VERSION "created by canmatrix"

NS_ :

BS_:

BU_: HUT T_BOX GW XBOX_D CEM Tester

BO_ 653 BCM7: 8 CEM
 SG_ SecRowLeSeatVentSts : 15|2@0+ (1,0) [0|3] "" HUT
 SG_ SecRowRiSeatVentSts : 13|2@0+ (1,0) [0|3] "" HUT

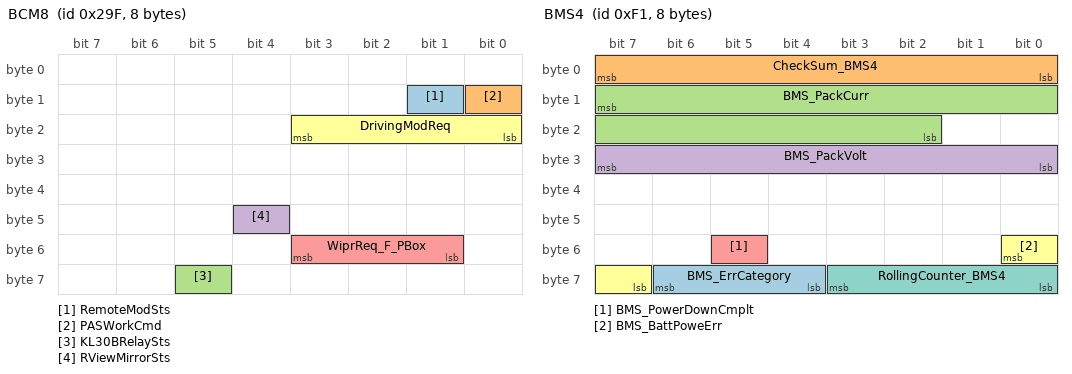
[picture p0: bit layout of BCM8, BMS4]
BO_ 671 BCM8: 8 CEM
 SG_ RemoteModSts : 9|1@0+ (1,0) [0|1] "1.0" HUT,T_BOX
 SG_ PASWorkCmd : 8|1@0+ (1,0) [0|1] "" HUT
 SG_ KL30BRelaySts : 61|1@0+ (1,0) [0|1] "" HUT
 SG_ RViewMirrorSts : 44|1@0+ (1,0) [0|1] "" HUT
 SG_ WiprReq_F_PBox : 51|3@0+ (1,0) [0|7] "" HUT
 SG_ DrivingModReq : 19|4@0+ (1,0) [0|15] "" HUT

BO_ 845 BCM18: 8 CEM
 SG_ ColMemPosnSetSwtFB : 15|3@0+ (1,0) [0|7] "" HUT

BO_ 241 BMS4: 8 GW
 SG_ BMS_ErrCategory : 62|3@0+ (1,0) [0|7] "" HUT
 SG_ CheckSum_BMS4 : 7|8@0+ (1,0) [0|255] "" HUT
 SG_ BMS_PackCurr : 15|14@0+ (0.2,-1000) [-1000|1000] "A" HUT
 SG_ BMS_PackVolt : 31|8@0+ (2,0) [0|490] "V" HUT
 SG_ BMS_PowerDownCmplt : 53|1@0+ (1,0) [0|1] "" HUT
 SG_ BMS_BattPoweErr : 48|2@0+ (1,0) [0|3] "" HUT
 SG_ RollingCounter_BMS4 : 59|4@0+ (1,0) [0|15] "" HUT

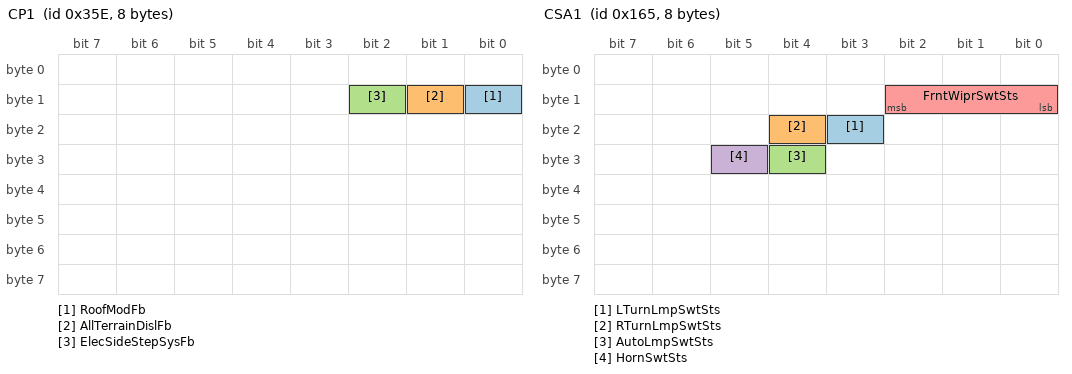
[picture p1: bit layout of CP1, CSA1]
BO_ 862 CP1: 8 CEM
 SG_ RoofModFb : 8|1@0+ (1,0) [0|1] "" HUT
 SG_ AllTerrainDislFb : 9|1@0+ (1,0) [0|1] "" HUT
 SG_ ElecSideStepSysFb : 10|1@0+ (1,0) [0|1] "" HUT

BO_ 350 CR_FD1: 64 GW
 SG_ CR_FCTA_Resp : 79|1@0+ (1,0) [0|1] "" HUT
 SG_ CR_FCTB_Resp : 78|1@0+ (1,0) [0|1] "" HUT
 SG_ CR_BliSts : 86|1@0+ (1,0) [0|1] "" HUT
 SG_ FCTA_Warn : 75|1@0+ (1,0) [0|1] "" HUT
 SG_ FCTBTrig : 83|1@0+ (1,0) [0|1] "" HUT
 SG_ FCTA_B_FuncSts : 77|2@0+ (1,0) [0|3] "" HUT
 SG_ FCTA_B_TTC : 110|6@0+ (0.1,0) [0|6.3] "s" HUT

BO_ 357 CSA1: 8 GW
 SG_ LTurnLmpSwtSts : 19|1@0+ (1,0) [0|1] "" HUT
 SG_ RTurnLmpSwtSts : 20|1@0+ (1,0) [0|1] "" HUT
 SG_ AutoLmpSwtSts : 28|1@0+ (1,0) [0|1] "" HUT,T_BOX
 SG_ HornSwtSts : 29|1@0+ (1,0) [0|1] "" HUT
 SG_ FrntWiprSwtSts : 10|3@0+ (1,0) [0|7] "" HUT

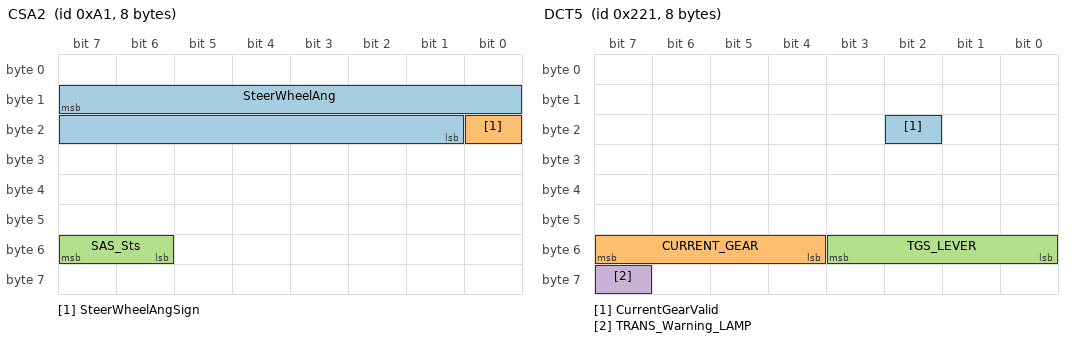
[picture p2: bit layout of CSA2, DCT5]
BO_ 161 CSA2: 8 GW
 SG_ SteerWheelAng : 15|15@0+ (0.1,0) [0|780] "deg" HUT,T_BOX
 SG_ SteerWheelAngSign : 16|1@0+ (1,0) [0|1] "" HUT,T_BOX
 SG_ SAS_Sts : 55|2@0+ (1,0) [0|3] "" HUT,T_BOX

BO_ 580 CSA3: 8 GW
 SG_ MenuReturnSwtSts : 49|2@0+ (1,0) [0|3] "" HUT
 SG_ SteerWheelHeatdSts : 40|1@0+ (1,0) [0|1] "" HUT
 SG_ HomeSwtSts : 51|2@0+ (1,0) [0|3] "" HUT
 SG_ MuteSwtSts : 53|2@0+ (1,0) [0|3] "" HUT
 SG_ CustomSwtSts : 55|2@0+ (1,0) [0|3] "" HUT
 SG_ PageUpSwtSts : 15|2@0+ (1,0) [0|3] "" HUT
 SG_ PageDwnSwtSts : 13|2@0+ (1,0) [0|3] "" HUT
 SG_ PageLSwtSts : 11|2@0+ (1,0) [0|3] "" HUT
 SG_ PageRSwtSts : 9|2@0+ (1,0) [0|3] "" HUT
 SG_ SeekUpSwtSts : 63|2@0+ (1,0) [0|3] "" HUT
 SG_ SeekDwnSwtSts : 61|2@0+ (1,0) [0|3] "" HUT
 SG_ AdjVolUpSwtSts : 23|2@0+ (1,0) [0|3] "" HUT
 SG_ AdjVolDwnSwtSts : 21|2@0+ (1,0) [0|3] "" HUT
 SG_ VRSwtSts : 19|2@0+ (1,0) [0|3] "" HUT
 SG_ EnterSwtSts : 31|2@0+ (1,0) [0|3] "" HUT
 SG_ EnterSwtSts_Mmed : 27|2@0+ (1,0) [0|3] "" HUT
 SG_ CustomSwtSts_Mmed : 39|2@0+ (1,0) [0|3] "" HUT
 SG_ IpMenuSwtSts : 42|2@0+ (1,0) [0|3] "" HUT

BO_ 566 DCT_FD4: 64 TCU
 SG_ CheckSum_DCT7 : 71|8@0+ (1,0) [0|255] "" HUT
 SG_ TrsmStNID : 106|3@0+ (1,0) [0|7] "" HUT
 SG_ DCT_RaceModeSts : 74|3@0+ (1,0) [0|7] "" HUT
 SG_ TRANS_OIL_TEMP : 87|8@0+ (1,-40) [-40|214] "Ã¢Â„Âƒ" HUT
 SG_ DCT_PrsBrk_Warn : 95|2@0+ (1,0) [0|3] "" HUT
 SG_ DCT_ShftNotAlwd_Warn : 93|2@0+ (1,0) [0|3] "" HUT
 SG_ DCT_ShftRecom_M : 91|2@0+ (1,0) [0|3] "" HUT
 SG_ DrvWarnMsg : 103|3@0+ (1,0) [0|7] "" HUT
 SG_ DrvFaiMsg : 100|4@0+ (1,0) [0|15] "" HUT
 SG_ DrvModDisp : 111|3@0+ (1,0) [0|7] "" HUT
 SG_ DrvModDispSts : 108|2@0+ (1,0) [0|3] "" HUT
 SG_ DrvAutoGearDisp : 127|4@0+ (1,0) [0|15] "" HUT,T_BOX
 SG_ DrvGearDispSts : 119|2@0+ (1,0) [0|3] "" HUT
 SG_ RollingCounter_DCT7 : 123|4@0+ (1,0) [0|15] "" HUT

BO_ 166 DCT3: 8 GW
 SG_ TgtEngSpdIP : 47|12@0+ (2,0) [0|8190] "RPM" HUT
 SG_ TgtEngSpdIPValid : 50|1@0+ (1,0) [0|1] "" HUT

BO_ 545 DCT5: 8 GW
 SG_ CurrentGearValid : 18|1@0+ (1,0) [0|1] "" HUT
 SG_ CURRENT_GEAR : 55|4@0+ (1,0) [0|15] "" HUT,T_BOX
 SG_ TGS_LEVER : 51|4@0+ (1,0) [0|15] "" HUT,T_BOX
 SG_ TRANS_Warning_LAMP : 63|1@0+ (1,0) [0|1] "" HUT

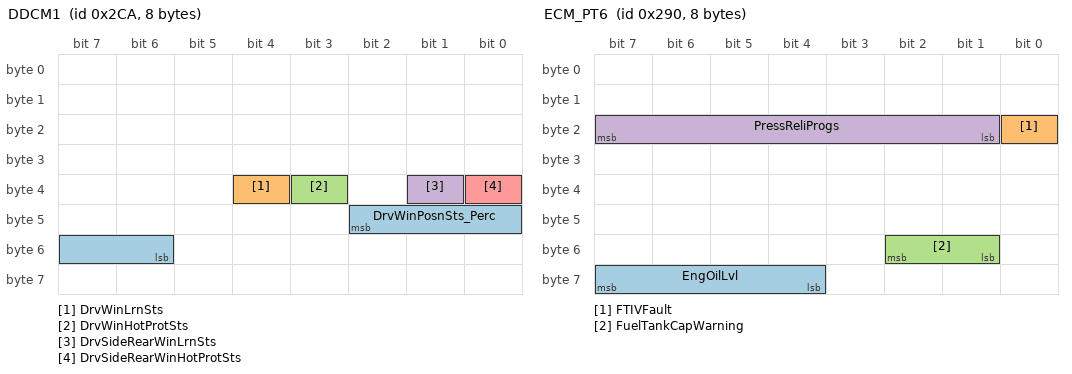
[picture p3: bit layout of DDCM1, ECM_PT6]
BO_ 714 DDCM1: 8 GW
 SG_ DrvWinPosnSts_Perc : 42|5@0+ (1,0) [0|31] "" HUT,T_BOX
 SG_ DrvWinLrnSts : 36|1@0+ (1,0) [0|1] "" HUT,T_BOX
 SG_ DrvWinHotProtSts : 35|1@0+ (1,0) [0|1] "" HUT,T_BOX
 SG_ DrvSideRearWinLrnSts : 33|1@0+ (1,0) [0|1] "" HUT,T_BOX
 SG_ DrvSideRearWinHotProtSts : 32|1@0+ (1,0) [0|1] "" HUT,T_BOX

BO_ 759 DDCM3: 8 GW
 SG_ DrvSideRearWinPosnSts_Perc : 15|5@0+ (1,0) [0|31] "" HUT,T_BOX

BO_ 589 DMS_FD1: 64 HUT
 SG_ DrowsnsLvl : 13|3@0+ (1,0) [0|7] "" CEM
 SG_ DrowsnsLvlQlty : 10|7@0+ (1,0) [0|100] "%" CEM
 SG_ GenderSts : 36|2@0+ (1,0) [0|3] "" CEM
 SG_ GenderStsQlty : 47|7@0+ (1,0) [0|100] "%" CEM
 SG_ ExprsnSts : 34|3@0+ (1,0) [0|7] "" GW
 SG_ Checksum_DMS2 : 71|8@0+ (1,0) [0|255] "" GW
 SG_ DistrctnLvl_ACC : 95|3@0+ (1,0) [0|7] "" GW
 SG_ DistrctnLvlQlty_ACC : 79|7@0+ (1,0) [0|100] "%" GW
 SG_ DrowsnsLvl_ACC : 92|3@0+ (1,0) [0|7] "" GW
 SG_ DrowsnsLvlQlty_ACC : 87|7@0+ (1,0) [0|100] "%" GW
 SG_ RollingCounter_DMS2 : 123|4@0+ (1,0) [0|15] "" GW
 SG_ Checksum_DMS3 : 135|8@0+ (1,0) [0|255] "" GW
 SG_ HeadPosnX : 143|11@0+ (1,-500) [-500|1000] "mm" GW
 SG_ HeadPosnY : 148|11@0+ (1,-500) [-500|500] "mm" GW
 SG_ HeadPosnZ : 153|11@0+ (1,-500) [-500|500] "mm" GW
 SG_ HeadPosQlty : 174|7@0+ (1,0) [0|100] "%" GW
 SG_ RollingCounter_DMS3 : 187|4@0+ (1,0) [0|15] "" GW
 SG_ GazePosnX : 207|11@0+ (1,-500) [-500|1000] "mm" GW
 SG_ GazePosnY : 212|11@0+ (1,-500) [-500|500] "mm" GW
 SG_ GazePosnZ : 217|11@0+ (1,-500) [-500|500] "mm" GW
 SG_ Checksum_DMS5 : 263|8@0+ (1,0) [0|255] "" GW
 SG_ DMSSts : 303|3@0+ (1,0) [0|7] "" GW
 SG_ HeadDetn : 288|1@0+ (1,0) [0|1] "" GW
 SG_ HeadYawAng : 271|8@0+ (1,-75) [-75|75] "degree" GW
 SG_ HeadPitchAng : 279|8@0+ (1,-25) [-25|45] "degree" GW
 SG_ HeadRollAng : 287|8@0+ (1,-45) [-45|45] "degree" GW
 SG_ HeadRotAngQlty : 295|7@0+ (1,0) [0|100] "%" GW
 SG_ RollingCounter_DMS5 : 315|4@0+ (1,0) [0|15] "" GW
 SG_ Checksum_DMS6 : 327|8@0+ (1,0) [0|255] "" GW
 SG_ LEyeOpenSts : 375|2@0+ (1,0) [0|3] "" GW
 SG_ LEyeOpenStsQlty : 351|7@0+ (1,0) [0|100] "%" GW
 SG_ REyeOpenSts : 373|2@0+ (1,0) [0|3] "" GW
 SG_ REyeOpenStsQlty : 359|7@0+ (1,0) [0|100] "%" GW
 SG_ RobustGazeYawAng : 335|8@0+ (1,-90) [-90|90] "degree" GW
 SG_ RobustGazePitchAng : 343|8@0+ (1,-90) [-90|90] "degree" GW
 SG_ RobustGazeAngQlty : 367|7@0+ (1,0) [0|100] "%" GW
 SG_ DrvBehvSts : 370|3@0+ (1,0) [0|7] "" GW
 SG_ RollingCounter_DMS6 : 379|4@0+ (1,0) [0|15] "" GW

BO_ 705 DSM1: 8 CEM
 SG_ ChairMemPosnSetSwtFB : 11|3@0+ (1,0) [0|7] "" HUT

BO_ 748 DVR_FD1: 64 HUT
 SG_ DVR_360VideoCaptureReq : 9|1@0+ (1,0) [0|1] "" GW
 SG_ DVRRemtCnSts : 28|3@0+ (1,0) [0|7] "" T_BOX
 SG_ DVRSN : 71|48@0+ (1,0) [0|1] "" T_BOX
 SG_ DVRSts : 15|4@0+ (1,0) [0|15] "" GW

BO_ 656 ECM_PT6: 8 GW
 SG_ EngOilLvl : 63|4@0+ (1,0) [0|15] "" HUT
 SG_ FTIVFault : 16|1@0+ (1,0) [0|1] "" HUT
 SG_ FuelTankCapWarning : 50|2@0+ (1,0) [0|3] "" HUT
 SG_ PressReliProgs : 23|7@0+ (1,0) [0|100] "%" HUT

BO_ 273 ECM1: 8 GW
 SG_ EMS_AuthenResult : 25|2@0+ (1,0) [0|3] "" HUT
 SG_ EngSpd : 47|16@0+ (0.125,0) [0|8191.875] "rpm" HUT,T_BOX
 SG_ EngSpdVldty : 63|2@0+ (1,0) [0|2] "" HUT,T_BOX
 SG_ EngSpd_PHEV : 47|16@0+ (0.125,0) [0|8191.875] "rpm" HUT,T_BOX
 SG_ EngSpdVldty_PHEV : 63|2@0+ (1,0) [0|2] "" HUT,T_BOX

BO_ 723 ECM11: 8 GW
 SG_ EngSpd_ForIP : 47|16@0+ (0.125,0) [0|8191.875] "rpm" HUT
 SG_ EWP_Err : 32|1@0+ (1,0) [0|1] "" HUT

BO_ 949 ECM19: 8 GW
 SG_ ECM_VIN : 7|64@0+ (1,0) [0|1.84467440737096E+019] "" HUT

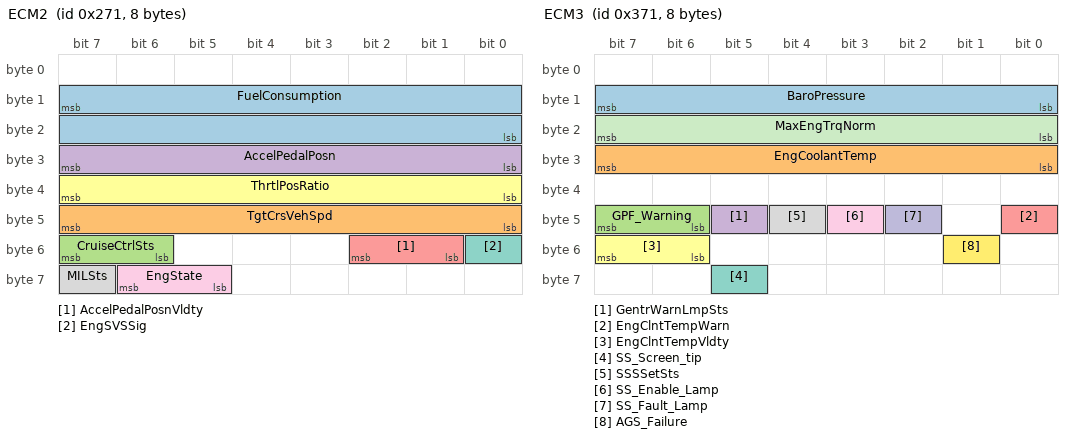
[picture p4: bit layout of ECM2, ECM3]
BO_ 625 ECM2: 8 GW
 SG_ FuelConsumption : 15|16@0+ (2,0) [0|131070] "ÃŽÂ¼l" HUT
 SG_ TgtCrsVehSpd : 47|8@0+ (1,0) [0|255] "kphmph" HUT
 SG_ CruiseCtrlSts : 55|2@0+ (1,0) [0|2] "" HUT
 SG_ AccelPedalPosn : 31|8@0+ (0.3937,0) [0|100.3935] "%" HUT
 SG_ AccelPedalPosnVldty : 50|2@0+ (1,0) [0|2] "" HUT
 SG_ ThrtlPosRatio : 39|8@0+ (0.3937,0) [0|99.9998] "%" HUT
 SG_ EngSVSSig : 48|1@0+ (1,0) [0|1] "" HUT
 SG_ MILSts : 63|1@0+ (1,0) [0|1] "" HUT
 SG_ EngState : 62|2@0+ (1,0) [0|3] "" HUT,XBOX_D,T_BOX

BO_ 951 ECM20: 8 GW
 SG_ ECM_VehDstBackup : 7|24@0+ (0.1,0) [0|999999.9] "Km" HUT

BO_ 881 ECM3: 8 GW
 SG_ BaroPressure : 15|8@0+ (0.59,0) [0|149.86] "kPa" HUT
 SG_ EngCoolantTemp : 31|8@0+ (0.75,-48) [-48|143.25] "Deg C" HUT,T_BOX
 SG_ GPF_Warning : 47|2@0+ (1,0) [0|3] "" HUT
 SG_ GentrWarnLmpSts : 45|1@0+ (1,0) [0|1] "" HUT
 SG_ EngClntTempWarn : 40|1@0+ (1,0) [0|1] "" HUT,T_BOX
 SG_ EngClntTempVldty : 55|2@0+ (1,0) [0|2] "" HUT,T_BOX
 SG_ SS_Screen_tip : 61|1@0+ (1,0) [0|1] "" HUT
 SG_ SSSSetSts : 44|1@0+ (1,0) [0|1] "" HUT
 SG_ SS_Enable_Lamp : 43|1@0+ (1,0) [0|1] "" HUT
 SG_ SS_Fault_Lamp : 42|1@0+ (1,0) [0|1] "" HUT
 SG_ MaxEngTrqNorm : 23|8@0+ (5,0) [0|650] "Nm" HUT
 SG_ AGS_Failure : 49|1@0+ (1,0) [0|1] "" HUT

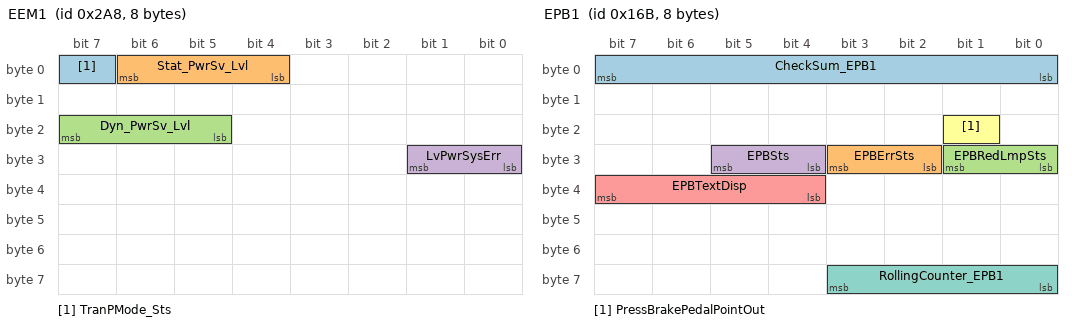
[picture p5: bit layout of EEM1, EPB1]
BO_ 680 EEM1: 8 CEM
 SG_ TranPMode_Sts : 7|1@0+ (1,0) [0|1] "" HUT,T_BOX
 SG_ Stat_PwrSv_Lvl : 6|3@0+ (1,0) [0|7] "" HUT
 SG_ Dyn_PwrSv_Lvl : 23|3@0+ (1,0) [0|7] "" HUT
 SG_ LvPwrSysErr : 25|2@0+ (1,0) [0|3] "" HUT

BO_ 338 ELD1: 8 GW
 SG_ FrntELDLckSts : 35|4@0+ (1,0) [0|15] "" HUT
 SG_ RearELDLckSts : 39|4@0+ (1,0) [0|15] "" HUT

BO_ 363 EPB1: 8 GW
 SG_ CheckSum_EPB1 : 7|8@0+ (1,0) [0|255] "" HUT
 SG_ EPBErrSts : 27|2@0+ (1,0) [0|3] "" HUT
 SG_ EPBRedLmpSts : 25|2@0+ (1,0) [0|3] "" HUT
 SG_ EPBSts : 29|2@0+ (1,0) [0|3] "" HUT
 SG_ EPBTextDisp : 39|4@0+ (1,0) [0|15] "" HUT
 SG_ PressBrakePedalPointOut : 17|1@0+ (1,0) [0|1] "" HUT
 SG_ RollingCounter_EPB1 : 59|4@0+ (1,0) [0|15] "" HUT

BO_ 327 EPS_FD1: 64 GW
 SG_ CheckSum_EPS1 : 7|8@0+ (1,0) [0|255] "" HUT
 SG_ EPS_FailSts : 13|2@0+ (1,0) [0|3] "" HUT
 SG_ EPS_SteerMod : 55|3@0+ (1,0) [0|7] "" HUT
 SG_ SteerCorrnRmn : 63|2@0+ (1,0) [0|3] "" HUT
 SG_ SteerCorrnResp : 61|1@0+ (1,0) [0|1] "" HUT
 SG_ RollingCounter_EPS1 : 59|4@0+ (1,0) [0|15] "" HUT

BO_ 771 ESCL2: 8 GW
 SG_ RotSteerWheel : 21|1@0+ (1,0) [0|1] "" HUT

BO_ 311 ESP_FD2: 64 ESP
 SG_ CheckSum_ESP2 : 71|8@0+ (1,0) [0|255] "" HUT
 SG_ HDCFault : 89|2@0+ (1,0) [0|3] "" HUT
 SG_ HDCCtrl : 91|2@0+ (1,0) [0|3] "" HUT
 SG_ AVHErrSts : 99|2@0+ (1,0) [0|3] "" HUT
 SG_ AVHSts : 101|2@0+ (1,0) [0|3] "" HUT
 SG_ CDPActv : 103|1@0+ (1,0) [0|1] "" HUT
 SG_ DrivingModDis : 119|5@0+ (1,0) [0|31] "" HUT
 SG_ DrivingModReq_ESP : 96|5@0+ (1,0) [0|31] "" HUT
 SG_ Shift_N_Warn : 114|1@0+ (1,0) [0|1] "" HUT
 SG_ Over_Spd_Warn : 107|1@0+ (1,0) [0|1] "" HUT
 SG_ FourL_Warn : 106|1@0+ (1,0) [0|1] "" HUT
 SG_ TAB_Sts : 113|2@0+ (1,0) [0|3] "" HUT
 SG_ RollingCounter_ESP2 : 123|4@0+ (1,0) [0|15] "" HUT
 SG_ CheckSum_ESP1 : 135|8@0+ (1,0) [0|255] "" HUT
 SG_ ESPFuncOffSts : 140|1@0+ (1,0) [0|1] "" HUT
 SG_ ESPActvInfoLmp : 141|1@0+ (1,0) [0|1] "" HUT
 SG_ ESPFailSts : 143|1@0+ (1,0) [0|1] "" HUT
 SG_ IMC_Actv : 175|1@0+ (1,0) [0|1] "" HUT
 SG_ RollingCounter_ESP1 : 187|4@0+ (1,0) [0|15] "" HUT
 SG_ CheckSum_ABS3 : 327|8@0+ (1,0) [0|255] "" HUT
 SG_ ABSActv : 347|1@0+ (1,0) [0|1] "" HUT,T_BOX
 SG_ ABSFailSts : 335|1@0+ (1,0) [0|1] "" HUT,T_BOX
 SG_ EBDFailSts : 334|1@0+ (1,0) [0|1] "" HUT
 SG_ VehSpdVld : 333|1@0+ (1,0) [0|1] "" HUT,T_BOX
 SG_ VehSpd : 332|13@0+ (0.05625,0) [0|299.98125] "kph" HUT,T_BOX
 SG_ VehOdoInfoSts : 346|1@0+ (1,0) [0|1] "" HUT
 SG_ VehOdoInfo : 345|10@0+ (1,0) [0|999] "m" HUT
 SG_ RollingCounter_ABS3 : 379|4@0+ (1,0) [0|15] "" HUT
 SG_ FreshnessValue_ESP_FD2 : 455|16@0+ (1,0) [0|65535] "" HUT
 SG_ MAC_Check_ESP_FD2 : 471|48@0+ (1,0) [0|281474976710655] "" HUT

BO_ 200 ESP11: 8 GW
 SG_ ESP_HMI_WarningOn : 41|2@0+ (1,0) [0|3] "" HUT
 SG_ WadeModeWarn : 45|2@0+ (1,0) [0|3] "" HUT

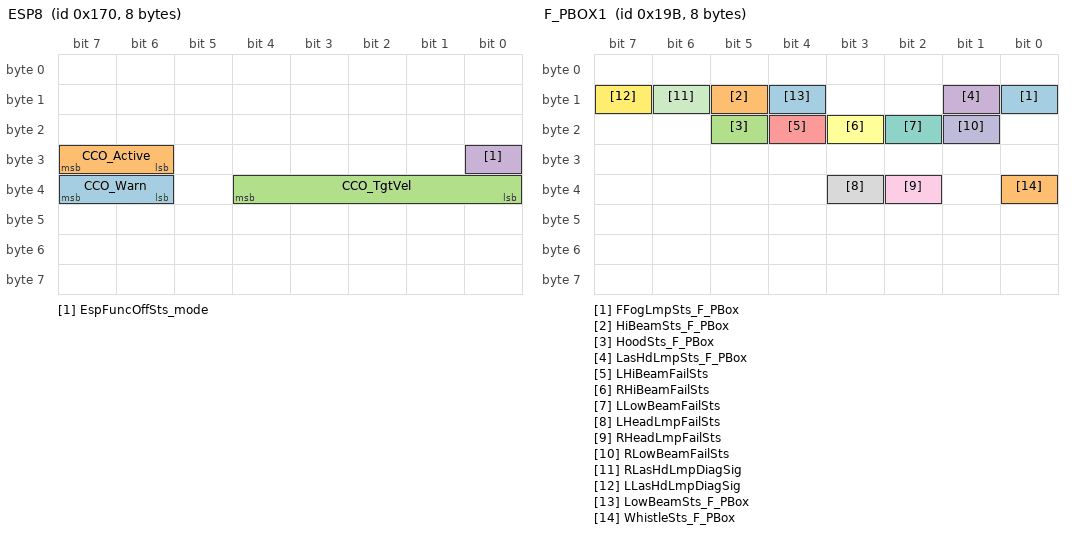
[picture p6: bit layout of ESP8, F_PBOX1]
BO_ 368 ESP8: 8 GW
 SG_ CCO_Warn : 39|2@0+ (1,0) [0|3] "" HUT
 SG_ CCO_Active : 31|2@0+ (1,0) [0|3] "" HUT
 SG_ CCO_TgtVel : 36|5@0+ (1,2.6) [2.6|33.6] "kph" HUT
 SG_ EspFuncOffSts_mode : 24|1@0+ (1,0) [0|1] "" HUT

BO_ 411 F_PBOX1: 8 CEM
 SG_ FFogLmpSts_F_PBox : 8|1@0+ (1,0) [0|1] "" HUT,T_BOX
 SG_ HiBeamSts_F_PBox : 13|1@0+ (1,0) [0|1] "" HUT,T_BOX
 SG_ HoodSts_F_PBox : 21|1@0+ (1,0) [0|1] "" HUT,T_BOX
 SG_ LasHdLmpSts_F_PBox : 9|1@0+ (1,0) [0|1] "" HUT
 SG_ LHiBeamFailSts : 20|1@0+ (1,0) [0|1] "" HUT,T_BOX
 SG_ RHiBeamFailSts : 19|1@0+ (1,0) [0|1] "" HUT,T_BOX
 SG_ LLowBeamFailSts : 18|1@0+ (1,0) [0|1] "" HUT,T_BOX
 SG_ LHeadLmpFailSts : 35|1@0+ (1,0) [0|1] "" HUT
 SG_ RHeadLmpFailSts : 34|1@0+ (1,0) [0|1] "" HUT
 SG_ RLowBeamFailSts : 17|1@0+ (1,0) [0|1] "" HUT,T_BOX
 SG_ RLasHdLmpDiagSig : 14|1@0+ (1,0) [0|1] "" HUT
 SG_ LLasHdLmpDiagSig : 15|1@0+ (1,0) [0|1] "" HUT
 SG_ LowBeamSts_F_PBox : 12|1@0+ (1,0) [0|1] "" HUT,T_BOX
 SG_ WhistleSts_F_PBox : 32|1@0+ (1,0) [0|1] "" HUT

BO_ 699 GW_FD1: 64 CEM
 SG_ U_BATT : 71|14@0+ (0.0009765625,3) [3|18] "V" HUT,T_BOX
 SG_ I_RANGE : 73|2@0+ (1,0) [0|3] "" HUT
 SG_ I_BATT : 87|16@0+ (1,-32768) [-32768|32767] "A" HUT
 SG_ SOC : 135|8@0+ (1,0) [0|100] "%" HUT,T_BOX
 SG_ SOH_SUL : 143|8@0+ (1,0) [0|100] "%" HUT
 SG_ SOC_STATE : 183|2@0+ (1,0) [0|3] "" HUT
 SG_ SOH_SUL_STATE : 181|2@0+ (1,0) [0|3] "" HUT
 SG_ OTA_UpgrdModSts : 343|2@0+ (1,0) [0|3] "" HUT,T_BOX
 SG_ CheckSum_GWM1 : 327|8@0+ (1,0) [0|255] "" HUT,T_BOX
 SG_ RollingCounter_GWM1 : 379|4@0+ (1,0) [0|15] "" HUT,T_BOX

BO_ 347 HAP_FD1: 64 GW
 SG_ APS_PrkgMod : 117|2@0+ (1,0) [0|3] "" HUT
 SG_ APS_ProcBar : 111|7@0+ (1,0) [0|127] "%" HUT
 SG_ APS_SwtSts : 104|1@0+ (1,0) [0|1] "" HUT
 SG_ APS_SlotDisp : 76|3@0+ (1,0) [0|7] "" HUT
 SG_ APS_SysSoundIndcn : 79|3@0+ (1,0) [0|7] "" HUT
 SG_ APS_PrkgTyp : 119|2@0+ (1,0) [0|3] "" HUT
 SG_ APS_TextDisp : 103|8@0+ (1,0) [0|255] "" HUT
 SG_ APS_WorkSts : 146|3@0+ (1,0) [0|7] "" HUT
 SG_ MEB_AVHReq : 168|1@0+ (1,0) [0|1] "" HUT
 SG_ APS_ESP_BrkDistance : 167|12@0+ (1,0) [0|4095] "cm" HUT
 SG_ LParaPrkgOutVald : 283|1@0+ (1,0) [0|1] "" HUT
 SG_ RParaPrkgOutVald : 282|1@0+ (1,0) [0|1] "" HUT
 SG_ HeadVertPrkgOutVald : 281|1@0+ (1,0) [0|1] "" HUT
 SG_ TailVertPrkgOutVald : 280|1@0+ (1,0) [0|1] "" HUT
 SG_ HAP_SwtDispCtrlCmd : 279|3@0+ (1,0) [0|7] "" HUT
 SG_ HAP_PrkgModCurrSts : 269|4@0+ (1,0) [0|15] "" HUT
 SG_ APS_MovgDirc : 295|2@0+ (1,0) [0|3] "" HUT
 SG_ ParallelSlotBtn_Ena : 367|2@0+ (1,0) [0|3] "" HUT
 SG_ VerticalSlotBtn_Ena : 365|2@0+ (1,0) [0|3] "" HUT
 SG_ ClockwiseBtn_Ena : 363|2@0+ (1,0) [0|3] "" HUT
 SG_ AnticlockwiseBtn_Ena : 361|2@0+ (1,0) [0|3] "" HUT
 SG_ SlotConfirmBtn_Ena : 375|2@0+ (1,0) [0|3] "" HUT
 SG_ HAVP_StopBtn_Ena : 329|2@0+ (1,0) [0|3] "" HUT
 SG_ HAVP_StartBtn_Ena : 331|2@0+ (1,0) [0|3] "" HUT
 SG_ HAVP_SelfParLotEnding_Ena : 339|2@0+ (1,0) [0|3] "" HUT
 SG_ PAVP_TextDis : 351|6@0+ (1,0) [0|63] "" HUT

BO_ 628 HAP_FD2: 64 GW
 SG_ AutoAVMSwtSet_Sts : 83|1@0+ (1,0) [0|1] "" HUT
 SG_ AVM_CurrSts : 79|2@0+ (1,0) [0|3] "" HUT
 SG_ GuidOvlSts : 95|2@0+ (1,0) [0|3] "" HUT
 SG_ FrntCamInpFailSts : 108|1@0+ (1,0) [0|1] "" HUT
 SG_ RearCamInpFailSts : 109|1@0+ (1,0) [0|1] "" HUT
 SG_ LeCamInpFailSts : 110|1@0+ (1,0) [0|1] "" HUT
 SG_ RiCamInpFailSts : 111|1@0+ (1,0) [0|1] "" HUT
 SG_ EolNotCmpltd : 107|1@0+ (1,0) [0|1] "" HUT
 SG_ OvlOpFailSts : 105|1@0+ (1,0) [0|1] "" HUT
 SG_ LaneCalSts : 101|2@0+ (1,0) [0|3] "" HUT
 SG_ RadarDispSts : 93|2@0+ (1,0) [0|3] "" HUT
 SG_ LaneCalFltSts : 99|3@0+ (1,0) [0|7] "" HUT
 SG_ AutoViewChgFuncSts : 84|1@0+ (1,0) [0|1] "" HUT
 SG_ CarMdlTrsprcySts : 103|2@0+ (1,0) [0|3] "" HUT
 SG_ CarMdlDispSts : 85|1@0+ (1,0) [0|1] "" HUT
 SG_ CurrCalResultSts : 96|1@0+ (1,0) [0|1] "" HUT
 SG_ MdlColrSts : 91|4@0+ (1,0) [0|15] "" HUT
 SG_ SigViewIndcn : 77|6@0+ (1,0) [0|63] "" HUT
 SG_ HAP_DispCmd : 127|1@0+ (1,0) [0|1] "" HUT
 SG_ AVM_3DAngSts : 104|9@0+ (1,0) [0|360] "deg" HUT
 SG_ MOD_WorkSts : 87|1@0+ (1,0) [0|1] "" HUT
 SG_ MOD_AlarmSts : 86|1@0+ (1,0) [0|1] "" HUT
 SG_ DVRWorkSts : 126|2@0+ (1,0) [0|3] "" HUT
 SG_ HAP_Hmi_Index : 143|4@0+ (1,0) [0|15] "" HUT

BO_ 664 HAP_FD3: 64 GW
 SG_ RPAS_NearBrrdstn : 15|8@0+ (1,0) [0|150] "" HUT
 SG_ HAVP_ProcRa : 23|7@0+ (1,0) [0|127] "" HUT
 SG_ APS_ObjRiSideAr1 : 79|4@0+ (1,0) [0|15] "" HUT
 SG_ APS_ObjRiSideAr2 : 75|4@0+ (1,0) [0|15] "" HUT
 SG_ APS_ObjRiSideAr3 : 87|4@0+ (1,0) [0|15] "" HUT
 SG_ APS_ObjRiSideAr4 : 83|4@0+ (1,0) [0|15] "" HUT
 SG_ APS_ObjRiSideAr5 : 95|4@0+ (1,0) [0|15] "" HUT
 SG_ APS_ObjLeSideAr1 : 91|4@0+ (1,0) [0|15] "" HUT
 SG_ APS_ObjLeSideAr2 : 103|4@0+ (1,0) [0|15] "" HUT
 SG_ APS_ObjLeSideAr3 : 99|4@0+ (1,0) [0|15] "" HUT
 SG_ APS_ObjLeSideAr4 : 111|4@0+ (1,0) [0|15] "" HUT
 SG_ APS_ObjLeSideAr5 : 107|4@0+ (1,0) [0|15] "" HUT
 SG_ APS_FRSideSnsrFailSts : 119|1@0+ (1,0) [0|1] "" HUT
 SG_ APS_FLSideSnsrFailSts : 118|1@0+ (1,0) [0|1] "" HUT
 SG_ APS_RRSideSnsrFailSts : 117|1@0+ (1,0) [0|1] "" HUT
 SG_ APS_RLSideSnsrFailSts : 116|1@0+ (1,0) [0|1] "" HUT
 SG_ SDW_SoundIndcn : 115|2@0+ (1,0) [0|3] "" HUT
 SG_ SDWActiveSts : 112|1@0+ (1,0) [0|1] "" HUT
 SG_ RPAS_ObjRRCornrAr1 : 143|4@0+ (1,0) [0|15] "" HUT
 SG_ RPAS_ObjRRCornrAr2 : 139|4@0+ (1,0) [0|15] "" HUT
 SG_ RPAS_ObjRRMidlAr1 : 151|4@0+ (1,0) [0|15] "" HUT
 SG_ RPAS_ObjRRMidlAr2 : 147|4@0+ (1,0) [0|15] "" HUT
 SG_ RPAS_ObjRLMidlAr1 : 159|4@0+ (1,0) [0|15] "" HUT
 SG_ RPAS_ObjRLMidlAr2 : 155|4@0+ (1,0) [0|15] "" HUT
 SG_ RPAS_ObjRLCornrAr1 : 167|4@0+ (1,0) [0|15] "" HUT
 SG_ RPAS_ObjRLCornrAr2 : 163|4@0+ (1,0) [0|15] "" HUT
 SG_ RPAS_RLCornrSnsrFailSts : 175|1@0+ (1,0) [0|1] "" HUT
 SG_ RPAS_RLMiddlSnsrFailSts : 174|1@0+ (1,0) [0|1] "" HUT
 SG_ RPAS_RRMiddlSnsrFailSts : 173|1@0+ (1,0) [0|1] "" HUT
 SG_ RPAS_RRCornrSnsrFailSts : 172|1@0+ (1,0) [0|1] "" HUT
 SG_ RPAS_WorkSts : 171|2@0+ (1,0) [0|3] "" HUT
 SG_ RPAS_SoundIndcn : 183|2@0+ (1,0) [0|3] "" HUT
 SG_ MEBWorkSts : 180|2@0+ (1,0) [0|3] "" HUT
 SG_ MEB_EnableSts : 178|1@0+ (1,0) [0|1] "" HUT
 SG_ FPAS_ObjFLCornrAr1 : 207|4@0+ (1,0) [0|15] "" HUT
 SG_ FPAS_ObjFLCornrAr2 : 203|4@0+ (1,0) [0|15] "" HUT
 SG_ FPAS_ObjFLMidlAr1 : 215|4@0+ (1,0) [0|15] "" HUT
 SG_ FPAS_ObjFLMidlAr2 : 211|4@0+ (1,0) [0|15] "" HUT
 SG_ FPAS_ObjFRMidlAr1 : 223|4@0+ (1,0) [0|15] "" HUT
 SG_ FPAS_ObjFRMidlAr2 : 219|4@0+ (1,0) [0|15] "" HUT
 SG_ FPAS_ObjFRCornrAr1 : 231|4@0+ (1,0) [0|15] "" HUT
 SG_ FPAS_ObjFRCornrAr2 : 227|4@0+ (1,0) [0|15] "" HUT
 SG_ FPAS_FLCornrSnsrFailSts : 239|1@0+ (1,0) [0|1] "" HUT
 SG_ FPAS_FLMiddlSnsrFailSts : 238|1@0+ (1,0) [0|1] "" HUT
 SG_ FPAS_FRMiddlSnsrFailSts : 237|1@0+ (1,0) [0|1] "" HUT
 SG_ FPAS_FRCornrSnsrFailSts : 236|1@0+ (1,0) [0|1] "" HUT
 SG_ FPAS_WorkSts : 235|2@0+ (1,0) [0|3] "" HUT
 SG_ FPAS_AutoModSts : 232|1@0+ (1,0) [0|1] "" HUT
 SG_ FPAS_SoundIndcn : 247|2@0+ (1,0) [0|3] "" HUT
 SG_ FPAS_NearBrrdstn : 242|7@0+ (1,0) [0|100] "" HUT
 SG_ APA_MenuDispCtrlCmd : 279|4@0+ (1,0) [0|15] "" HUT
 SG_ APA_FuncSts : 271|2@0+ (1,0) [0|3] "" HUT
 SG_ RADS_FuncSts : 267|2@0+ (1,0) [0|3] "" HUT
 SG_ FADS_FuncSts : 265|2@0+ (1,0) [0|3] "" HUT
 SG_ HAP_TextIconDispCtrl : 275|2@0+ (1,0) [0|3] "" HUT

BO_ 649 HAP_FD6: 64 GW
 SG_ HAP_RtCam_WorkSts : 61|2@0+ (1,0) [0|3] "" HUT
 SG_ HAP_RtSide_Obj1_ID : 15|4@0+ (1,0) [0|3] "" HUT
 SG_ HAP_RtSide_Obj1_type : 11|3@0+ (1,0) [0|7] "" HUT
 SG_ HAP_RtSide_Obj1_Confidence : 27|4@0+ (0.1,0) [0|1] "" HUT
 SG_ HAP_RtSide_Obj1_Ground_Pos_X : 23|12@0+ (0.01,0) [0|40] "m" HUT
 SG_ HAP_RtSide_Obj1_Ground_Pos_Y : 39|12@0+ (0.01,-20) [-20|20] "m" HUT
 SG_ HAP_RtSide_Obj2_ID : 79|4@0+ (1,0) [0|3] "" HUT
 SG_ HAP_RtSide_Obj2_type : 75|3@0+ (1,0) [0|7] "" HUT
 SG_ HAP_RtSide_Obj2_Confidence : 91|4@0+ (0.1,0) [0|1] "" HUT
 SG_ HAP_RtSide_Obj2_Ground_Pos_X : 87|12@0+ (0.01,0) [0|40] "m" HUT
 SG_ HAP_RtSide_Obj2_Ground_Pos_Y : 103|12@0+ (0.01,-20) [-20|20] "m" HUT
 SG_ HAP_RtSide_Obj3_ID : 143|4@0+ (1,0) [0|3] "" HUT
 SG_ HAP_RtSide_Obj3_type : 139|3@0+ (1,0) [0|7] "" HUT
 SG_ HAP_RtSide_Obj3_Confidence : 155|4@0+ (0.1,0) [0|1] "" HUT
 SG_ HAP_RtSide_Obj3_Ground_Pos_X : 151|12@0+ (0.01,0) [0|40] "m" HUT
 SG_ HAP_RtSide_Obj3_Ground_Pos_Y : 167|12@0+ (0.01,-20) [-20|20] "m" HUT
 SG_ HAP_RtSide_Obj4_ID : 207|4@0+ (1,0) [0|3] "" HUT
 SG_ HAP_RtSide_Obj4_type : 203|3@0+ (1,0) [0|7] "" HUT
 SG_ HAP_RtSide_Obj4_Confidence : 219|4@0+ (0.1,0) [0|1] "" HUT
 SG_ HAP_RtSide_Obj4_Ground_Pos_X : 215|12@0+ (0.01,0) [0|40] "m" HUT
 SG_ HAP_RtSide_Obj4_Ground_Pos_Y : 231|12@0+ (0.01,-20) [-20|20] "m" HUT
 SG_ USS_FLSide1_Status : 271|2@0+ (1,0) [0|3] "" HUT
 SG_ USS_FLSide1_Dist : 279|7@0+ (0.1,0) [0|12.6] "m" HUT
 SG_ USS_RLSide2_Status : 269|2@0+ (1,0) [0|3] "" HUT
 SG_ USS_RLSide2_Dist : 287|7@0+ (0.1,0) [0|12.6] "m" HUT
 SG_ USS_FRSide1_Status : 267|2@0+ (1,0) [0|3] "" HUT
 SG_ USS_FRSide1_Dist : 295|7@0+ (0.1,0) [0|12.6] "m" HUT
 SG_ USS_RRSide2_Status : 265|2@0+ (1,0) [0|3] "" HUT
 SG_ USS_RRSide2_Dist : 303|7@0+ (0.1,0) [0|12.6] "m" HUT

BO_ 667 HAP_FD7: 64 GW
 SG_ HAVP_LrngDst : 335|8@0+ (1,0) [0|200] "m" HUT
 SG_ HAVP_HUT_TextDisp : 343|6@0+ (1,0) [0|63] "" HUT

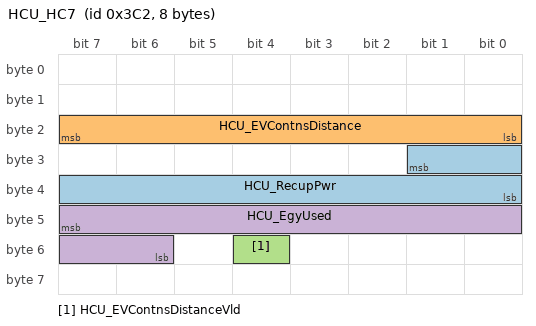
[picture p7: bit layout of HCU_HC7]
BO_ 962 HCU_HC7: 8 GW
 SG_ HCU_RecupPwr : 25|10@0+ (10,0) [0|10230] "Wh" HUT
 SG_ HCU_EVContnsDistance : 23|8@0+ (1,0) [0|254] "Km" HUT,T_BOX
 SG_ HCU_EVContnsDistanceVld : 52|1@0+ (1,0) [0|1] "" HUT
 SG_ HCU_EgyUsed : 47|10@0+ (0.01,0) [0|10.23] "KWh" HUT

CM_ SG_ 653 SecRowLeSeatVentSts "Left ventilation status of the second row";
CM_ SG_ 653 SecRowRiSeatVentSts "Right ventilation status of the second row";
CM_ SG_ 671 RemoteModSts "Remote mode status.IP Received";
CM_ SG_ 671 PASWorkCmd "PAS Work commandIP Received";
CM_ SG_ 671 KL30BRelaySts "KL30B Relay status.IP Received";
CM_ SG_ 671 RViewMirrorSts "Rear View Mirror FoldUnfold Status";
CM_ SG_ 671 WiprReq_F_PBox "Front windshield wiper operation request.";
CM_ SG_ 671 DrivingModReq "Driving mode request";
CM_ SG_ 845 ColMemPosnSetSwtFB "Column Memory Position Set Switch FeedBack";
CM_ SG_ 241 BMS_ErrCategory "BMS error Category";
CM_ SG_ 241 CheckSum_BMS4 "Use the checksum strategy from document Ã¢Â€ÂœEnd-to-End Communication Protection SpecificationÃ¢Â€ÂSC_CANFD:To HUT";
CM_ SG_ 241 BMS_PackCurr "Pack CurrentIP Received
positive value :discharging
negative value : charging";
CM_ SG_ 241 BMS_PackVolt "Pack VoltageIP Received";
CM_ SG_ 241 BMS_PowerDownCmplt "BMS power down complete .
BMS Inform HCU All Main relay have been open";
CM_ SG_ 241 BMS_BattPoweErr "Battray  Power Error";
CM_ SG_ 241 RollingCounter_BMS4 "Rolling counter BMS4SC_CANFD:To HUT";
CM_ SG_ 862 RoofModFb "Feedback of RoofMod";
CM_ SG_ 862 AllTerrainDislFb "Feedback of AllTerrainDisl";
CM_ SG_ 862 ElecSideStepSysFb "Feedback of ElecSideStepSys";
CM_ SG_ 350 CR_FCTA_Resp "Indicate FCTAÃ¯Â¼ÂˆFront Cross Traffic AlertÃ‚Â Ã¯Â¼Â‰ Switch statusL3Ã©ÂœÂ€Ã¨Â¦ÂÃ¥Â¢ÂžÃ¥ÂŠÂ ";
CM_ SG_ 350 CR_FCTB_Resp "Indicate FCTBÃ¯Â¼ÂˆFront Cross Traffic BrakeÃ‚Â Ã¯Â¼Â‰ Switch statusL3Ã©ÂœÂ€Ã¨Â¦ÂÃ¥Â¢ÂžÃ¥ÂŠÂ ";
CM_ SG_ 350 CR_BliSts "indicate Corner Radar blindness StatusL3Ã©ÂœÂ€Ã¨Â¦ÂÃ¥Â¢ÂžÃ¥ÂŠÂ ";
CM_ SG_ 350 FCTA_Warn "indicate FCTA Warning LevelL3Ã©ÂœÂ€Ã¨Â¦ÂÃ¥Â¢ÂžÃ¥ÂŠÂ ";
CM_ SG_ 350 FCTBTrig "indicate Corner Radar brake Status for ESPL3Ã©ÂœÂ€Ã¨Â¦ÂÃ¥Â¢ÂžÃ¥ÂŠÂ ";
CM_ SG_ 350 FCTA_B_FuncSts "Indicate FCTA_B fuction system working statusL3Ã©ÂœÂ€Ã¨Â¦ÂÃ¥Â¢ÂžÃ¥ÂŠÂ ";
CM_ SG_ 350 FCTA_B_TTC "FCTAFCTB TTC";
CM_ SG_ 357 LTurnLmpSwtSts "Left Turn Lamp Switch Status";
CM_ SG_ 357 RTurnLmpSwtSts "Right Turn Lamp Switch Status";
CM_ SG_ 357 AutoLmpSwtSts "Auto lamp switch status
When CSA detected auto light switch logical is ON, then signal is Auto,
When CSA detected light switch is different from auto lamp, then this signal is Non-Auto.Ã§ÂÂ¯Ã¥Â…Â‰Ã¥Â¼Â€Ã¥Â…Â³Ã¦Â˜Â¯Ã¥ÂÂ¦Ã¥Â¤Â„Ã¤ÂºÂŽautoÃ¦Â¡Â£Ã¥Â¼Â€Ã¥Â…Â³Ã¤Â¿Â¡Ã¥ÂÂ·IP Received";
CM_ SG_ 357 HornSwtSts "Horn switch States";
CM_ SG_ 357 FrntWiprSwtSts "Front Wiper Switch Status";
CM_ SG_ 161 SteerWheelAng "angle of steering wheel (raw data)";
CM_ SG_ 161 SteerWheelAngSign "sign of steering wheel angle (+-)
definition according to DIN 70000  ISO 8855
wheel position to left = positive
wheel position to right = negative
wheel position straightforward = 0 (positive)";
CM_ SG_ 161 SAS_Sts "Status of steering angle sensor";
CM_ SG_ 580 MenuReturnSwtSts "Menu Return Switch StatusIP Received";
CM_ SG_ 580 SteerWheelHeatdSts "Steer wheel heated statusCSA-LIN IFCom SWHM";
CM_ SG_ 580 HomeSwtSts "Home Switch StatusIP Received";
CM_ SG_ 580 MuteSwtSts "Mute Switch Status";
CM_ SG_ 580 CustomSwtSts "Custom Switch StatusIP Received";
CM_ SG_ 580 PageUpSwtSts "Page Up Switch StatusIP Received";
CM_ SG_ 580 PageDwnSwtSts "Page Down Switch StatusIP Received";
CM_ SG_ 580 PageLSwtSts "Page Left Switch StatusIP Received";
CM_ SG_ 580 PageRSwtSts "Page Right Switch StatusIP Received";
CM_ SG_ 580 SeekUpSwtSts "Seek Up Switch Status";
CM_ SG_ 580 SeekDwnSwtSts "Seek Down Switch Status";
CM_ SG_ 580 AdjVolUpSwtSts "Adjust Volume Up Switch  Status";
CM_ SG_ 580 AdjVolDwnSwtSts "Adjust Volume Down Switch Status";
CM_ SG_ 580 VRSwtSts "Voice Recognition Switch Status";
CM_ SG_ 580 EnterSwtSts "Enter Switch StatusIP Received";
CM_ SG_ 580 EnterSwtSts_Mmed "Enter Switch Status For Multimedia";
CM_ SG_ 580 CustomSwtSts_Mmed "Custom Switch Status For Multimedia";
CM_ SG_ 580 IpMenuSwtSts "Ip menu switch status";
CM_ SG_ 566 CheckSum_DCT7 "Use the checksum strategy from document Ã¢Â€ÂœEnd-to-End Communication Protection SpecificationÃ¢Â€ÂIP Received";
CM_ SG_ 566 TrsmStNID "The status of the Neutral in D control functionIP Received";
CM_ SG_ 566 DCT_RaceModeSts "Vehicle RaceMode stauteIP Received";
CM_ SG_ 566 TRANS_OIL_TEMP "Transmission oil temperatureIP Received";
CM_ SG_ 566 DCT_PrsBrk_Warn "Press brake to engage gearIP Received";
CM_ SG_ 566 DCT_ShftNotAlwd_Warn "Transmission shifting not allowedIP Received";
CM_ SG_ 566 DCT_ShftRecom_M "Transmission  shift recommendation in M modeIP Received";
CM_ SG_ 566 DrvWarnMsg "Driver display warning messagesIP Received";
CM_ SG_ 566 DrvFaiMsg "Driver display failure messagesIP Received";
CM_ SG_ 566 DrvModDisp "Driver display drive mode valueIP Received";
CM_ SG_ 566 DrvModDispSts "Driver display drive mode statusIP Received";
CM_ SG_ 566 DrvAutoGearDisp "Driver display gear valueIP Received";
CM_ SG_ 566 DrvGearDispSts "Driver display gear statusIP Received";
CM_ SG_ 566 RollingCounter_DCT7 "Rolling Counter_DCT7IP Received";
CM_ SG_ 166 TgtEngSpdIP "target engine speed for IPIP Received
Chuan Dong needs this signal for improving sensitivity of IP .";
CM_ SG_ 166 TgtEngSpdIPValid "Valid Flag for target engine speed for IPIP Received
Chuan Dong needs this signal for improving sensitivity of IP .";
CM_ SG_ 545 CurrentGearValid "Current gear valid";
CM_ SG_ 545 CURRENT_GEAR "To indicate which gear the DCT is in now";
CM_ SG_ 545 TGS_LEVER "Transmission gear selector lever position";
CM_ SG_ 545 TRANS_Warning_LAMP "Indication of MIL relevant failure on transmission side.";
CM_ SG_ 714 DrvWinPosnSts_Perc "driver window position status";
CM_ SG_ 714 DrvWinLrnSts "driver window learning status";
CM_ SG_ 714 DrvWinHotProtSts "driver window hot protection status";
CM_ SG_ 714 DrvSideRearWinLrnSts "driver side rear window learning status";
CM_ SG_ 714 DrvSideRearWinHotProtSts "driver side rear window hot protection status";
CM_ SG_ 759 DrvSideRearWinPosnSts_Perc "driver side rear window position status";
CM_ SG_ 589 DrowsnsLvl "Drowsiness level";
CM_ SG_ 589 DrowsnsLvlQlty "Drowsiness level Quality";
CM_ SG_ 589 GenderSts "Gender Status";
CM_ SG_ 589 GenderStsQlty "Gender Status Quality";
CM_ SG_ 589 ExprsnSts "Expression StatusADAS1_CAN:To ICU1.5";
CM_ SG_ 589 Checksum_DMS2 "Use the checksum strategy from document Ã¢Â€ÂœEnd-to-End Communication Protection SpecificationÃ¢Â€ÂADAS-CANFD To:IFC,IDC_L2,";
CM_ SG_ 589 DistrctnLvl_ACC "Distraction level to ACCADAS-CANFD To:IFC,IDC_L2,";
CM_ SG_ 589 DistrctnLvlQlty_ACC "Distraction level Quality to ACCADAS-CANFD To:IFC,IDC_L2,";
CM_ SG_ 589 DrowsnsLvl_ACC "Drowsiness level to ACCADAS-CANFD To:IFC,IDC_L2";
CM_ SG_ 589 DrowsnsLvlQlty_ACC "Drowsiness level Quality to ACCADAS-CANFD To:IFC,IDC_L2";
CM_ SG_ 589 RollingCounter_DMS2 "RollingCounter_DMS2ADAS-CANFD To:IFC,IDC_L2,";
CM_ SG_ 589 Checksum_DMS3 "Use the checksum strategy from document Ã¢Â€ÂœEnd-to-End Communication Protection SpecificationÃ¢Â€ÂADAS-CANFD To:IFC,IDC_L2,";
CM_ SG_ 589 HeadPosnX "Head position at X-axisADAS-CANFD To:IFC,IDC_L2";
CM_ SG_ 589 HeadPosnY "Head position at Y-axisADAS-CANFD To:IFC,IDC_L2";
CM_ SG_ 589 HeadPosnZ "Head position at Z-axisADAS-CANFD To:IFC,IDC_L2";
CM_ SG_ 589 HeadPosQlty "Head position qualityADAS-CANFD To:IFC,IDC_L2";
CM_ SG_ 589 RollingCounter_DMS3 "RollingCounter_DMS3ADAS-CANFD To:IFC,IDC_L2,";
CM_ SG_ 589 GazePosnX "Gaze position at X-axisADAS-CANFD To:IFC,IDC_L2";
CM_ SG_ 589 GazePosnY "Gaze position at Y-axisADAS-CANFD To:IFC,IDC_L2";
CM_ SG_ 589 GazePosnZ "Gaze position at Z-axisADAS-CANFD To:IFC,IDC_L2";
CM_ SG_ 589 Checksum_DMS5 "Use the checksum strategy from document Ã¢Â€ÂœEnd-to-End Communication Protection SpecificationÃ¢Â€ÂADAS-CANFD To:IFC,IDC_L2,";
CM_ SG_ 589 DMSSts "DMS StatusADAS-CANFD To:IFC,IDC_L2";
CM_ SG_ 589 HeadDetn "Head DetectionADAS-CANFD To:IFC,IDC_L2,";
CM_ SG_ 589 HeadYawAng "Head Yaw AngleADAS-CANFD To:IFC,IDC_L2,";
CM_ SG_ 589 HeadPitchAng "Head Pitch AngleADAS-CANFD To:IFC,IDC_L2,";
CM_ SG_ 589 HeadRollAng "Head Roll AngleADAS-CANFD To:IFC,IDC_L2,";
CM_ SG_ 589 HeadRotAngQlty "Head Rotation angle QualityADAS-CANFD To:IFC,IDC_L2";
CM_ SG_ 589 RollingCounter_DMS5 "RollingCounter_DMS5ADAS-CANFD To:IFC,IDC_L2,";
CM_ SG_ 589 Checksum_DMS6 "Use the checksum strategy from document Ã¢Â€ÂœEnd-to-End Communication Protection SpecificationÃ¢Â€ÂADAS-CANFD To:IFC,IDC_L2,";
CM_ SG_ 589 LEyeOpenSts "Left eye open statusADAS-CANFD To:IFC,IDC_L2,";
CM_ SG_ 589 LEyeOpenStsQlty "Left eye open status qualityADAS-CANFD To:IFC,IDC_L2,";
CM_ SG_ 589 REyeOpenSts "Right eye open statusADAS-CANFD To:IFC,IDC_L2,";
CM_ SG_ 589 REyeOpenStsQlty "Right eye open status qualityADAS-CANFD To:IFC,IDC_L2,";
CM_ SG_ 589 RobustGazeYawAng "Robust gaze yaw angleADAS-CANFD To:IFC,IDC_L2";
CM_ SG_ 589 RobustGazePitchAng "Robust gaze Pitch angleADAS-CANFD To:IFC,IDC_L2";
CM_ SG_ 589 RobustGazeAngQlty "Robust gaze angle qualityADAS-CANFD To:IFC,IDC_L2";
CM_ SG_ 589 DrvBehvSts "Driver Behavioral Area StatusADAS1_CAN:To ICU1.5";
CM_ SG_ 589 RollingCounter_DMS6 "RollingCounter_DMS6ADAS-CANFD To:IFC,IDC_L2,";
CM_ SG_ 705 ChairMemPosnSetSwtFB "FeedbackÃ‚Â ofÃ‚Â Ã‚Â ChairÃ‚Â MemoryÃ‚Â PositionÃ‚Â SetÃ‚Â switch";
CM_ SG_ 748 DVR_360VideoCaptureReq "360 video capture requestADAS-CANFD To:HAP";
CM_ SG_ 748 DVRRemtCnSts "DVR and TBOX remote connect status";
CM_ SG_ 748 DVRSN "DVR serial number";
CM_ SG_ 748 DVRSts "DVR status feedbackADAS_CAMFD:To IDC_L2";
CM_ SG_ 656 EngOilLvl "Engine oil level";
CM_ SG_ 656 FTIVFault "Fuel Tank Isolation Valve Fault.IP";
CM_ SG_ 656 FuelTankCapWarning "Fuel tank cap do not colse warning.IP";
CM_ SG_ 656 PressReliProgs "PressReliProgsIP";
CM_ SG_ 273 EMS_AuthenResult "This signal describes whether the authorisation result is passed or not.IP Received";
CM_ SG_ 273 EngSpd "Engine speedIP Received";
CM_ SG_ 273 EngSpdVldty "Engine speed validity";
CM_ SG_ 273 EngSpd_PHEV "Engine speedIP Received";
CM_ SG_ 273 EngSpdVldty_PHEV "Engine speed validity";
CM_ SG_ 723 EngSpd_ForIP "Engine speed for IP.IP Received";
CM_ SG_ 723 EWP_Err "Engine electronic water pump failure promptIP Received";
CM_ SG_ 949 ECM_VIN "The last 8 bytes of VIN stored in ECM.IP Received";
CM_ SG_ 625 FuelConsumption "Accumulated Fuel quantity injected since IGN ON.
Fuel quantity counter overflow is allowed.IP Received";
CM_ SG_ 625 TgtCrsVehSpd "Target cruise speedIP Received
When the signal \"SpdUnit\" sent by IP is 0x0:kph,the unit of signal \"TgtCruiseVehSpd\" is kph. When the signal \"SpdUnit\" sent by IP is 0x1:mph,the unit of signal \"TgtCruiseVehSpd\" is mph.
only for CC";
CM_ SG_ 625 CruiseCtrlSts "Cruise control statusIP Received
only for CC";
CM_ SG_ 625 AccelPedalPosn "Acceleration Pedal PositionSub_CAN:To HUD";
CM_ SG_ 625 AccelPedalPosnVldty "Acceleration pedal postion validityIP Received";
CM_ SG_ 625 ThrtlPosRatio "Throttle position ratioSub_CAN:To HUD";
CM_ SG_ 625 EngSVSSig "Engine SVSÃ¯Â¼Âˆservice vehicle soonÃ¯Â¼Â‰ SignalIP Received";
CM_ SG_ 625 MILSts "MILÃ¯Â¼Âˆmalfunction indicator lampÃ¯Â¼Â‰statusIP Received";
CM_ SG_ 625 EngState "Engine stateCoding 3 is stalling which means engine speed is not correct, therefore engine state can not be sure.";
CM_ SG_ 951 ECM_VehDstBackup "Vehicle total distance backup signal to IP.IP Received";
CM_ SG_ 881 BaroPressure "Barometer pressure";
CM_ SG_ 881 EngCoolantTemp "Engine coolant temperatureIP Received";
CM_ SG_ 881 GPF_Warning "This signal is used to display the warning information of GPF on IP.IP Received";
CM_ SG_ 881 GentrWarnLmpSts "Generator Warning Lamp StateIP Received
This signal will be used only in project  with LIN-Interface generator regulator. This signal will set 1-ON when engine not running or fault detected of generator system. This signal will set 0-OFF when generator system works normally.";
CM_ SG_ 881 EngClntTempWarn "Engine coolant temperature warning flagIP Received";
CM_ SG_ 881 EngClntTempVldty "Engine coolant temperature validityIP Received";
CM_ SG_ 881 SS_Screen_tip "Indicate the driver manual start the engine when the engine can not autostart.IP Received";
CM_ SG_ 881 SSSSetSts "Feedback Start_stop status to HUT";
CM_ SG_ 881 SS_Enable_Lamp "Enable StartStop FunctionÃ¯Â¼ÂˆGreen LampÃ¯Â¼Â‰IP Received";
CM_ SG_ 881 SS_Fault_Lamp "StartStop fault lampÃ¯Â¼ÂˆYellow LampÃ¯Â¼Â‰IP Received";
CM_ SG_ 881 MaxEngTrqNorm "Maximum Nornal
This value has to be set by Car Maker basing on Engine characteristics, Any other Torque value transmitted or received in the CAN BUS is expressed as a percentage of MaxEngTorqueNorm. It's a constant value during the communicaton life.";
CM_ SG_ 881 AGS_Failure "Used for instrument display when active intake grille failure.";
CM_ SG_ 680 TranPMode_Sts "Transport Mode statusIP Received
IFCom message EEM1";
CM_ SG_ 680 Stat_PwrSv_Lvl "Static Power save levelIP Received
IFCom message EEM1";
CM_ SG_ 680 Dyn_PwrSv_Lvl "dynamic Power save levelIP Received
IFCom message EEM1";
CM_ SG_ 680 LvPwrSysErr "LV power system errorIP Received
IFCom message EEM1";
CM_ SG_ 338 FrntELDLckSts "ELD Front ELock Status";
CM_ SG_ 338 RearELDLckSts "ELD Rear ELock Status";
CM_ SG_ 363 CheckSum_EPB1 "Use the checksum strategy from document Ã¢Â€ÂœEnd-to-End Communication Protection SpecificationÃ¢Â€Â";
CM_ SG_ 363 EPBErrSts "error indication of EPB system,and indicated yellow lamp on IP.IP Received";
CM_ SG_ 363 EPBRedLmpSts "indicate the EPB red lamp status to driver for dashboardIP Received";
CM_ SG_ 363 EPBSts "EPB status,indicate calipers status.";
CM_ SG_ 363 EPBTextDisp "EPB system status for text displayIP Received";
CM_ SG_ 363 PressBrakePedalPointOut "When driver want to release EPB with button, the system provides driver a reminder if pedal is not applied.IP Received";
CM_ SG_ 363 RollingCounter_EPB1 "Rolling Counter_EPB1";
CM_ SG_ 327 CheckSum_EPS1 "Use the checksum strategy from document Ã¢Â€ÂœEnd-to-End Communication Protection SpecificationÃ¢Â€Â";
CM_ SG_ 327 EPS_FailSts "Electrical steering fail statusIP Received";
CM_ SG_ 327 EPS_SteerMod "EPS steering mode";
CM_ SG_ 327 SteerCorrnRmn "Steering Wheel Correction Reminder";
CM_ SG_ 327 SteerCorrnResp "Steering Correction Reminder Switch Response";
CM_ SG_ 327 RollingCounter_EPS1 "Rolling counter_EPS1";
CM_ SG_ 771 RotSteerWheel "Rotate Steering WheelIP Received";
CM_ SG_ 311 CheckSum_ESP2 "Use the checksum strategy from document Ã¢Â€ÂœEnd-to-End Communication Protection SpecificationÃ¢Â€Â";
CM_ SG_ 311 HDCFault "HDC FaultIP Received
JustUAES ECM(4B134B154G15B) receive the signal for start-stop function";
CM_ SG_ 311 HDCCtrl "HDC control(OffOn, not active brakingOn, active braking)";
CM_ SG_ 311 AVHErrSts "error status of AVH(Automatic Vehicle Hold) functionIP Received
JustUAES ECM(4B134B154G15B) receive the signal for start-stop function";
CM_ SG_ 311 AVHSts "indicates the status of AVH(Automatic Vehicle Hold)IP Received";
CM_ SG_ 311 CDPActv "CDP(Controlled Deceleration for Parking Brake) is activeIP Received";
CM_ SG_ 311 DrivingModDis "ESP send the ack of the driver mode request signalIP Received
this signal is used for the function of All-Terrain Control . However this function is optional . When non-All-Terrain Control , this signal will be transmitted with the coding of \"0x0:Standard\".";
CM_ SG_ 311 DrivingModReq_ESP "ESP send the driver mode request signal2.this signal is used for the function of All-Terrain Control . However this function is optional . When non-All-Terrain Control , this signal will be transmitted with the coding of \"0x1:standard\".";
CM_ SG_ 311 Shift_N_Warn "If the Gear hasn't shifted to Neutral, when Vehicle will enter 4L mode,ESP will send the warning signalThis signal is only used for all-terrain function, If there is no all-terrain function,this signal will not be send .";
CM_ SG_ 311 Over_Spd_Warn "Over Speed Warn";
CM_ SG_ 311 FourL_Warn "4L_Warn";
CM_ SG_ 311 TAB_Sts "TAB control status";
CM_ SG_ 311 RollingCounter_ESP2 "Rolling Counter_ESP2";
CM_ SG_ 311 CheckSum_ESP1 "Use the checksum strategy from document Ã¢Â€ÂœEnd-to-End Communication Protection SpecificationÃ¢Â€Â";
CM_ SG_ 311 ESPFuncOffSts "ESP Function Off StateÃ¯Â¼ÂŒ
when it is 1, ESP off switch is pressed, and ESP function is offÃ¯Â¼ÂŒESP Off lamp on.
When it is 0,ESP off switch is released, and ESP function is ON, ESP Off lamp off.IP Received";
CM_ SG_ 311 ESPActvInfoLmp "Active information lamp - Indication that ESP system currently performs a brakeengine interventionIP Received";
CM_ SG_ 311 ESPFailSts "ESP fail statusIP Received";
CM_ SG_ 311 IMC_Actv "Intelligent Mode Control active";
CM_ SG_ 311 RollingCounter_ESP1 "Rolling Counter_ESP1";
CM_ SG_ 311 CheckSum_ABS3 "Use the checksum strategy from document Ã¢Â€ÂœEnd-to-End Communication Protection SpecificationÃ¢Â€Â";
CM_ SG_ 311 ABSActv "Indication that ESP system(especially ABS Module) currently performs a brake intervention. Set when ABS Active.";
CM_ SG_ 311 ABSFailSts "ABS system has detected a failure which does no allow a reliable ABS regulation and is therefore switched offIP Received";
CM_ SG_ 311 EBDFailSts "ESP system has detected a failure which does no allow a reliable ESP regulation and is therefore switched offIP Received
Ã¤Â»Â…DHTP2P2+P4Ã©ÂœÂ€T_BOXÃ¦ÂŽÂ¥Ã¦Â”Â¶";
CM_ SG_ 311 VehSpdVld "Qualityfault information to current Vehicle speed information.";
CM_ SG_ 311 VehSpd "Current Vehicle speed information
(when v <0.1 kph, set value to 0)";
CM_ SG_ 311 VehOdoInfoSts "Vehicle odograph information StatusIP Received";
CM_ SG_ 311 VehOdoInfo "Vehicle odograph informationIP Received";
CM_ SG_ 311 RollingCounter_ABS3 "Rolling Counter_ABS3";
CM_ SG_ 311 MAC_Check_ESP_FD2 "MAC protection mechanism should comply with the GWM MAC Specificatio";
CM_ SG_ 200 ESP_HMI_WarningOn "ESP requests the warning lamp in the dashboard";
CM_ SG_ 200 WadeModeWarn "Wade Mode Warn";
CM_ SG_ 368 CCO_Warn "Indicate that the driver should release EPB or slow down";
CM_ SG_ 368 CCO_Active "Indicates that CCO is active (CCO standby or active velocity control)";
CM_ SG_ 368 CCO_TgtVel "The target velocity of CCO function.";
CM_ SG_ 368 EspFuncOffSts_mode "When it is1 , ESP off switch is pressed, and ESP function(TCSVDCDTCRMI) is offÃ¯Â¼ÂŒESP off lamp lights onÃ¯Â¼ÂŒand display Cross-country expert mode in the IP
When it is 0,ESP off switch is released, and ESP function is ON, ESP Off lamp lights off.";
CM_ SG_ 411 FFogLmpSts_F_PBox "Front fog lamp statusIP Received";
CM_ SG_ 411 HiBeamSts_F_PBox "High beam statusIP Received
HUT_Sub:To HUD";
CM_ SG_ 411 HoodSts_F_PBox "hood statusIP Received";
CM_ SG_ 411 LasHdLmpSts_F_PBox "Laser Head Lamp StatusIP Received";
CM_ SG_ 411 LHiBeamFailSts "Left High beam failure statusIP Received";
CM_ SG_ 411 RHiBeamFailSts "Right High beam failure statusIP Received";
CM_ SG_ 411 LLowBeamFailSts "Left Low beam  failure statusIP Received";
CM_ SG_ 411 LHeadLmpFailSts "Left head lamp failure statusIP Received";
CM_ SG_ 411 RHeadLmpFailSts "Right head lamp failure statusIP Received";
CM_ SG_ 411 RLowBeamFailSts "Right Low beam  failure statusIP Received";
CM_ SG_ 411 RLasHdLmpDiagSig "Right Laser head lamp Diagnose signalIP Received";
CM_ SG_ 411 LLasHdLmpDiagSig "Left Laser head lamp Diagnose signalIP Received";
CM_ SG_ 411 LowBeamSts_F_PBox "Low beam status";
CM_ SG_ 411 WhistleSts_F_PBox "The state of the whistle signal.";
CM_ SG_ 699 U_BATT "Battery voltageÃ§Â¬Â¬Ã¤Â¸Â€Ã¦Â¬Â¡Ã¤Â¸ÂŠÃ§Â”ÂµÃ¥ÂˆÂÃ¥Â§Â‹Ã¥ÂŒÂ–Ã¦Â—Â¶Ã©Â—Â´:1.2s
Ã§ÂÂ¡Ã§ÂœÂ Ã¥Â”Â¤Ã©Â†Â’Ã¤Â¹Â‹Ã¥ÂÂŽÃ¥ÂˆÂÃ¥Â§Â‹Ã¥ÂŒÂ–Ã¦Â—Â¶Ã©Â—Â´:0.2s";
CM_ SG_ 699 I_RANGE "Battery current rangeÃ§Â¬Â¬Ã¤Â¸Â€Ã¦Â¬Â¡Ã¤Â¸ÂŠÃ§Â”ÂµÃ¥ÂˆÂÃ¥Â§Â‹Ã¥ÂŒÂ–Ã¦Â—Â¶Ã©Â—Â´:1.2s
Ã§ÂÂ¡Ã§ÂœÂ Ã¥Â”Â¤Ã©Â†Â’Ã¤Â¹Â‹Ã¥ÂÂŽÃ¥ÂˆÂÃ¥Â§Â‹Ã¥ÂŒÂ–Ã¦Â—Â¶Ã©Â—Â´:0.2s";
CM_ SG_ 699 I_BATT "Battery current,Bosch algorithm:\"E=(N*+Offset) x Factor\"Ã§Â¬Â¬Ã¤Â¸Â€Ã¦Â¬Â¡Ã¤Â¸ÂŠÃ§Â”ÂµÃ¥ÂˆÂÃ¥Â§Â‹Ã¥ÂŒÂ–Ã¦Â—Â¶Ã©Â—Â´:1.2s
Ã§ÂÂ¡Ã§ÂœÂ Ã¥Â”Â¤Ã©Â†Â’Ã¤Â¹Â‹Ã¥ÂÂŽÃ¥ÂˆÂÃ¥Â§Â‹Ã¥ÂŒÂ–Ã¦Â—Â¶Ã©Â—Â´:0.2s
**Ã¤Â¸Âº:(raw value +offset)*factor";
CM_ SG_ 699 SOC "State of ChargeÃ§Â¬Â¬Ã¤Â¸Â€Ã¦Â¬Â¡Ã¤Â¸ÂŠÃ§Â”ÂµÃ¥ÂˆÂÃ¥Â§Â‹Ã¥ÂŒÂ–Ã¦Â—Â¶Ã©Â—Â´:6s
Ã§ÂÂ¡Ã§ÂœÂ Ã¥Â”Â¤Ã©Â†Â’Ã¤Â¹Â‹Ã¥ÂÂŽÃ¥ÂˆÂÃ¥Â§Â‹Ã¥ÂŒÂ–Ã¦Â—Â¶Ã©Â—Â´:5s";
CM_ SG_ 699 SOH_SUL "max.possible SOC,reduced by sulphationÃ§Â¬Â¬Ã¤Â¸Â€Ã¦Â¬Â¡Ã¤Â¸ÂŠÃ§Â”ÂµÃ¥ÂˆÂÃ¥Â§Â‹Ã¥ÂŒÂ–Ã¦Â—Â¶Ã©Â—Â´:6s
Ã§ÂÂ¡Ã§ÂœÂ Ã¥Â”Â¤Ã©Â†Â’Ã¤Â¹Â‹Ã¥ÂÂŽÃ¥ÂˆÂÃ¥Â§Â‹Ã¥ÂŒÂ–Ã¦Â—Â¶Ã©Â—Â´:5s";
CM_ SG_ 699 SOC_STATE "SOC StatusÃ§Â¬Â¬Ã¤Â¸Â€Ã¦Â¬Â¡Ã¤Â¸ÂŠÃ§Â”ÂµÃ¥ÂˆÂÃ¥Â§Â‹Ã¥ÂŒÂ–Ã¦Â—Â¶Ã©Â—Â´:6s
Ã§ÂÂ¡Ã§ÂœÂ Ã¥Â”Â¤Ã©Â†Â’Ã¤Â¹Â‹Ã¥ÂÂŽÃ¥ÂˆÂÃ¥Â§Â‹Ã¥ÂŒÂ–Ã¦Â—Â¶Ã©Â—Â´:5s";
CM_ SG_ 699 SOH_SUL_STATE "SOH_SUL_StatusÃ§Â¬Â¬Ã¤Â¸Â€Ã¦Â¬Â¡Ã¤Â¸ÂŠÃ§Â”ÂµÃ¥ÂˆÂÃ¥Â§Â‹Ã¥ÂŒÂ–Ã¦Â—Â¶Ã©Â—Â´:6s
Ã§ÂÂ¡Ã§ÂœÂ Ã¥Â”Â¤Ã©Â†Â’Ã¤Â¹Â‹Ã¥ÂÂŽÃ¥ÂˆÂÃ¥Â§Â‹Ã¥ÂŒÂ–Ã¦Â—Â¶Ã©Â—Â´:5s";
CM_ SG_ 699 OTA_UpgrdModSts "OTA upgrade mode status";
CM_ SG_ 699 CheckSum_GWM1 "Use the checksum strategy from document Ã¢Â€ÂœEnd-to-End Communication Protection SpecificationÃ¢Â€Â";
CM_ SG_ 699 RollingCounter_GWM1 "RollingCounter";
CM_ SG_ 347 APS_PrkgMod "APS Parking Mode";
CM_ SG_ 347 APS_ProcBar "APS Process bar";
CM_ SG_ 347 APS_SwtSts "APS Switch status";
CM_ SG_ 347 APS_SlotDisp "APS Slot Display";
CM_ SG_ 347 APS_SysSoundIndcn "APS_System Sound IndicationIP Received";
CM_ SG_ 347 APS_PrkgTyp "APS Parking Type";
CM_ SG_ 347 APS_TextDisp "APS Text Display";
CM_ SG_ 347 APS_WorkSts "APS Work statusIP Received";
CM_ SG_ 347 MEB_AVHReq "inform ESP the MEB request Auto Hold";
CM_ SG_ 347 APS_ESP_BrkDistance "inform the ESP the parking target distance";
CM_ SG_ 347 LParaPrkgOutVald "Left parallel Parking Out Valid";
CM_ SG_ 347 RParaPrkgOutVald "Right parallel Parking Out Valid";
CM_ SG_ 347 HeadVertPrkgOutVald "Head Vertical Parking Out Valid";
CM_ SG_ 347 TailVertPrkgOutVald "Tail Vertical Parking Out Valid";
CM_ SG_ 347 HAP_SwtDispCtrlCmd "control switch area display mode";
CM_ SG_ 347 HAP_PrkgModCurrSts "show park mode of current parking";
CM_ SG_ 347 APS_MovgDirc "Moving direction of parking";
CM_ SG_ 347 ParallelSlotBtn_Ena "Parallel Slot button enableÃ¨Â‡ÂªÃ©Â€Â‰Ã¨Â½Â¦Ã¤Â½ÂÃ§Â•ÂŒÃ©ÂÂ¢Ã¦Â°Â´Ã¥Â¹Â³Ã¨Â½Â¦Ã¤Â½ÂÃ¦ÂŒÂ‰Ã©Â”Â®Ã§ÂŠÂ¶Ã¦Â€Â";
CM_ SG_ 347 VerticalSlotBtn_Ena "Vertical Slot button enableÃ¨Â‡ÂªÃ©Â€Â‰Ã¨Â½Â¦Ã¤Â½ÂÃ§Â•ÂŒÃ©ÂÂ¢Ã¥ÂžÂ‚Ã§Â›Â´Ã¨Â½Â¦Ã¤Â½ÂÃ¦ÂŒÂ‰Ã©Â”Â®Ã§ÂŠÂ¶Ã¦Â€Â";
CM_ SG_ 347 ClockwiseBtn_Ena "Clockwise button enableÃ¨Â‡ÂªÃ©Â€Â‰Ã¨Â½Â¦Ã¤Â½ÂÃ§Â•ÂŒÃ©ÂÂ¢Ã©Â¡ÂºÃ¦Â—Â¶Ã©Â’ÂˆÃ¦ÂŒÂ‰Ã©Â”Â®Ã§ÂŠÂ¶Ã¦Â€Â";
CM_ SG_ 347 AnticlockwiseBtn_Ena "Anticlockwise button enableÃ¨Â‡ÂªÃ©Â€Â‰Ã¨Â½Â¦Ã¤Â½ÂÃ§Â•ÂŒÃ©ÂÂ¢Ã©Â€Â†Ã¦Â—Â¶Ã©Â’ÂˆÃ¦ÂŒÂ‰Ã©Â”Â®Ã§ÂŠÂ¶Ã¦Â€Â";
CM_ SG_ 347 SlotConfirmBtn_Ena "Anticlockwise button enableÃ¨Â‡ÂªÃ©Â€Â‰Ã¨Â½Â¦Ã¤Â½ÂÃ§Â•ÂŒÃ©ÂÂ¢Ã§Â¡Â®Ã¨Â®Â¤Ã¨Â½Â¦Ã¤Â½ÂÃ¦ÂŒÂ‰Ã©Â”Â®Ã§ÂŠÂ¶Ã¦Â€Â";
CM_ SG_ 347 HAVP_StopBtn_Ena "Ending button enableÃ¨Â®Â¾Ã§Â½Â®Ã¥Â½Â“Ã¥Â‰ÂÃ¤Â½ÂÃ§Â½Â®Ã¤Â¸ÂºÃ§Â»ÂˆÃ§Â‚Â¹Ã¦ÂŒÂ‰Ã©Â”Â®Ã§ÂŠÂ¶Ã¦Â€Â";
CM_ SG_ 347 HAVP_StartBtn_Ena "Starting button enable
Ã¨Â®Â¾Ã§Â½Â®Ã¥Â½Â“Ã¥Â‰ÂÃ¤Â½ÂÃ§Â½Â®Ã¤Â¸ÂºÃ¨ÂµÂ·Ã§Â‚Â¹Ã¦ÂŒÂ‰Ã©Â”Â®Ã§ÂŠÂ¶Ã¦Â€Â";
CM_ SG_ 347 HAVP_SelfParLotEnding_Ena "Self-selection parking lot for ending poing enable status
Ã¨Â®Â¾Ã§Â½Â®Ã¨Â‡ÂªÃ©Â€Â‰Ã¨Â½Â¦Ã¤Â½ÂÃ¤Â¸ÂºÃ§Â»ÂˆÃ§Â‚Â¹Ã¦ÂŒÂ‰Ã©Â”Â®Ã§ÂŠÂ¶Ã¦Â€Â";
CM_ SG_ 347 PAVP_TextDis "PAVP text display PAVPÃ¤ÂºÂ¤Ã¤ÂºÂ’Ã¦Â˜Â¾Ã§Â¤ÂºÃ¤Â¿Â¡Ã¦ÂÂ¯Ã¦ÂÂÃ©Â†Â’";
CM_ SG_ 628 AutoAVMSwtSet_Sts "Auto Around view swtich set status,to HUT.";
CM_ SG_ 628 AVM_CurrSts "Used to indicate the current state of AVM.";
CM_ SG_ 628 GuidOvlSts "Show the current status of guidance overlay";
CM_ SG_ 628 FrntCamInpFailSts "Controller is failed to receive front camera video input.";
CM_ SG_ 628 RearCamInpFailSts "Controller is failed to receive rear camera video input.";
CM_ SG_ 628 LeCamInpFailSts "Controller is failed to receive left camera video input.";
CM_ SG_ 628 RiCamInpFailSts "Controller is failed to receive right camera video input.";
CM_ SG_ 628 EolNotCmpltd "Used to check whether EOL is completed.";
CM_ SG_ 628 OvlOpFailSts "Overlay could not operate normally. The corresponding buttons shall be shown as grey.";
CM_ SG_ 628 LaneCalSts "Used to indicate the current state of
Calibration.";
CM_ SG_ 628 RadarDispSts "Show the current Display status of Radar";
CM_ SG_ 628 LaneCalFltSts "Used to indicate the Fault-code of Lane
Calibration";
CM_ SG_ 628 AutoViewChgFuncSts "Used to indicate the function state of AutoChangeView";
CM_ SG_ 628 CarMdlTrsprcySts "Car Model Transparency Status";
CM_ SG_ 628 CarMdlDispSts "Indicate the 2D3D display mode status";
CM_ SG_ 628 CurrCalResultSts "Used to indicate  the current Calbrtion Result AVM Using";
CM_ SG_ 628 MdlColrSts "Used to indicate the model color";
CM_ SG_ 628 SigViewIndcn "Single View Indication, used to indicate the current single view.";
CM_ SG_ 628 HAP_DispCmd "HAP display command";
CM_ SG_ 628 AVM_3DAngSts "Horizontal angle state of 3D view";
CM_ SG_ 628 MOD_WorkSts "MOD function work status";
CM_ SG_ 628 MOD_AlarmSts "MOD function alarm status";
CM_ SG_ 628 DVRWorkSts "DVR work status";
CM_ SG_ 628 HAP_Hmi_Index "Indicate the current HMI index of AVM.";
CM_ SG_ 664 RPAS_NearBrrdstn "RPAS nearest barrier distance";
CM_ SG_ 664 HAVP_ProcRa "Vehicle B area display route Generation Progress Bar";
CM_ SG_ 664 APS_ObjRiSideAr1 "Right side sensor detect area1";
CM_ SG_ 664 APS_ObjRiSideAr2 "Right side sensor detect area2";
CM_ SG_ 664 APS_ObjRiSideAr3 "Right side sensor detect area3";
CM_ SG_ 664 APS_ObjRiSideAr4 "Right side sensor detect area4";
CM_ SG_ 664 APS_ObjRiSideAr5 "Right side sensor detect area5";
CM_ SG_ 664 APS_ObjLeSideAr1 "Left side sensor detect area1";
CM_ SG_ 664 APS_ObjLeSideAr2 "Left side sensor detect area2";
CM_ SG_ 664 APS_ObjLeSideAr3 "Left side sensor detect area3";
CM_ SG_ 664 APS_ObjLeSideAr4 "Left side sensor detect area4";
CM_ SG_ 664 APS_ObjLeSideAr5 "Left side sensor detect area5";
CM_ SG_ 664 APS_FRSideSnsrFailSts "Fail status of the Front Right Side sensorIP Received";
CM_ SG_ 664 APS_FLSideSnsrFailSts "Fail status of the Front Left Sid sensorIP Received";
CM_ SG_ 664 APS_RRSideSnsrFailSts "Fail status of the Rear Right Side sensorIP Received";
CM_ SG_ 664 APS_RLSideSnsrFailSts "Fault status of the Rear Left Side sensorIP Received";
CM_ SG_ 664 SDW_SoundIndcn "Side Distance Warning Sound IndicationIP Received";
CM_ SG_ 664 SDWActiveSts "Side Distance Warning Function Active StatusIP Received";
CM_ SG_ 664 RPAS_ObjRRCornrAr1 "Rear right Corner sensor detect area1";
CM_ SG_ 664 RPAS_ObjRRCornrAr2 "Rear right Corner sensor detect area2";
CM_ SG_ 664 RPAS_ObjRRMidlAr1 "Rear right middle sensor detect area1";
CM_ SG_ 664 RPAS_ObjRRMidlAr2 "Rear right middle sensor detect area2";
CM_ SG_ 664 RPAS_ObjRLMidlAr1 "Rear left middle sensor detect area1";
CM_ SG_ 664 RPAS_ObjRLMidlAr2 "Rear left middle sensor detect area2";
CM_ SG_ 664 RPAS_ObjRLCornrAr1 "Rear left Corner sensor detect area1";
CM_ SG_ 664 RPAS_ObjRLCornrAr2 "Rear left Corner sensor detect area2";
CM_ SG_ 664 RPAS_RLCornrSnsrFailSts "fail status of the Rear Left Corner sensor";
CM_ SG_ 664 RPAS_RLMiddlSnsrFailSts "fail status of the Rear Left Middle  sensor";
CM_ SG_ 664 RPAS_RRMiddlSnsrFailSts "fail status of the Rear Right Middle sensor";
CM_ SG_ 664 RPAS_RRCornrSnsrFailSts "fail status of the Rear Right Corner sensor";
CM_ SG_ 664 RPAS_WorkSts "Rear Park Assistant System work StatusIP Received";
CM_ SG_ 664 RPAS_SoundIndcn "Rear Park Assistant System Sound IndicationIP Received";
CM_ SG_ 664 MEBWorkSts "RPAS MEB Work Status";
CM_ SG_ 664 MEB_EnableSts "MEB Enable Status";
CM_ SG_ 664 FPAS_ObjFLCornrAr1 "Front left Corner sensor detect area1";
CM_ SG_ 664 FPAS_ObjFLCornrAr2 "Front left Corner sensor detect area2";
CM_ SG_ 664 FPAS_ObjFLMidlAr1 "Front left middle sensor detect area1";
CM_ SG_ 664 FPAS_ObjFLMidlAr2 "Front left middle sensor detect area2";
CM_ SG_ 664 FPAS_ObjFRMidlAr1 "Front right middle sensor detect area1";
CM_ SG_ 664 FPAS_ObjFRMidlAr2 "Front right middle area2";
CM_ SG_ 664 FPAS_ObjFRCornrAr1 "Front right Corner sensor detect area1";
CM_ SG_ 664 FPAS_ObjFRCornrAr2 "Front right Corner sensor detect area2";
CM_ SG_ 664 FPAS_FLCornrSnsrFailSts "Fail status of the Front Left Corner sensor";
CM_ SG_ 664 FPAS_FLMiddlSnsrFailSts "Fail status of the Front Left Middle  sensor";
CM_ SG_ 664 FPAS_FRMiddlSnsrFailSts "Fail status of the Front Right Middle sensor";
CM_ SG_ 664 FPAS_FRCornrSnsrFailSts "Fail status of the Front Right Corner sensor";
CM_ SG_ 664 FPAS_WorkSts "Park Assistant Front System StatusIP Received";
CM_ SG_ 664 FPAS_AutoModSts "Park Assistant Front System AutoStategy Status";
CM_ SG_ 664 FPAS_SoundIndcn "Front Park Assistant System Sound IndicationIP Received";
CM_ SG_ 664 FPAS_NearBrrdstn "FPAS nearest barrier distance";
CM_ SG_ 664 APA_MenuDispCtrlCmd "APA menu display mode control command (area A)";
CM_ SG_ 664 APA_FuncSts "APA Function status";
CM_ SG_ 664 RADS_FuncSts "Reverse Asist Function status";
CM_ SG_ 664 FADS_FuncSts "Front Asist Function status";
CM_ SG_ 664 HAP_TextIconDispCtrl "Control display method of small icon beside text box";
CM_ SG_ 649 HAP_RtCam_WorkSts "Current work status of  HAP right camera";
CM_ SG_ 649 HAP_RtSide_Obj1_ID "ID of the Target obstacle on the right side of vehicle";
CM_ SG_ 649 HAP_RtSide_Obj1_type "OD_type";
CM_ SG_ 649 HAP_RtSide_Obj1_Confidence "Confidence of the Target obstacle";
CM_ SG_ 649 HAP_RtSide_Obj1_Ground_Pos_X "X-Axis Position of the Target obstacle";
CM_ SG_ 649 HAP_RtSide_Obj1_Ground_Pos_Y "Y-Axis Position of the Target obstacle";
CM_ SG_ 649 HAP_RtSide_Obj2_ID "ID of theTarget obstacle on the right side of vehicle";
CM_ SG_ 649 HAP_RtSide_Obj2_type "OD_type";
CM_ SG_ 649 HAP_RtSide_Obj2_Confidence "Confidence of the Target obstacle";
CM_ SG_ 649 HAP_RtSide_Obj2_Ground_Pos_X "X-Axis Position of the Target obstacle";
CM_ SG_ 649 HAP_RtSide_Obj2_Ground_Pos_Y "Y-Axis Position of the Target obstacle";
CM_ SG_ 649 HAP_RtSide_Obj3_ID "ID of theTarget obstacle on the right side of vehicle";
CM_ SG_ 649 HAP_RtSide_Obj3_type "OD_type";
CM_ SG_ 649 HAP_RtSide_Obj3_Confidence "Confidence of the Target obstacle";
CM_ SG_ 649 HAP_RtSide_Obj3_Ground_Pos_X "X-Axis Position of the Target obstacle";
CM_ SG_ 649 HAP_RtSide_Obj3_Ground_Pos_Y "Y-Axis Position of the Target obstacle";
CM_ SG_ 649 HAP_RtSide_Obj4_ID "ID of theTarget obstacle on the right side of vehicle";
CM_ SG_ 649 HAP_RtSide_Obj4_type "OD_type";
CM_ SG_ 649 HAP_RtSide_Obj4_Confidence "Confidence of the Target obstacle";
CM_ SG_ 649 HAP_RtSide_Obj4_Ground_Pos_X "X-Axis Position of the Target obstacle";
CM_ SG_ 649 HAP_RtSide_Obj4_Ground_Pos_Y "Y-Axis Position of the Target obstacle";
CM_ SG_ 649 USS_FLSide1_Status "USS(on the front left side) Working Status";
CM_ SG_ 649 USS_FLSide1_Dist "Distance of detecting the target on the front left side";
CM_ SG_ 649 USS_RLSide2_Status "USS(on the rear left side) Working Status";
CM_ SG_ 649 USS_RLSide2_Dist "Distance of detecting the target on the rear left side";
CM_ SG_ 649 USS_FRSide1_Status "USS(on the front right side) Working Status";
CM_ SG_ 649 USS_FRSide1_Dist "Distance of detecting the target on the front right side";
CM_ SG_ 649 USS_RRSide2_Status "USS(on the rear right side) Working Status";
CM_ SG_ 649 USS_RRSide2_Dist "Distance of detecting the target on the rear right side";
CM_ SG_ 667 HAVP_LrngDst "Learning distance calculated by HAVP controllerÃ¦Â­Â£Ã¥ÂœÂ¨Ã¥Â­Â¦Ã¤Â¹Â Ã§ÂšÂ„Ã¨Â·Â¯Ã§ÂºÂ¿Ã¨Â·ÂÃ§Â¦Â»";
CM_ SG_ 667 HAVP_HUT_TextDisp "HAVP text display on HUTÃ¨Â®Â°Ã¥Â¿Â†Ã¦Â³ÂŠÃ¨Â½Â¦Ã¨Â½Â¦Ã¦ÂœÂºÃ§Â«Â¯Ã¦Â–Â‡Ã¥Â­Â—Ã¦ÂÂÃ§Â¤Âº";
CM_ SG_ 962 HCU_RecupPwr "Accumulated electric energy the vehicle recuperated since ig on,
Energy quantity counter overflow is allowed.";
CM_ SG_ 962 HCU_EVContnsDistance "Electric continuous distance.IP Received";
CM_ SG_ 962 HCU_EVContnsDistanceVld "Electric continuous distance valid.IP Received";
CM_ SG_ 962 HCU_EgyUsed "Accumulated electric energy the vehicle usd since ig on,Energyquantity counter overflow is allowed.";

BA_DEF_ BO_ "DiagRequest" ENUM  "No","Yes";
BA_DEF_ BO_ "DiagResponse" ENUM  "No","Yes";
BA_DEF_ BO_ "DiagState" ENUM  "No","Yes";
BA_DEF_ BO_ "GenMsgCycleTime" INT 0 65535;
BA_DEF_ BO_ "GenMsgCycleTimeFast" INT 0 65535;
BA_DEF_ BO_ "GenMsgILSupport" ENUM  "No","Yes";
BA_DEF_ BO_ "GenMsgNrOfRepetition" INT 0 65535;
BA_DEF_ BO_ "GenMsgSendType" ENUM  "Cyclic","CyclicAndSpontanX","Event";
BA_DEF_ BO_ "NmAsrMessage" ENUM  "No","Yes";
BA_DEF_ BO_ "OriginFrame" STRING;
BA_DEF_ BO_ "SCP_AuthInfoTxLength" INT 0 512;
BA_DEF_ BO_ "SCP_DataId" INT 0 65535;
BA_DEF_ BO_ "SCP_FreshnessValueLength" INT 0 512;
BA_DEF_ BO_ "SCP_FreshnessValueTxLength" INT 0 512;
BA_DEF_ BO_ "SC_Message" ENUM  "NO","YES";
BA_DEF_ BO_ "VFrameFormat" ENUM  "StandardCAN","ExtendedCAN","reserved","reserved","reserved","reserved","reserved","reserved","reserved","reserved","reserved","reserved","reserved","reserved","StandardCAN_FD","ExtendedCAN_FD";
BA_DEF_ SG_ "GenSigCycleTime" INT 0 65535;
BA_DEF_ SG_ "GenSigSendType" ENUM  "Cyclic","OnWrite","OnWriteWithRepetition","OnChange","OnChangeWithRepetition","NotUsed","NotUsed","NoSigSendType";
BA_DEF_ SG_ "GenSigStartValue" FLOAT 0 100000000000;
BA_DEF_ SG_ "Match" STRING;
BA_DEF_ SG_ "Origin" STRING;
BA_DEF_ SG_ "SystemSignalLongSymbol" STRING;
BA_DEF_DEF_ "DiagRequest" "No";
BA_DEF_DEF_ "DiagResponse" "No";
BA_DEF_DEF_ "DiagState" "No";
BA_DEF_DEF_ "GenMsgCycleTime" 0;
BA_DEF_DEF_ "GenMsgCycleTimeFast" 0;
BA_DEF_DEF_ "GenMsgILSupport" "No";
BA_DEF_DEF_ "GenMsgNrOfRepetition" 0;
BA_DEF_DEF_ "GenMsgSendType" "Cyclic";
BA_DEF_DEF_ "GenSigCycleTime" 0;
BA_DEF_DEF_ "GenSigSendType" "Cyclic";
BA_DEF_DEF_ "GenSigStartValue" 0;
BA_DEF_DEF_ "Match" "";
BA_DEF_DEF_ "NmAsrMessage" "No";
BA_DEF_DEF_ "Origin" "";
BA_DEF_DEF_ "OriginFrame" "";
BA_DEF_DEF_ "SCP_AuthInfoTxLength" 0;
BA_DEF_DEF_ "SCP_DataId" 0;
BA_DEF_DEF_ "SCP_FreshnessValueLength" 0;
BA_DEF_DEF_ "SCP_FreshnessValueTxLength" 0;
BA_DEF_DEF_ "SC_Message" "NO";
BA_DEF_DEF_ "SystemSignalLongSymbol" "";
BA_DEF_DEF_ "VFrameFormat" "";
BA_ "GenMsgCycleTime" BO_ 653 100;
BA_ "GenMsgILSupport" BO_ 653 1;
BA_ "OriginFrame" BO_ 653 "fuel,ev";
BA_ "VFrameFormat" BO_ 653 14;
BA_ "GenMsgCycleTime" BO_ 671 100;
BA_ "GenMsgILSupport" BO_ 671 1;
BA_ "OriginFrame" BO_ 671 "fuel,ev";
BA_ "VFrameFormat" BO_ 671 14;
BA_ "GenMsgCycleTime" BO_ 845 500;
BA_ "GenMsgILSupport" BO_ 845 1;
BA_ "OriginFrame" BO_ 845 "fuel,ev";
BA_ "VFrameFormat" BO_ 845 14;
BA_ "GenMsgCycleTime" BO_ 241 10;
BA_ "GenMsgILSupport" BO_ 241 1;
BA_ "OriginFrame" BO_ 241 "fuel,ev";
BA_ "VFrameFormat" BO_ 241 14;
BA_ "GenMsgCycleTime" BO_ 862 500;
BA_ "GenMsgILSupport" BO_ 862 1;
BA_ "OriginFrame" BO_ 862 "fuel,ev";
BA_ "VFrameFormat" BO_ 862 14;
BA_ "GenMsgCycleTime" BO_ 350 20;
BA_ "GenMsgILSupport" BO_ 350 1;
BA_ "OriginFrame" BO_ 350 "fuel,ev";
BA_ "VFrameFormat" BO_ 350 14;
BA_ "GenMsgCycleTime" BO_ 357 20;
BA_ "GenMsgILSupport" BO_ 357 1;
BA_ "OriginFrame" BO_ 357 "fuel,ev";
BA_ "VFrameFormat" BO_ 357 14;
BA_ "GenMsgCycleTime" BO_ 161 10;
BA_ "GenMsgILSupport" BO_ 161 1;
BA_ "OriginFrame" BO_ 161 "fuel,ev";
BA_ "VFrameFormat" BO_ 161 14;
BA_ "GenMsgCycleTime" BO_ 580 50;
BA_ "GenMsgILSupport" BO_ 580 1;
BA_ "OriginFrame" BO_ 580 "fuel,ev";
BA_ "VFrameFormat" BO_ 580 14;
BA_ "GenMsgCycleTime" BO_ 566 50;
BA_ "GenMsgILSupport" BO_ 566 1;
BA_ "OriginFrame" BO_ 566 "fuel,ev";
BA_ "VFrameFormat" BO_ 566 14;
BA_ "GenMsgCycleTime" BO_ 166 10;
BA_ "GenMsgILSupport" BO_ 166 1;
BA_ "OriginFrame" BO_ 166 "fuel,ev";
BA_ "VFrameFormat" BO_ 166 14;
BA_ "GenMsgCycleTime" BO_ 545 20;
BA_ "GenMsgILSupport" BO_ 545 1;
BA_ "OriginFrame" BO_ 545 "fuel,ev";
BA_ "VFrameFormat" BO_ 545 14;
BA_ "GenMsgCycleTime" BO_ 714 100;
BA_ "GenMsgILSupport" BO_ 714 1;
BA_ "OriginFrame" BO_ 714 "fuel,ev";
BA_ "VFrameFormat" BO_ 714 14;
BA_ "GenMsgCycleTime" BO_ 759 100;
BA_ "GenMsgILSupport" BO_ 759 1;
BA_ "OriginFrame" BO_ 759 "fuel,ev";
BA_ "VFrameFormat" BO_ 759 14;
BA_ "GenMsgCycleTime" BO_ 589 50;
BA_ "GenMsgILSupport" BO_ 589 1;
BA_ "OriginFrame" BO_ 589 "fuel,ev";
BA_ "VFrameFormat" BO_ 589 14;
BA_ "GenMsgCycleTime" BO_ 705 100;
BA_ "GenMsgILSupport" BO_ 705 1;
BA_ "OriginFrame" BO_ 705 "fuel,ev";
BA_ "VFrameFormat" BO_ 705 14;
BA_ "GenMsgCycleTime" BO_ 748 100;
BA_ "GenMsgILSupport" BO_ 748 1;
BA_ "OriginFrame" BO_ 748 "fuel,ev";
BA_ "VFrameFormat" BO_ 748 14;
BA_ "GenMsgCycleTime" BO_ 656 100;
BA_ "GenMsgILSupport" BO_ 656 1;
BA_ "OriginFrame" BO_ 656 "fuel,ev";
BA_ "VFrameFormat" BO_ 656 14;
BA_ "GenMsgCycleTime" BO_ 273 10;
BA_ "GenMsgILSupport" BO_ 273 1;
BA_ "OriginFrame" BO_ 273 "fuel,ev";
BA_ "VFrameFormat" BO_ 273 14;
BA_ "GenMsgCycleTime" BO_ 723 100;
BA_ "GenMsgILSupport" BO_ 723 1;
BA_ "OriginFrame" BO_ 723 "fuel,ev";
BA_ "VFrameFormat" BO_ 723 14;
BA_ "GenMsgCycleTime" BO_ 949 1000;
BA_ "GenMsgILSupport" BO_ 949 1;
BA_ "OriginFrame" BO_ 949 "fuel,ev";
BA_ "VFrameFormat" BO_ 949 14;
BA_ "GenMsgCycleTime" BO_ 625 20;
BA_ "GenMsgILSupport" BO_ 625 1;
BA_ "OriginFrame" BO_ 625 "fuel,ev";
BA_ "VFrameFormat" BO_ 625 14;
BA_ "GenMsgCycleTime" BO_ 951 1000;
BA_ "GenMsgILSupport" BO_ 951 1;
BA_ "OriginFrame" BO_ 951 "fuel,ev";
BA_ "VFrameFormat" BO_ 951 14;
BA_ "GenMsgCycleTime" BO_ 881 100;
BA_ "GenMsgILSupport" BO_ 881 1;
BA_ "OriginFrame" BO_ 881 "fuel,ev";
BA_ "VFrameFormat" BO_ 881 14;
BA_ "GenMsgCycleTime" BO_ 680 100;
BA_ "GenMsgILSupport" BO_ 680 1;
BA_ "OriginFrame" BO_ 680 "fuel,ev";
BA_ "VFrameFormat" BO_ 680 14;
BA_ "GenMsgCycleTime" BO_ 338 20;
BA_ "GenMsgILSupport" BO_ 338 1;
BA_ "OriginFrame" BO_ 338 "fuel,ev";
BA_ "VFrameFormat" BO_ 338 14;
BA_ "GenMsgCycleTime" BO_ 363 20;
BA_ "GenMsgILSupport" BO_ 363 1;
BA_ "OriginFrame" BO_ 363 "fuel,ev";
BA_ "VFrameFormat" BO_ 363 14;
BA_ "GenMsgCycleTime" BO_ 327 20;
BA_ "GenMsgILSupport" BO_ 327 1;
BA_ "OriginFrame" BO_ 327 "fuel,ev";
BA_ "VFrameFormat" BO_ 327 14;
BA_ "GenMsgCycleTime" BO_ 771 200;
BA_ "GenMsgCycleTimeFast" BO_ 771 20;
BA_ "GenMsgILSupport" BO_ 771 1;
BA_ "GenMsgNrOfRepetition" BO_ 771 5;
BA_ "OriginFrame" BO_ 771 "fuel,ev";
BA_ "VFrameFormat" BO_ 771 14;
BA_ "GenMsgCycleTime" BO_ 311 20;
BA_ "GenMsgILSupport" BO_ 311 1;
BA_ "OriginFrame" BO_ 311 "fuel,ev";
BA_ "SCP_AuthInfoTxLength" BO_ 311 48;
BA_ "SCP_DataId" BO_ 311 311;
BA_ "SCP_FreshnessValueLength" BO_ 311 64;
BA_ "SCP_FreshnessValueTxLength" BO_ 311 16;
BA_ "SC_Message" BO_ 311 1;
BA_ "VFrameFormat" BO_ 311 14;
BA_ "GenMsgCycleTime" BO_ 200 10;
BA_ "GenMsgILSupport" BO_ 200 1;
BA_ "OriginFrame" BO_ 200 "fuel,ev";
BA_ "VFrameFormat" BO_ 200 14;
BA_ "GenMsgCycleTime" BO_ 368 20;
BA_ "GenMsgILSupport" BO_ 368 1;
BA_ "OriginFrame" BO_ 368 "fuel,ev";
BA_ "VFrameFormat" BO_ 368 14;
BA_ "GenMsgCycleTime" BO_ 411 50;
BA_ "GenMsgILSupport" BO_ 411 1;
BA_ "OriginFrame" BO_ 411 "fuel,ev";
BA_ "VFrameFormat" BO_ 411 14;
BA_ "GenMsgCycleTime" BO_ 699 100;
BA_ "GenMsgILSupport" BO_ 699 1;
BA_ "OriginFrame" BO_ 699 "fuel,ev";
BA_ "VFrameFormat" BO_ 699 14;
BA_ "GenMsgCycleTime" BO_ 347 20;
BA_ "GenMsgILSupport" BO_ 347 1;
BA_ "OriginFrame" BO_ 347 "fuel,ev";
BA_ "VFrameFormat" BO_ 347 14;
BA_ "GenMsgCycleTime" BO_ 628 50;
BA_ "GenMsgILSupport" BO_ 628 1;
BA_ "OriginFrame" BO_ 628 "fuel,ev";
BA_ "VFrameFormat" BO_ 628 14;
BA_ "GenMsgCycleTime" BO_ 664 100;
BA_ "GenMsgILSupport" BO_ 664 1;
BA_ "OriginFrame" BO_ 664 "fuel,ev";
BA_ "VFrameFormat" BO_ 664 14;
BA_ "GenMsgCycleTime" BO_ 649 100;
BA_ "GenMsgILSupport" BO_ 649 1;
BA_ "OriginFrame" BO_ 649 "fuel,ev";
BA_ "VFrameFormat" BO_ 649 14;
BA_ "GenMsgCycleTime" BO_ 667 100;
BA_ "GenMsgILSupport" BO_ 667 1;
BA_ "OriginFrame" BO_ 667 "fuel,ev";
BA_ "VFrameFormat" BO_ 667 14;
BA_ "GenMsgCycleTime" BO_ 962 1000;
BA_ "GenMsgILSupport" BO_ 962 1;
BA_ "OriginFrame" BO_ 962 "fuel,ev";
BA_ "VFrameFormat" BO_ 962 14;
BA_ "GenSigCycleTime" SG_ 653 SecRowLeSeatVentSts 100;
BA_ "Match" SG_ 653 SecRowLeSeatVentSts "SecRowLeSeatVentSts";
BA_ "Origin" SG_ 653 SecRowLeSeatVentSts "fuel,ev";
BA_ "GenSigCycleTime" SG_ 653 SecRowRiSeatVentSts 100;
BA_ "Match" SG_ 653 SecRowRiSeatVentSts "SecRowRiSeatVentSts";
BA_ "Origin" SG_ 653 SecRowRiSeatVentSts "fuel,ev";
BA_ "GenSigCycleTime" SG_ 671 RemoteModSts 100;
BA_ "Match" SG_ 671 RemoteModSts "RemoteModSts";
BA_ "Origin" SG_ 671 RemoteModSts "fuel,ev";
BA_ "GenSigCycleTime" SG_ 671 PASWorkCmd 100;
BA_ "Match" SG_ 671 PASWorkCmd "PASWorkCmd";
BA_ "Origin" SG_ 671 PASWorkCmd "fuel,ev";
BA_ "GenSigCycleTime" SG_ 671 KL30BRelaySts 100;
BA_ "Match" SG_ 671 KL30BRelaySts "KL30BRelaySts";
BA_ "Origin" SG_ 671 KL30BRelaySts "fuel,ev";
BA_ "GenSigCycleTime" SG_ 671 RViewMirrorSts 100;
BA_ "Match" SG_ 671 RViewMirrorSts "RViewMirrorSts";
BA_ "Origin" SG_ 671 RViewMirrorSts "fuel,ev";
BA_ "GenSigCycleTime" SG_ 671 WiprReq_F_PBox 100;
BA_ "Match" SG_ 671 WiprReq_F_PBox "WiprReq_F_PBox";
BA_ "Origin" SG_ 671 WiprReq_F_PBox "fuel,ev";
BA_ "GenSigCycleTime" SG_ 671 DrivingModReq 100;
BA_ "Match" SG_ 671 DrivingModReq "DrivingModReq";
BA_ "Origin" SG_ 671 DrivingModReq "fuel,ev";
BA_ "GenSigCycleTime" SG_ 845 ColMemPosnSetSwtFB 500;
BA_ "Match" SG_ 845 ColMemPosnSetSwtFB "ColMemPosnSetSwtFB";
BA_ "Origin" SG_ 845 ColMemPosnSetSwtFB "fuel,ev";
BA_ "GenSigCycleTime" SG_ 241 BMS_ErrCategory 10;
BA_ "Match" SG_ 241 BMS_ErrCategory "BMS_ErrCategory";
BA_ "Origin" SG_ 241 BMS_ErrCategory "fuel,ev";
BA_ "GenSigCycleTime" SG_ 241 CheckSum_BMS4 10;
BA_ "Match" SG_ 241 CheckSum_BMS4 "CheckSum_BMS4";
BA_ "Origin" SG_ 241 CheckSum_BMS4 "ev,ev";
BA_ "GenSigCycleTime" SG_ 241 BMS_PackCurr 10;
BA_ "Match" SG_ 241 BMS_PackCurr "BMS_PackCurr";
BA_ "Origin" SG_ 241 BMS_PackCurr "ev,ev";
BA_ "GenSigCycleTime" SG_ 241 BMS_PackVolt 10;
BA_ "GenSigStartValue" SG_ 241 BMS_PackVolt 178;
BA_ "Match" SG_ 241 BMS_PackVolt "BMS_PackVolt";
BA_ "Origin" SG_ 241 BMS_PackVolt "ev,ev";
BA_ "GenSigCycleTime" SG_ 241 BMS_PowerDownCmplt 10;
BA_ "Match" SG_ 241 BMS_PowerDownCmplt "BMS_PowerDownCmplt";
BA_ "Origin" SG_ 241 BMS_PowerDownCmplt "ev,ev";
BA_ "GenSigCycleTime" SG_ 241 BMS_BattPoweErr 10;
BA_ "Match" SG_ 241 BMS_BattPoweErr "BMS_BattPoweErr";
BA_ "Origin" SG_ 241 BMS_BattPoweErr "ev,ev";
BA_ "GenSigCycleTime" SG_ 241 RollingCounter_BMS4 10;
BA_ "Match" SG_ 241 RollingCounter_BMS4 "RollingCounter_BMS4";
BA_ "Origin" SG_ 241 RollingCounter_BMS4 "ev,ev";
BA_ "GenSigCycleTime" SG_ 862 RoofModFb 500;
BA_ "Match" SG_ 862 RoofModFb "RoofModFb";
BA_ "Origin" SG_ 862 RoofModFb "fuel,ev";
BA_ "GenSigCycleTime" SG_ 862 AllTerrainDislFb 500;
BA_ "Match" SG_ 862 AllTerrainDislFb "AllTerrainDislFb";
BA_ "Origin" SG_ 862 AllTerrainDislFb "fuel,ev";
BA_ "GenSigCycleTime" SG_ 862 ElecSideStepSysFb 500;
BA_ "Match" SG_ 862 ElecSideStepSysFb "ElecSideStepSysFb";
BA_ "Origin" SG_ 862 ElecSideStepSysFb "fuel,ev";
BA_ "GenSigCycleTime" SG_ 350 CR_FCTA_Resp 20;
BA_ "Match" SG_ 350 CR_FCTA_Resp "CR_FCTA_Resp";
BA_ "Origin" SG_ 350 CR_FCTA_Resp "fuel,ev";
BA_ "GenSigCycleTime" SG_ 350 CR_FCTB_Resp 20;
BA_ "Match" SG_ 350 CR_FCTB_Resp "CR_FCTB_Resp";
BA_ "Origin" SG_ 350 CR_FCTB_Resp "fuel,ev";
BA_ "GenSigCycleTime" SG_ 350 CR_BliSts 20;
BA_ "Match" SG_ 350 CR_BliSts "CR_BliSts";
BA_ "Origin" SG_ 350 CR_BliSts "fuel,ev";
BA_ "GenSigCycleTime" SG_ 350 FCTA_Warn 20;
BA_ "Match" SG_ 350 FCTA_Warn "FCTA_Warn";
BA_ "Origin" SG_ 350 FCTA_Warn "fuel,ev";
BA_ "GenSigCycleTime" SG_ 350 FCTBTrig 20;
BA_ "Match" SG_ 350 FCTBTrig "FCTBTrig";
BA_ "Origin" SG_ 350 FCTBTrig "fuel,ev";
BA_ "GenSigCycleTime" SG_ 350 FCTA_B_FuncSts 20;
BA_ "Match" SG_ 350 FCTA_B_FuncSts "FCTA_B_FuncSts";
BA_ "Origin" SG_ 350 FCTA_B_FuncSts "fuel,ev";
BA_ "GenSigCycleTime" SG_ 350 FCTA_B_TTC 20;
BA_ "Match" SG_ 350 FCTA_B_TTC "FCTA_B_TTC";
BA_ "Origin" SG_ 350 FCTA_B_TTC "fuel,ev";
BA_ "GenSigCycleTime" SG_ 357 LTurnLmpSwtSts 20;
BA_ "Match" SG_ 357 LTurnLmpSwtSts "LTurnLmpSwtSts";
BA_ "Origin" SG_ 357 LTurnLmpSwtSts "fuel,ev";
BA_ "GenSigCycleTime" SG_ 357 RTurnLmpSwtSts 20;
BA_ "Match" SG_ 357 RTurnLmpSwtSts "RTurnLmpSwtSts";
BA_ "Origin" SG_ 357 RTurnLmpSwtSts "fuel,ev";
BA_ "GenSigCycleTime" SG_ 357 AutoLmpSwtSts 20;
BA_ "Match" SG_ 357 AutoLmpSwtSts "AutoLmpSwtSts";
BA_ "Origin" SG_ 357 AutoLmpSwtSts "fuel,ev";
BA_ "GenSigCycleTime" SG_ 357 HornSwtSts 20;
BA_ "Match" SG_ 357 HornSwtSts "HornSwtSts";
BA_ "Origin" SG_ 357 HornSwtSts "fuel,ev";
BA_ "GenSigCycleTime" SG_ 357 FrntWiprSwtSts 20;
BA_ "Match" SG_ 357 FrntWiprSwtSts "FrntWiprSwtSts";
BA_ "Origin" SG_ 357 FrntWiprSwtSts "fuel,ev";
BA_ "GenSigCycleTime" SG_ 161 SteerWheelAng 10;
BA_ "Match" SG_ 161 SteerWheelAng "SteerWheelAng";
BA_ "Origin" SG_ 161 SteerWheelAng "fuel,ev";
BA_ "GenSigCycleTime" SG_ 161 SteerWheelAngSign 10;
BA_ "Match" SG_ 161 SteerWheelAngSign "SteerWheelAngSign";
BA_ "Origin" SG_ 161 SteerWheelAngSign "fuel,ev";
BA_ "GenSigCycleTime" SG_ 161 SAS_Sts 10;
BA_ "Match" SG_ 161 SAS_Sts "SAS_Sts";
BA_ "Origin" SG_ 161 SAS_Sts "fuel,ev";
BA_ "GenSigCycleTime" SG_ 580 MenuReturnSwtSts 50;
BA_ "Match" SG_ 580 MenuReturnSwtSts "MenuReturnSwtSts";
BA_ "Origin" SG_ 580 MenuReturnSwtSts "fuel,ev";
BA_ "GenSigCycleTime" SG_ 580 SteerWheelHeatdSts 50;
BA_ "Match" SG_ 580 SteerWheelHeatdSts "SteerWheelHeatdSts";
BA_ "Origin" SG_ 580 SteerWheelHeatdSts "fuel,ev";
BA_ "GenSigCycleTime" SG_ 580 HomeSwtSts 50;
BA_ "Match" SG_ 580 HomeSwtSts "HomeSwtSts";
BA_ "Origin" SG_ 580 HomeSwtSts "fuel,ev";
BA_ "GenSigCycleTime" SG_ 580 MuteSwtSts 50;
BA_ "Match" SG_ 580 MuteSwtSts "MuteSwtSts";
BA_ "Origin" SG_ 580 MuteSwtSts "fuel,ev";
BA_ "GenSigCycleTime" SG_ 580 CustomSwtSts 50;
BA_ "Match" SG_ 580 CustomSwtSts "CustomSwtSts";
BA_ "Origin" SG_ 580 CustomSwtSts "fuel,ev";
BA_ "GenSigCycleTime" SG_ 580 PageUpSwtSts 50;
BA_ "Match" SG_ 580 PageUpSwtSts "PageUpSwtSts";
BA_ "Origin" SG_ 580 PageUpSwtSts "fuel,ev";
BA_ "GenSigCycleTime" SG_ 580 PageDwnSwtSts 50;
BA_ "Match" SG_ 580 PageDwnSwtSts "PageDwnSwtSts";
BA_ "Origin" SG_ 580 PageDwnSwtSts "fuel,ev";
BA_ "GenSigCycleTime" SG_ 580 PageLSwtSts 50;
BA_ "Match" SG_ 580 PageLSwtSts "PageLSwtSts";
BA_ "Origin" SG_ 580 PageLSwtSts "fuel,ev";
BA_ "GenSigCycleTime" SG_ 580 PageRSwtSts 50;
BA_ "Match" SG_ 580 PageRSwtSts "PageRSwtSts";
BA_ "Origin" SG_ 580 PageRSwtSts "fuel,ev";
BA_ "GenSigCycleTime" SG_ 580 SeekUpSwtSts 50;
BA_ "Match" SG_ 580 SeekUpSwtSts "SeekUpSwtSts";
BA_ "Origin" SG_ 580 SeekUpSwtSts "fuel,ev";
BA_ "GenSigCycleTime" SG_ 580 SeekDwnSwtSts 50;
BA_ "Match" SG_ 580 SeekDwnSwtSts "SeekDwnSwtSts";
BA_ "Origin" SG_ 580 SeekDwnSwtSts "fuel,ev";
BA_ "GenSigCycleTime" SG_ 580 AdjVolUpSwtSts 50;
BA_ "Match" SG_ 580 AdjVolUpSwtSts "AdjVolUpSwtSts";
BA_ "Origin" SG_ 580 AdjVolUpSwtSts "fuel,ev";
BA_ "GenSigCycleTime" SG_ 580 AdjVolDwnSwtSts 50;
BA_ "Match" SG_ 580 AdjVolDwnSwtSts "AdjVolDwnSwtSts";
BA_ "Origin" SG_ 580 AdjVolDwnSwtSts "fuel,ev";
BA_ "GenSigCycleTime" SG_ 580 VRSwtSts 50;
BA_ "Match" SG_ 580 VRSwtSts "VRSwtSts";
BA_ "Origin" SG_ 580 VRSwtSts "fuel,ev";
BA_ "GenSigCycleTime" SG_ 580 EnterSwtSts 50;
BA_ "Match" SG_ 580 EnterSwtSts "EnterSwtSts";
BA_ "Origin" SG_ 580 EnterSwtSts "fuel,ev";
BA_ "GenSigCycleTime" SG_ 580 EnterSwtSts_Mmed 50;
BA_ "Match" SG_ 580 EnterSwtSts_Mmed "EnterSwtSts_Mmed";
BA_ "Origin" SG_ 580 EnterSwtSts_Mmed "fuel,ev";
BA_ "GenSigCycleTime" SG_ 580 CustomSwtSts_Mmed 50;
BA_ "Match" SG_ 580 CustomSwtSts_Mmed "CustomSwtSts_Mmed";
BA_ "Origin" SG_ 580 CustomSwtSts_Mmed "fuel,ev";
BA_ "GenSigCycleTime" SG_ 580 IpMenuSwtSts 50;
BA_ "Match" SG_ 580 IpMenuSwtSts "IpMenuSwtSts";
BA_ "Origin" SG_ 580 IpMenuSwtSts "fuel,ev";
BA_ "GenSigCycleTime" SG_ 566 CheckSum_DCT7 50;
BA_ "Match" SG_ 566 CheckSum_DCT7 "CheckSum_DCT7";
BA_ "Origin" SG_ 566 CheckSum_DCT7 "fuel,ev";
BA_ "GenSigCycleTime" SG_ 566 TrsmStNID 50;
BA_ "Match" SG_ 566 TrsmStNID "TrsmStNID";
BA_ "Origin" SG_ 566 TrsmStNID "fuel,ev";
BA_ "GenSigCycleTime" SG_ 566 DCT_RaceModeSts 50;
BA_ "Match" SG_ 566 DCT_RaceModeSts "DCT_RaceModeSts";
BA_ "Origin" SG_ 566 DCT_RaceModeSts "fuel";
BA_ "GenSigCycleTime" SG_ 566 TRANS_OIL_TEMP 50;
BA_ "Match" SG_ 566 TRANS_OIL_TEMP "TRANS_OIL_TEMP";
BA_ "Origin" SG_ 566 TRANS_OIL_TEMP "fuel,ev";
BA_ "GenSigCycleTime" SG_ 566 DCT_PrsBrk_Warn 50;
BA_ "Match" SG_ 566 DCT_PrsBrk_Warn "DCT_PrsBrk_Warn";
BA_ "Origin" SG_ 566 DCT_PrsBrk_Warn "fuel,ev";
BA_ "GenSigCycleTime" SG_ 566 DCT_ShftNotAlwd_Warn 50;
BA_ "Match" SG_ 566 DCT_ShftNotAlwd_Warn "DCT_ShftNotAlwd_Warn";
BA_ "Origin" SG_ 566 DCT_ShftNotAlwd_Warn "fuel,ev";
BA_ "GenSigCycleTime" SG_ 566 DCT_ShftRecom_M 50;
BA_ "Match" SG_ 566 DCT_ShftRecom_M "DCT_ShftRecom_M";
BA_ "Origin" SG_ 566 DCT_ShftRecom_M "fuel,ev";
BA_ "GenSigCycleTime" SG_ 566 DrvWarnMsg 50;
BA_ "Match" SG_ 566 DrvWarnMsg "DrvWarnMsg";
BA_ "Origin" SG_ 566 DrvWarnMsg "fuel,ev";
BA_ "GenSigCycleTime" SG_ 566 DrvFaiMsg 50;
BA_ "Match" SG_ 566 DrvFaiMsg "DrvFaiMsg";
BA_ "Origin" SG_ 566 DrvFaiMsg "fuel,ev";
BA_ "GenSigCycleTime" SG_ 566 DrvModDisp 50;
BA_ "Match" SG_ 566 DrvModDisp "DrvModDisp";
BA_ "Origin" SG_ 566 DrvModDisp "fuel,ev";
BA_ "GenSigCycleTime" SG_ 566 DrvModDispSts 50;
BA_ "Match" SG_ 566 DrvModDispSts "DrvModDispSts";
BA_ "Origin" SG_ 566 DrvModDispSts "fuel,ev";
BA_ "GenSigCycleTime" SG_ 566 DrvAutoGearDisp 50;
BA_ "Match" SG_ 566 DrvAutoGearDisp "DrvAutoGearDisp";
BA_ "Origin" SG_ 566 DrvAutoGearDisp "fuel,ev";
BA_ "GenSigCycleTime" SG_ 566 DrvGearDispSts 50;
BA_ "Match" SG_ 566 DrvGearDispSts "DrvGearDispSts";
BA_ "Origin" SG_ 566 DrvGearDispSts "fuel,ev";
BA_ "GenSigCycleTime" SG_ 566 RollingCounter_DCT7 50;
BA_ "Match" SG_ 566 RollingCounter_DCT7 "RollingCounter_DCT7";
BA_ "Origin" SG_ 566 RollingCounter_DCT7 "fuel,ev";
BA_ "GenSigCycleTime" SG_ 166 TgtEngSpdIP 10;
BA_ "Match" SG_ 166 TgtEngSpdIP "TgtEngSpdIP";
BA_ "Origin" SG_ 166 TgtEngSpdIP "fuel,ev";
BA_ "GenSigCycleTime" SG_ 166 TgtEngSpdIPValid 10;
BA_ "Match" SG_ 166 TgtEngSpdIPValid "TgtEngSpdIPValid";
BA_ "Origin" SG_ 166 TgtEngSpdIPValid "fuel,ev";
BA_ "GenSigCycleTime" SG_ 545 CurrentGearValid 20;
BA_ "Match" SG_ 545 CurrentGearValid "CurrentGearValid";
BA_ "Origin" SG_ 545 CurrentGearValid "fuel,ev";
BA_ "GenSigCycleTime" SG_ 545 CURRENT_GEAR 20;
BA_ "Match" SG_ 545 CURRENT_GEAR "CURRENT_GEAR";
BA_ "Origin" SG_ 545 CURRENT_GEAR "fuel,ev";
BA_ "GenSigCycleTime" SG_ 545 TGS_LEVER 20;
BA_ "GenSigStartValue" SG_ 545 TGS_LEVER 14;
BA_ "Match" SG_ 545 TGS_LEVER "TGS_LEVER";
BA_ "Origin" SG_ 545 TGS_LEVER "fuel,ev";
BA_ "GenSigCycleTime" SG_ 545 TRANS_Warning_LAMP 20;
BA_ "Match" SG_ 545 TRANS_Warning_LAMP "TRANS_Warning_LAMP";
BA_ "Origin" SG_ 545 TRANS_Warning_LAMP "fuel,ev";
BA_ "GenSigCycleTime" SG_ 714 DrvWinPosnSts_Perc 100;
BA_ "Match" SG_ 714 DrvWinPosnSts_Perc "DrvWinPosnSts_Perc";
BA_ "Origin" SG_ 714 DrvWinPosnSts_Perc "fuel,ev";
BA_ "GenSigCycleTime" SG_ 714 DrvWinLrnSts 100;
BA_ "Match" SG_ 714 DrvWinLrnSts "DrvWinLrnSts";
BA_ "Origin" SG_ 714 DrvWinLrnSts "fuel,ev";
BA_ "GenSigCycleTime" SG_ 714 DrvWinHotProtSts 100;
BA_ "Match" SG_ 714 DrvWinHotProtSts "DrvWinHotProtSts";
BA_ "Origin" SG_ 714 DrvWinHotProtSts "fuel,ev";
BA_ "GenSigCycleTime" SG_ 714 DrvSideRearWinLrnSts 100;
BA_ "Match" SG_ 714 DrvSideRearWinLrnSts "DrvSideRearWinLrnSts";
BA_ "Origin" SG_ 714 DrvSideRearWinLrnSts "fuel,ev";
BA_ "GenSigCycleTime" SG_ 714 DrvSideRearWinHotProtSts 100;
BA_ "Match" SG_ 714 DrvSideRearWinHotProtSts "DrvSideRearWinHotProtSts";
BA_ "Origin" SG_ 714 DrvSideRearWinHotProtSts "fuel,ev";
BA_ "GenSigCycleTime" SG_ 759 DrvSideRearWinPosnSts_Perc 100;
BA_ "Match" SG_ 759 DrvSideRearWinPosnSts_Perc "DrvSideRearWinPosnSts_Perc";
BA_ "Origin" SG_ 759 DrvSideRearWinPosnSts_Perc "fuel,ev";
BA_ "GenSigCycleTime" SG_ 589 DrowsnsLvl 50;
BA_ "GenSigStartValue" SG_ 589 DrowsnsLvl 7;
BA_ "Match" SG_ 589 DrowsnsLvl "DrowsnsLvl";
BA_ "Origin" SG_ 589 DrowsnsLvl "fuel,ev";
BA_ "GenSigCycleTime" SG_ 589 DrowsnsLvlQlty 50;
BA_ "GenSigStartValue" SG_ 589 DrowsnsLvlQlty 127;
BA_ "Match" SG_ 589 DrowsnsLvlQlty "DrowsnsLvlQlty";
BA_ "Origin" SG_ 589 DrowsnsLvlQlty "fuel,ev";
BA_ "GenSigCycleTime" SG_ 589 GenderSts 50;
BA_ "GenSigStartValue" SG_ 589 GenderSts 3;
BA_ "Match" SG_ 589 GenderSts "GenderSts";
BA_ "Origin" SG_ 589 GenderSts "fuel,ev";
BA_ "GenSigCycleTime" SG_ 589 GenderStsQlty 50;
BA_ "GenSigStartValue" SG_ 589 GenderStsQlty 127;
BA_ "Match" SG_ 589 GenderStsQlty "GenderStsQlty";
BA_ "Origin" SG_ 589 GenderStsQlty "fuel,ev";
BA_ "GenSigCycleTime" SG_ 589 ExprsnSts 50;
BA_ "GenSigStartValue" SG_ 589 ExprsnSts 7;
BA_ "Match" SG_ 589 ExprsnSts "ExprsnSts";
BA_ "Origin" SG_ 589 ExprsnSts "fuel,ev";
BA_ "GenSigCycleTime" SG_ 589 Checksum_DMS2 50;
BA_ "Match" SG_ 589 Checksum_DMS2 "Checksum_DMS2";
BA_ "Origin" SG_ 589 Checksum_DMS2 "fuel,ev";
BA_ "GenSigCycleTime" SG_ 589 DistrctnLvl_ACC 50;
BA_ "GenSigStartValue" SG_ 589 DistrctnLvl_ACC 7;
BA_ "Match" SG_ 589 DistrctnLvl_ACC "DistrctnLvl_ACC";
BA_ "Origin" SG_ 589 DistrctnLvl_ACC "fuel,ev";
BA_ "GenSigCycleTime" SG_ 589 DistrctnLvlQlty_ACC 50;
BA_ "GenSigStartValue" SG_ 589 DistrctnLvlQlty_ACC 127;
BA_ "Match" SG_ 589 DistrctnLvlQlty_ACC "DistrctnLvlQlty_ACC";
BA_ "Origin" SG_ 589 DistrctnLvlQlty_ACC "fuel,ev";
BA_ "GenSigCycleTime" SG_ 589 DrowsnsLvl_ACC 50;
BA_ "GenSigStartValue" SG_ 589 DrowsnsLvl_ACC 7;
BA_ "Match" SG_ 589 DrowsnsLvl_ACC "DrowsnsLvl_ACC";
BA_ "Origin" SG_ 589 DrowsnsLvl_ACC "fuel,ev";
BA_ "GenSigCycleTime" SG_ 589 DrowsnsLvlQlty_ACC 50;
BA_ "GenSigStartValue" SG_ 589 DrowsnsLvlQlty_ACC 127;
BA_ "Match" SG_ 589 DrowsnsLvlQlty_ACC "DrowsnsLvlQlty_ACC";
BA_ "Origin" SG_ 589 DrowsnsLvlQlty_ACC "fuel,ev";
BA_ "GenSigCycleTime" SG_ 589 RollingCounter_DMS2 50;
BA_ "Match" SG_ 589 RollingCounter_DMS2 "RollingCounter_DMS2";
BA_ "Origin" SG_ 589 RollingCounter_DMS2 "fuel,ev";
BA_ "GenSigCycleTime" SG_ 589 Checksum_DMS3 50;
BA_ "Match" SG_ 589 Checksum_DMS3 "Checksum_DMS3";
BA_ "Origin" SG_ 589 Checksum_DMS3 "fuel,ev";
BA_ "GenSigCycleTime" SG_ 589 HeadPosnX 50;
BA_ "GenSigStartValue" SG_ 589 HeadPosnX 2047;
BA_ "Match" SG_ 589 HeadPosnX "HeadPosnX";
BA_ "Origin" SG_ 589 HeadPosnX "fuel,ev";
BA_ "GenSigCycleTime" SG_ 589 HeadPosnY 50;
BA_ "GenSigStartValue" SG_ 589 HeadPosnY 2047;
BA_ "Match" SG_ 589 HeadPosnY "HeadPosnY";
BA_ "Origin" SG_ 589 HeadPosnY "fuel,ev";
BA_ "GenSigCycleTime" SG_ 589 HeadPosnZ 50;
BA_ "GenSigStartValue" SG_ 589 HeadPosnZ 2047;
BA_ "Match" SG_ 589 HeadPosnZ "HeadPosnZ";
BA_ "Origin" SG_ 589 HeadPosnZ "fuel,ev";
BA_ "GenSigCycleTime" SG_ 589 HeadPosQlty 50;
BA_ "GenSigStartValue" SG_ 589 HeadPosQlty 127;
BA_ "Match" SG_ 589 HeadPosQlty "HeadPosQlty";
BA_ "Origin" SG_ 589 HeadPosQlty "fuel,ev";
BA_ "GenSigCycleTime" SG_ 589 RollingCounter_DMS3 50;
BA_ "Match" SG_ 589 RollingCounter_DMS3 "RollingCounter_DMS3";
BA_ "Origin" SG_ 589 RollingCounter_DMS3 "fuel,ev";
BA_ "GenSigCycleTime" SG_ 589 GazePosnX 50;
BA_ "GenSigStartValue" SG_ 589 GazePosnX 2047;
BA_ "Match" SG_ 589 GazePosnX "GazePosnX";
BA_ "Origin" SG_ 589 GazePosnX "fuel,ev";
BA_ "GenSigCycleTime" SG_ 589 GazePosnY 50;
BA_ "GenSigStartValue" SG_ 589 GazePosnY 2047;
BA_ "Match" SG_ 589 GazePosnY "GazePosnY";
BA_ "Origin" SG_ 589 GazePosnY "fuel,ev";
BA_ "GenSigCycleTime" SG_ 589 GazePosnZ 50;
BA_ "GenSigStartValue" SG_ 589 GazePosnZ 2047;
BA_ "Match" SG_ 589 GazePosnZ "GazePosnZ";
BA_ "Origin" SG_ 589 GazePosnZ "fuel,ev";
BA_ "GenSigCycleTime" SG_ 589 Checksum_DMS5 50;
BA_ "Match" SG_ 589 Checksum_DMS5 "Checksum_DMS5";
BA_ "Origin" SG_ 589 Checksum_DMS5 "fuel,ev";
BA_ "GenSigCycleTime" SG_ 589 DMSSts 50;
BA_ "GenSigStartValue" SG_ 589 DMSSts 7;
BA_ "Match" SG_ 589 DMSSts "DMSSts";
BA_ "Origin" SG_ 589 DMSSts "fuel,ev";
BA_ "GenSigCycleTime" SG_ 589 HeadDetn 50;
BA_ "Match" SG_ 589 HeadDetn "HeadDetn";
BA_ "Origin" SG_ 589 HeadDetn "fuel,ev";
BA_ "GenSigCycleTime" SG_ 589 HeadYawAng 50;
BA_ "GenSigStartValue" SG_ 589 HeadYawAng 255;
BA_ "Match" SG_ 589 HeadYawAng "HeadYawAng";
BA_ "Origin" SG_ 589 HeadYawAng "fuel,ev";
BA_ "GenSigCycleTime" SG_ 589 HeadPitchAng 50;
BA_ "GenSigStartValue" SG_ 589 HeadPitchAng 255;
BA_ "Match" SG_ 589 HeadPitchAng "HeadPitchAng";
BA_ "Origin" SG_ 589 HeadPitchAng "fuel,ev";
BA_ "GenSigCycleTime" SG_ 589 HeadRollAng 50;
BA_ "GenSigStartValue" SG_ 589 HeadRollAng 255;
BA_ "Match" SG_ 589 HeadRollAng "HeadRollAng";
BA_ "Origin" SG_ 589 HeadRollAng "fuel,ev";
BA_ "GenSigCycleTime" SG_ 589 HeadRotAngQlty 50;
BA_ "GenSigStartValue" SG_ 589 HeadRotAngQlty 127;
BA_ "Match" SG_ 589 HeadRotAngQlty "HeadRotAngQlty";
BA_ "Origin" SG_ 589 HeadRotAngQlty "fuel,ev";
BA_ "GenSigCycleTime" SG_ 589 RollingCounter_DMS5 50;
BA_ "Match" SG_ 589 RollingCounter_DMS5 "RollingCounter_DMS5";
BA_ "Origin" SG_ 589 RollingCounter_DMS5 "fuel,ev";
BA_ "GenSigCycleTime" SG_ 589 Checksum_DMS6 50;
BA_ "Match" SG_ 589 Checksum_DMS6 "Checksum_DMS6";
BA_ "Origin" SG_ 589 Checksum_DMS6 "fuel,ev";
BA_ "GenSigCycleTime" SG_ 589 LEyeOpenSts 50;
BA_ "GenSigStartValue" SG_ 589 LEyeOpenSts 2;
BA_ "Match" SG_ 589 LEyeOpenSts "LEyeOpenSts";
BA_ "Origin" SG_ 589 LEyeOpenSts "fuel,ev";
BA_ "GenSigCycleTime" SG_ 589 LEyeOpenStsQlty 50;
BA_ "GenSigStartValue" SG_ 589 LEyeOpenStsQlty 100;
BA_ "Match" SG_ 589 LEyeOpenStsQlty "LEyeOpenStsQlty";
BA_ "Origin" SG_ 589 LEyeOpenStsQlty "fuel,ev";
BA_ "GenSigCycleTime" SG_ 589 REyeOpenSts 50;
BA_ "GenSigStartValue" SG_ 589 REyeOpenSts 2;
BA_ "Match" SG_ 589 REyeOpenSts "REyeOpenSts";
BA_ "Origin" SG_ 589 REyeOpenSts "fuel,ev";
BA_ "GenSigCycleTime" SG_ 589 REyeOpenStsQlty 50;
BA_ "GenSigStartValue" SG_ 589 REyeOpenStsQlty 100;
BA_ "Match" SG_ 589 REyeOpenStsQlty "REyeOpenStsQlty";
BA_ "Origin" SG_ 589 REyeOpenStsQlty "fuel,ev";
BA_ "GenSigCycleTime" SG_ 589 RobustGazeYawAng 50;
BA_ "GenSigStartValue" SG_ 589 RobustGazeYawAng 255;
BA_ "Match" SG_ 589 RobustGazeYawAng "RobustGazeYawAng";
BA_ "Origin" SG_ 589 RobustGazeYawAng "fuel,ev";
BA_ "GenSigCycleTime" SG_ 589 RobustGazePitchAng 50;
BA_ "GenSigStartValue" SG_ 589 RobustGazePitchAng 255;
BA_ "Match" SG_ 589 RobustGazePitchAng "RobustGazePitchAng";
BA_ "Origin" SG_ 589 RobustGazePitchAng "fuel,ev";
BA_ "GenSigCycleTime" SG_ 589 RobustGazeAngQlty 50;
BA_ "GenSigStartValue" SG_ 589 RobustGazeAngQlty 127;
BA_ "Match" SG_ 589 RobustGazeAngQlty "RobustGazeAngQlty";
BA_ "Origin" SG_ 589 RobustGazeAngQlty "fuel,ev";
BA_ "GenSigCycleTime" SG_ 589 DrvBehvSts 50;
BA_ "GenSigStartValue" SG_ 589 DrvBehvSts 7;
BA_ "Match" SG_ 589 DrvBehvSts "DrvBehvSts";
BA_ "Origin" SG_ 589 DrvBehvSts "fuel,ev";
BA_ "GenSigCycleTime" SG_ 589 RollingCounter_DMS6 50;
BA_ "Match" SG_ 589 RollingCounter_DMS6 "RollingCounter_DMS6";
BA_ "Origin" SG_ 589 RollingCounter_DMS6 "fuel,ev";
BA_ "GenSigCycleTime" SG_ 705 ChairMemPosnSetSwtFB 100;
BA_ "Match" SG_ 705 ChairMemPosnSetSwtFB "ChairMemPosnSetSwtFB";
BA_ "Origin" SG_ 705 ChairMemPosnSetSwtFB "fuel,ev";
BA_ "GenSigCycleTime" SG_ 748 DVR_360VideoCaptureReq 100;
BA_ "Match" SG_ 748 DVR_360VideoCaptureReq "DVR_360VideoCaptureReq";
BA_ "Origin" SG_ 748 DVR_360VideoCaptureReq "fuel,ev";
BA_ "GenSigCycleTime" SG_ 748 DVRRemtCnSts 100;
BA_ "Match" SG_ 748 DVRRemtCnSts "DVRRemtCnSts";
BA_ "Origin" SG_ 748 DVRRemtCnSts "fuel,ev";
BA_ "GenSigCycleTime" SG_ 748 DVRSN 100;
BA_ "Match" SG_ 748 DVRSN "DVRSN";
BA_ "Origin" SG_ 748 DVRSN "fuel,ev";
BA_ "GenSigCycleTime" SG_ 748 DVRSts 100;
BA_ "Match" SG_ 748 DVRSts "DVRSts";
BA_ "Origin" SG_ 748 DVRSts "fuel,ev";
BA_ "GenSigCycleTime" SG_ 656 EngOilLvl 100;
BA_ "Match" SG_ 656 EngOilLvl "EngOilLvl";
BA_ "Origin" SG_ 656 EngOilLvl "fuel";
BA_ "GenSigCycleTime" SG_ 656 FTIVFault 100;
BA_ "Match" SG_ 656 FTIVFault "FTIVFault";
BA_ "Origin" SG_ 656 FTIVFault "ev";
BA_ "GenSigCycleTime" SG_ 656 FuelTankCapWarning 100;
BA_ "Match" SG_ 656 FuelTankCapWarning "FuelTankCapWarning";
BA_ "Origin" SG_ 656 FuelTankCapWarning "ev";
BA_ "GenSigCycleTime" SG_ 656 PressReliProgs 100;
BA_ "Match" SG_ 656 PressReliProgs "PressReliProgs";
BA_ "Origin" SG_ 656 PressReliProgs "ev";
BA_ "GenSigCycleTime" SG_ 273 EMS_AuthenResult 10;
BA_ "Match" SG_ 273 EMS_AuthenResult "EMS_AuthenResult";
BA_ "Origin" SG_ 273 EMS_AuthenResult "fuel";
BA_ "GenSigCycleTime" SG_ 273 EngSpd 10;
BA_ "Match" SG_ 273 EngSpd "EngSpd";
BA_ "Origin" SG_ 273 EngSpd "fuel";
BA_ "GenSigCycleTime" SG_ 273 EngSpdVldty 10;
BA_ "GenSigStartValue" SG_ 273 EngSpdVldty 2;
BA_ "Match" SG_ 273 EngSpdVldty "EngSpdVldty";
BA_ "Origin" SG_ 273 EngSpdVldty "fuel";
BA_ "GenSigCycleTime" SG_ 273 EngSpd_PHEV 10;
BA_ "Match" SG_ 273 EngSpd_PHEV "EngSpd_PHEV";
BA_ "Origin" SG_ 273 EngSpd_PHEV "ev";
BA_ "GenSigCycleTime" SG_ 273 EngSpdVldty_PHEV 10;
BA_ "GenSigStartValue" SG_ 273 EngSpdVldty_PHEV 2;
BA_ "Match" SG_ 273 EngSpdVldty_PHEV "EngSpdVldty_PHEV";
BA_ "Origin" SG_ 273 EngSpdVldty_PHEV "ev";
BA_ "GenSigCycleTime" SG_ 723 EngSpd_ForIP 100;
BA_ "Match" SG_ 723 EngSpd_ForIP "EngSpd_ForIP";
BA_ "Origin" SG_ 723 EngSpd_ForIP "fuel,ev";
BA_ "GenSigCycleTime" SG_ 723 EWP_Err 100;
BA_ "Match" SG_ 723 EWP_Err "EWP_Err";
BA_ "Origin" SG_ 723 EWP_Err "fuel,ev";
BA_ "GenSigCycleTime" SG_ 949 ECM_VIN 1000;
BA_ "Match" SG_ 949 ECM_VIN "ECM_VIN";
BA_ "Origin" SG_ 949 ECM_VIN "fuel,ev";
BA_ "GenSigCycleTime" SG_ 625 FuelConsumption 20;
BA_ "Match" SG_ 625 FuelConsumption "FuelConsumption";
BA_ "Origin" SG_ 625 FuelConsumption "fuel,ev";
BA_ "GenSigCycleTime" SG_ 625 TgtCrsVehSpd 20;
BA_ "Match" SG_ 625 TgtCrsVehSpd "TgtCrsVehSpd";
BA_ "Origin" SG_ 625 TgtCrsVehSpd "fuel,ev";
BA_ "GenSigCycleTime" SG_ 625 CruiseCtrlSts 20;
BA_ "Match" SG_ 625 CruiseCtrlSts "CruiseCtrlSts";
BA_ "Origin" SG_ 625 CruiseCtrlSts "fuel";
BA_ "GenSigCycleTime" SG_ 625 AccelPedalPosn 20;
BA_ "Match" SG_ 625 AccelPedalPosn "AccelPedalPosn";
BA_ "Origin" SG_ 625 AccelPedalPosn "fuel";
BA_ "GenSigCycleTime" SG_ 625 AccelPedalPosnVldty 20;
BA_ "GenSigStartValue" SG_ 625 AccelPedalPosnVldty 2;
BA_ "Match" SG_ 625 AccelPedalPosnVldty "AccelPedalPosnVldty";
BA_ "Origin" SG_ 625 AccelPedalPosnVldty "fuel";
BA_ "GenSigCycleTime" SG_ 625 ThrtlPosRatio 20;
BA_ "Match" SG_ 625 ThrtlPosRatio "ThrtlPosRatio";
BA_ "Origin" SG_ 625 ThrtlPosRatio "fuel,ev";
BA_ "GenSigCycleTime" SG_ 625 EngSVSSig 20;
BA_ "Match" SG_ 625 EngSVSSig "EngSVSSig";
BA_ "Origin" SG_ 625 EngSVSSig "fuel,ev";
BA_ "GenSigCycleTime" SG_ 625 MILSts 20;
BA_ "Match" SG_ 625 MILSts "MILSts";
BA_ "Origin" SG_ 625 MILSts "fuel,ev";
BA_ "GenSigCycleTime" SG_ 625 EngState 20;
BA_ "Match" SG_ 625 EngState "EngState";
BA_ "Origin" SG_ 625 EngState "fuel";
BA_ "GenSigCycleTime" SG_ 951 ECM_VehDstBackup 1000;
BA_ "Match" SG_ 951 ECM_VehDstBackup "ECM_VehDstBackup";
BA_ "Origin" SG_ 951 ECM_VehDstBackup "fuel,ev";
BA_ "GenSigCycleTime" SG_ 881 BaroPressure 100;
BA_ "Match" SG_ 881 BaroPressure "BaroPressure";
BA_ "Origin" SG_ 881 BaroPressure "fuel,ev";
BA_ "GenSigCycleTime" SG_ 881 EngCoolantTemp 100;
BA_ "Match" SG_ 881 EngCoolantTemp "EngCoolantTemp";
BA_ "Origin" SG_ 881 EngCoolantTemp "fuel,ev";
BA_ "GenSigCycleTime" SG_ 881 GPF_Warning 100;
BA_ "Match" SG_ 881 GPF_Warning "GPF_Warning";
BA_ "Origin" SG_ 881 GPF_Warning "fuel,ev";
BA_ "GenSigCycleTime" SG_ 881 GentrWarnLmpSts 100;
BA_ "Match" SG_ 881 GentrWarnLmpSts "GentrWarnLmpSts";
BA_ "Origin" SG_ 881 GentrWarnLmpSts "fuel";
BA_ "GenSigCycleTime" SG_ 881 EngClntTempWarn 100;
BA_ "Match" SG_ 881 EngClntTempWarn "EngClntTempWarn";
BA_ "Origin" SG_ 881 EngClntTempWarn "fuel,ev";
BA_ "GenSigCycleTime" SG_ 881 EngClntTempVldty 100;
BA_ "GenSigStartValue" SG_ 881 EngClntTempVldty 2;
BA_ "Match" SG_ 881 EngClntTempVldty "EngClntTempVldty";
BA_ "Origin" SG_ 881 EngClntTempVldty "fuel,ev";
BA_ "GenSigCycleTime" SG_ 881 SS_Screen_tip 100;
BA_ "Match" SG_ 881 SS_Screen_tip "SS_Screen_tip";
BA_ "Origin" SG_ 881 SS_Screen_tip "fuel";
BA_ "GenSigCycleTime" SG_ 881 SSSSetSts 100;
BA_ "GenSigStartValue" SG_ 881 SSSSetSts 1;
BA_ "Match" SG_ 881 SSSSetSts "SSSSetSts";
BA_ "Origin" SG_ 881 SSSSetSts "fuel";
BA_ "GenSigCycleTime" SG_ 881 SS_Enable_Lamp 100;
BA_ "Match" SG_ 881 SS_Enable_Lamp "SS_Enable_Lamp";
BA_ "Origin" SG_ 881 SS_Enable_Lamp "fuel";
BA_ "GenSigCycleTime" SG_ 881 SS_Fault_Lamp 100;
BA_ "Match" SG_ 881 SS_Fault_Lamp "SS_Fault_Lamp";
BA_ "Origin" SG_ 881 SS_Fault_Lamp "fuel";
BA_ "GenSigCycleTime" SG_ 881 MaxEngTrqNorm 100;
BA_ "Match" SG_ 881 MaxEngTrqNorm "MaxEngTrqNorm";
BA_ "Origin" SG_ 881 MaxEngTrqNorm "fuel";
BA_ "GenSigCycleTime" SG_ 881 AGS_Failure 100;
BA_ "Match" SG_ 881 AGS_Failure "AGS_Failure";
BA_ "Origin" SG_ 881 AGS_Failure "fuel";
BA_ "GenSigCycleTime" SG_ 680 TranPMode_Sts 100;
BA_ "Match" SG_ 680 TranPMode_Sts "TranPMode_Sts";
BA_ "Origin" SG_ 680 TranPMode_Sts "fuel,ev";
BA_ "GenSigCycleTime" SG_ 680 Stat_PwrSv_Lvl 100;
BA_ "Match" SG_ 680 Stat_PwrSv_Lvl "Stat_PwrSv_Lvl";
BA_ "Origin" SG_ 680 Stat_PwrSv_Lvl "fuel,ev";
BA_ "GenSigCycleTime" SG_ 680 Dyn_PwrSv_Lvl 100;
BA_ "Match" SG_ 680 Dyn_PwrSv_Lvl "Dyn_PwrSv_Lvl";
BA_ "Origin" SG_ 680 Dyn_PwrSv_Lvl "fuel,ev";
BA_ "GenSigCycleTime" SG_ 680 LvPwrSysErr 100;
BA_ "Match" SG_ 680 LvPwrSysErr "LvPwrSysErr";
BA_ "Origin" SG_ 680 LvPwrSysErr "fuel,ev";
BA_ "GenSigCycleTime" SG_ 338 FrntELDLckSts 20;
BA_ "Match" SG_ 338 FrntELDLckSts "FrntELDLckSts";
BA_ "Origin" SG_ 338 FrntELDLckSts "fuel,ev";
BA_ "GenSigCycleTime" SG_ 338 RearELDLckSts 20;
BA_ "Match" SG_ 338 RearELDLckSts "RearELDLckSts";
BA_ "Origin" SG_ 338 RearELDLckSts "fuel,ev";
BA_ "GenSigCycleTime" SG_ 363 CheckSum_EPB1 20;
BA_ "Match" SG_ 363 CheckSum_EPB1 "CheckSum_EPB1";
BA_ "Origin" SG_ 363 CheckSum_EPB1 "fuel,ev";
BA_ "GenSigCycleTime" SG_ 363 EPBErrSts 20;
BA_ "Match" SG_ 363 EPBErrSts "EPBErrSts";
BA_ "Origin" SG_ 363 EPBErrSts "fuel,ev";
BA_ "GenSigCycleTime" SG_ 363 EPBRedLmpSts 20;
BA_ "Match" SG_ 363 EPBRedLmpSts "EPBRedLmpSts";
BA_ "Origin" SG_ 363 EPBRedLmpSts "fuel,ev";
BA_ "GenSigCycleTime" SG_ 363 EPBSts 20;
BA_ "Match" SG_ 363 EPBSts "EPBSts";
BA_ "Origin" SG_ 363 EPBSts "fuel,ev";
BA_ "GenSigCycleTime" SG_ 363 EPBTextDisp 20;
BA_ "Match" SG_ 363 EPBTextDisp "EPBTextDisp";
BA_ "Origin" SG_ 363 EPBTextDisp "fuel,ev";
BA_ "GenSigCycleTime" SG_ 363 PressBrakePedalPointOut 20;
BA_ "Match" SG_ 363 PressBrakePedalPointOut "PressBrakePedalPointOut";
BA_ "Origin" SG_ 363 PressBrakePedalPointOut "fuel,ev";
BA_ "GenSigCycleTime" SG_ 363 RollingCounter_EPB1 20;
BA_ "Match" SG_ 363 RollingCounter_EPB1 "RollingCounter_EPB1";
BA_ "Origin" SG_ 363 RollingCounter_EPB1 "fuel,ev";
BA_ "GenSigCycleTime" SG_ 327 CheckSum_EPS1 20;
BA_ "Match" SG_ 327 CheckSum_EPS1 "CheckSum_EPS1";
BA_ "Origin" SG_ 327 CheckSum_EPS1 "fuel,ev";
BA_ "GenSigCycleTime" SG_ 327 EPS_FailSts 20;
BA_ "Match" SG_ 327 EPS_FailSts "EPS_FailSts";
BA_ "Origin" SG_ 327 EPS_FailSts "fuel,ev";
BA_ "GenSigCycleTime" SG_ 327 EPS_SteerMod 20;
BA_ "Match" SG_ 327 EPS_SteerMod "EPS_SteerMod";
BA_ "Origin" SG_ 327 EPS_SteerMod "fuel,ev";
BA_ "GenSigCycleTime" SG_ 327 SteerCorrnRmn 20;
BA_ "Match" SG_ 327 SteerCorrnRmn "SteerCorrnRmn";
BA_ "Origin" SG_ 327 SteerCorrnRmn "fuel,ev";
BA_ "GenSigCycleTime" SG_ 327 SteerCorrnResp 20;
BA_ "GenSigStartValue" SG_ 327 SteerCorrnResp 1;
BA_ "Match" SG_ 327 SteerCorrnResp "SteerCorrnResp";
BA_ "Origin" SG_ 327 SteerCorrnResp "fuel,ev";
BA_ "GenSigCycleTime" SG_ 327 RollingCounter_EPS1 20;
BA_ "Match" SG_ 327 RollingCounter_EPS1 "RollingCounter_EPS1";
BA_ "Origin" SG_ 327 RollingCounter_EPS1 "fuel,ev";
BA_ "GenSigCycleTime" SG_ 771 RotSteerWheel 200;
BA_ "GenSigSendType" SG_ 771 RotSteerWheel 2;
BA_ "Match" SG_ 771 RotSteerWheel "RotSteerWheel";
BA_ "Origin" SG_ 771 RotSteerWheel "fuel,ev";
BA_ "GenSigCycleTime" SG_ 311 CheckSum_ESP2 20;
BA_ "Match" SG_ 311 CheckSum_ESP2 "CheckSum_ESP2";
BA_ "Origin" SG_ 311 CheckSum_ESP2 "fuel,ev";
BA_ "GenSigCycleTime" SG_ 311 HDCFault 20;
BA_ "Match" SG_ 311 HDCFault "HDCFault";
BA_ "Origin" SG_ 311 HDCFault "fuel,ev";
BA_ "GenSigCycleTime" SG_ 311 HDCCtrl 20;
BA_ "Match" SG_ 311 HDCCtrl "HDCCtrl";
BA_ "Origin" SG_ 311 HDCCtrl "fuel,ev";
BA_ "GenSigCycleTime" SG_ 311 AVHErrSts 20;
BA_ "Match" SG_ 311 AVHErrSts "AVHErrSts";
BA_ "Origin" SG_ 311 AVHErrSts "fuel,ev";
BA_ "GenSigCycleTime" SG_ 311 AVHSts 20;
BA_ "Match" SG_ 311 AVHSts "AVHSts";
BA_ "Origin" SG_ 311 AVHSts "fuel,ev";
BA_ "GenSigCycleTime" SG_ 311 CDPActv 20;
BA_ "Match" SG_ 311 CDPActv "CDPActv";
BA_ "Origin" SG_ 311 CDPActv "fuel,ev";
BA_ "GenSigCycleTime" SG_ 311 DrivingModDis 20;
BA_ "Match" SG_ 311 DrivingModDis "DrivingModDis";
BA_ "Origin" SG_ 311 DrivingModDis "fuel,ev";
BA_ "GenSigCycleTime" SG_ 311 DrivingModReq_ESP 20;
BA_ "GenSigStartValue" SG_ 311 DrivingModReq_ESP 1;
BA_ "Match" SG_ 311 DrivingModReq_ESP "DrivingModReq_ESP";
BA_ "Origin" SG_ 311 DrivingModReq_ESP "fuel,ev";
BA_ "GenSigCycleTime" SG_ 311 Shift_N_Warn 20;
BA_ "Match" SG_ 311 Shift_N_Warn "Shift_N_Warn";
BA_ "Origin" SG_ 311 Shift_N_Warn "fuel,ev";
BA_ "GenSigCycleTime" SG_ 311 Over_Spd_Warn 20;
BA_ "Match" SG_ 311 Over_Spd_Warn "Over_Spd_Warn";
BA_ "Origin" SG_ 311 Over_Spd_Warn "fuel,ev";
BA_ "GenSigCycleTime" SG_ 311 FourL_Warn 20;
BA_ "Match" SG_ 311 FourL_Warn "FourL_Warn";
BA_ "Origin" SG_ 311 FourL_Warn "fuel,ev";
BA_ "GenSigCycleTime" SG_ 311 TAB_Sts 20;
BA_ "Match" SG_ 311 TAB_Sts "TAB_Sts";
BA_ "Origin" SG_ 311 TAB_Sts "fuel,ev";
BA_ "GenSigCycleTime" SG_ 311 RollingCounter_ESP2 20;
BA_ "Match" SG_ 311 RollingCounter_ESP2 "RollingCounter_ESP2";
BA_ "Origin" SG_ 311 RollingCounter_ESP2 "fuel,ev";
BA_ "GenSigCycleTime" SG_ 311 CheckSum_ESP1 20;
BA_ "Match" SG_ 311 CheckSum_ESP1 "CheckSum_ESP1";
BA_ "Origin" SG_ 311 CheckSum_ESP1 "fuel,ev";
BA_ "GenSigCycleTime" SG_ 311 ESPFuncOffSts 20;
BA_ "Match" SG_ 311 ESPFuncOffSts "ESPFuncOffSts";
BA_ "Origin" SG_ 311 ESPFuncOffSts "fuel,ev";
BA_ "GenSigCycleTime" SG_ 311 ESPActvInfoLmp 20;
BA_ "Match" SG_ 311 ESPActvInfoLmp "ESPActvInfoLmp";
BA_ "Origin" SG_ 311 ESPActvInfoLmp "fuel,ev";
BA_ "GenSigCycleTime" SG_ 311 ESPFailSts 20;
BA_ "Match" SG_ 311 ESPFailSts "ESPFailSts";
BA_ "Origin" SG_ 311 ESPFailSts "fuel,ev";
BA_ "GenSigCycleTime" SG_ 311 IMC_Actv 20;
BA_ "Match" SG_ 311 IMC_Actv "IMC_Actv";
BA_ "Origin" SG_ 311 IMC_Actv "fuel,ev";
BA_ "GenSigCycleTime" SG_ 311 RollingCounter_ESP1 20;
BA_ "Match" SG_ 311 RollingCounter_ESP1 "RollingCounter_ESP1";
BA_ "Origin" SG_ 311 RollingCounter_ESP1 "fuel,ev";
BA_ "GenSigCycleTime" SG_ 311 CheckSum_ABS3 20;
BA_ "Match" SG_ 311 CheckSum_ABS3 "CheckSum_ABS3";
BA_ "Origin" SG_ 311 CheckSum_ABS3 "fuel,ev";
BA_ "GenSigCycleTime" SG_ 311 ABSActv 20;
BA_ "Match" SG_ 311 ABSActv "ABSActv";
BA_ "Origin" SG_ 311 ABSActv "fuel,ev";
BA_ "GenSigCycleTime" SG_ 311 ABSFailSts 20;
BA_ "GenSigStartValue" SG_ 311 ABSFailSts 1;
BA_ "Match" SG_ 311 ABSFailSts "ABSFailSts";
BA_ "Origin" SG_ 311 ABSFailSts "fuel,ev";
BA_ "GenSigCycleTime" SG_ 311 EBDFailSts 20;
BA_ "Match" SG_ 311 EBDFailSts "EBDFailSts";
BA_ "Origin" SG_ 311 EBDFailSts "fuel,ev";
BA_ "GenSigCycleTime" SG_ 311 VehSpdVld 20;
BA_ "Match" SG_ 311 VehSpdVld "VehSpdVld";
BA_ "Origin" SG_ 311 VehSpdVld "fuel,ev";
BA_ "GenSigCycleTime" SG_ 311 VehSpd 20;
BA_ "Match" SG_ 311 VehSpd "VehSpd";
BA_ "Origin" SG_ 311 VehSpd "fuel,ev";
BA_ "GenSigCycleTime" SG_ 311 VehOdoInfoSts 20;
BA_ "GenSigStartValue" SG_ 311 VehOdoInfoSts 1;
BA_ "Match" SG_ 311 VehOdoInfoSts "VehOdoInfoSts";
BA_ "Origin" SG_ 311 VehOdoInfoSts "fuel,ev";
BA_ "GenSigCycleTime" SG_ 311 VehOdoInfo 20;
BA_ "Match" SG_ 311 VehOdoInfo "VehOdoInfo";
BA_ "Origin" SG_ 311 VehOdoInfo "fuel,ev";
BA_ "GenSigCycleTime" SG_ 311 RollingCounter_ABS3 20;
BA_ "Match" SG_ 311 RollingCounter_ABS3 "RollingCounter_ABS3";
BA_ "Origin" SG_ 311 RollingCounter_ABS3 "fuel,ev";
BA_ "GenSigCycleTime" SG_ 311 FreshnessValue_ESP_FD2 20;
BA_ "Match" SG_ 311 FreshnessValue_ESP_FD2 "FreshnessValue_ESP_FD2";
BA_ "Origin" SG_ 311 FreshnessValue_ESP_FD2 "fuel";
BA_ "GenSigCycleTime" SG_ 311 MAC_Check_ESP_FD2 20;
BA_ "Match" SG_ 311 MAC_Check_ESP_FD2 "MAC_Check_ESP_FD2";
BA_ "Origin" SG_ 311 MAC_Check_ESP_FD2 "fuel";
BA_ "GenSigCycleTime" SG_ 200 ESP_HMI_WarningOn 10;
BA_ "Match" SG_ 200 ESP_HMI_WarningOn "ESP_HMI_WarningOn";
BA_ "Origin" SG_ 200 ESP_HMI_WarningOn "fuel,ev";
BA_ "GenSigCycleTime" SG_ 200 WadeModeWarn 10;
BA_ "Match" SG_ 200 WadeModeWarn "WadeModeWarn";
BA_ "Origin" SG_ 200 WadeModeWarn "fuel,ev";
BA_ "GenSigCycleTime" SG_ 368 CCO_Warn 20;
BA_ "Match" SG_ 368 CCO_Warn "CCO_Warn";
BA_ "Origin" SG_ 368 CCO_Warn "fuel,ev";
BA_ "GenSigCycleTime" SG_ 368 CCO_Active 20;
BA_ "Match" SG_ 368 CCO_Active "CCO_Active";
BA_ "Origin" SG_ 368 CCO_Active "fuel,ev";
BA_ "GenSigCycleTime" SG_ 368 CCO_TgtVel 20;
BA_ "Match" SG_ 368 CCO_TgtVel "CCO_TgtVel";
BA_ "Origin" SG_ 368 CCO_TgtVel "fuel,ev";
BA_ "GenSigCycleTime" SG_ 368 EspFuncOffSts_mode 20;
BA_ "Match" SG_ 368 EspFuncOffSts_mode "EspFuncOffSts_mode";
BA_ "Origin" SG_ 368 EspFuncOffSts_mode "fuel,ev";
BA_ "GenSigCycleTime" SG_ 411 FFogLmpSts_F_PBox 50;
BA_ "Match" SG_ 411 FFogLmpSts_F_PBox "FFogLmpSts_F_PBox";
BA_ "Origin" SG_ 411 FFogLmpSts_F_PBox "fuel,ev";
BA_ "GenSigCycleTime" SG_ 411 HiBeamSts_F_PBox 50;
BA_ "Match" SG_ 411 HiBeamSts_F_PBox "HiBeamSts_F_PBox";
BA_ "Origin" SG_ 411 HiBeamSts_F_PBox "fuel,ev";
BA_ "GenSigCycleTime" SG_ 411 HoodSts_F_PBox 50;
BA_ "Match" SG_ 411 HoodSts_F_PBox "HoodSts_F_PBox";
BA_ "Origin" SG_ 411 HoodSts_F_PBox "fuel,ev";
BA_ "GenSigCycleTime" SG_ 411 LasHdLmpSts_F_PBox 50;
BA_ "Match" SG_ 411 LasHdLmpSts_F_PBox "LasHdLmpSts_F_PBox";
BA_ "Origin" SG_ 411 LasHdLmpSts_F_PBox "fuel,ev";
BA_ "GenSigCycleTime" SG_ 411 LHiBeamFailSts 50;
BA_ "Match" SG_ 411 LHiBeamFailSts "LHiBeamFailSts";
BA_ "Origin" SG_ 411 LHiBeamFailSts "fuel,ev";
BA_ "GenSigCycleTime" SG_ 411 RHiBeamFailSts 50;
BA_ "Match" SG_ 411 RHiBeamFailSts "RHiBeamFailSts";
BA_ "Origin" SG_ 411 RHiBeamFailSts "fuel,ev";
BA_ "GenSigCycleTime" SG_ 411 LLowBeamFailSts 50;
BA_ "Match" SG_ 411 LLowBeamFailSts "LLowBeamFailSts";
BA_ "Origin" SG_ 411 LLowBeamFailSts "fuel,ev";
BA_ "GenSigCycleTime" SG_ 411 LHeadLmpFailSts 50;
BA_ "Match" SG_ 411 LHeadLmpFailSts "LHeadLmpFailSts";
BA_ "Origin" SG_ 411 LHeadLmpFailSts "fuel,ev";
BA_ "GenSigCycleTime" SG_ 411 RHeadLmpFailSts 50;
BA_ "Match" SG_ 411 RHeadLmpFailSts "RHeadLmpFailSts";
BA_ "Origin" SG_ 411 RHeadLmpFailSts "fuel,ev";
BA_ "GenSigCycleTime" SG_ 411 RLowBeamFailSts 50;
BA_ "Match" SG_ 411 RLowBeamFailSts "RLowBeamFailSts";
BA_ "Origin" SG_ 411 RLowBeamFailSts "fuel,ev";
BA_ "GenSigCycleTime" SG_ 411 RLasHdLmpDiagSig 50;
BA_ "Match" SG_ 411 RLasHdLmpDiagSig "RLasHdLmpDiagSig";
BA_ "Origin" SG_ 411 RLasHdLmpDiagSig "fuel,ev";
BA_ "GenSigCycleTime" SG_ 411 LLasHdLmpDiagSig 50;
BA_ "Match" SG_ 411 LLasHdLmpDiagSig "LLasHdLmpDiagSig";
BA_ "Origin" SG_ 411 LLasHdLmpDiagSig "fuel,ev";
BA_ "GenSigCycleTime" SG_ 411 LowBeamSts_F_PBox 50;
BA_ "Match" SG_ 411 LowBeamSts_F_PBox "LowBeamSts_F_PBox";
BA_ "Origin" SG_ 411 LowBeamSts_F_PBox "fuel,ev";
BA_ "GenSigCycleTime" SG_ 411 WhistleSts_F_PBox 50;
BA_ "Match" SG_ 411 WhistleSts_F_PBox "WhistleSts_F_PBox";
BA_ "Origin" SG_ 411 WhistleSts_F_PBox "fuel,ev";
BA_ "GenSigCycleTime" SG_ 699 U_BATT 100;
BA_ "GenSigStartValue" SG_ 699 U_BATT 16383;
BA_ "Match" SG_ 699 U_BATT "U_BATT";
BA_ "Origin" SG_ 699 U_BATT "fuel,ev";
BA_ "GenSigCycleTime" SG_ 699 I_RANGE 100;
BA_ "GenSigStartValue" SG_ 699 I_RANGE 3;
BA_ "Match" SG_ 699 I_RANGE "I_RANGE";
BA_ "Origin" SG_ 699 I_RANGE "fuel,ev";
BA_ "GenSigCycleTime" SG_ 699 I_BATT 100;
BA_ "GenSigStartValue" SG_ 699 I_BATT 65535;
BA_ "Match" SG_ 699 I_BATT "I_BATT";
BA_ "Origin" SG_ 699 I_BATT "fuel,ev";
BA_ "GenSigCycleTime" SG_ 699 SOC 100;
BA_ "GenSigStartValue" SG_ 699 SOC 255;
BA_ "Match" SG_ 699 SOC "SOC";
BA_ "Origin" SG_ 699 SOC "fuel,ev";
BA_ "GenSigCycleTime" SG_ 699 SOH_SUL 100;
BA_ "GenSigStartValue" SG_ 699 SOH_SUL 255;
BA_ "Match" SG_ 699 SOH_SUL "SOH_SUL";
BA_ "Origin" SG_ 699 SOH_SUL "fuel,ev";
BA_ "GenSigCycleTime" SG_ 699 SOC_STATE 100;
BA_ "GenSigStartValue" SG_ 699 SOC_STATE 3;
BA_ "Match" SG_ 699 SOC_STATE "SOC_STATE";
BA_ "Origin" SG_ 699 SOC_STATE "fuel,ev";
BA_ "GenSigCycleTime" SG_ 699 SOH_SUL_STATE 100;
BA_ "GenSigStartValue" SG_ 699 SOH_SUL_STATE 3;
BA_ "Match" SG_ 699 SOH_SUL_STATE "SOH_SUL_STATE";
BA_ "Origin" SG_ 699 SOH_SUL_STATE "fuel,ev";
BA_ "GenSigCycleTime" SG_ 699 OTA_UpgrdModSts 100;
BA_ "Match" SG_ 699 OTA_UpgrdModSts "OTA_UpgrdModSts";
BA_ "Origin" SG_ 699 OTA_UpgrdModSts "fuel,ev";
BA_ "GenSigCycleTime" SG_ 699 CheckSum_GWM1 100;
BA_ "Match" SG_ 699 CheckSum_GWM1 "CheckSum_GWM1";
BA_ "Origin" SG_ 699 CheckSum_GWM1 "fuel,ev";
BA_ "GenSigCycleTime" SG_ 699 RollingCounter_GWM1 100;
BA_ "Match" SG_ 699 RollingCounter_GWM1 "RollingCounter_GWM1";
BA_ "Origin" SG_ 699 RollingCounter_GWM1 "fuel,ev";
BA_ "GenSigCycleTime" SG_ 347 APS_PrkgMod 20;
BA_ "Match" SG_ 347 APS_PrkgMod "APS_PrkgMod";
BA_ "Origin" SG_ 347 APS_PrkgMod "fuel,ev";
BA_ "GenSigCycleTime" SG_ 347 APS_ProcBar 20;
BA_ "GenSigStartValue" SG_ 347 APS_ProcBar 127;
BA_ "Match" SG_ 347 APS_ProcBar "APS_ProcBar";
BA_ "Origin" SG_ 347 APS_ProcBar "fuel,ev";
BA_ "GenSigCycleTime" SG_ 347 APS_SwtSts 20;
BA_ "Match" SG_ 347 APS_SwtSts "APS_SwtSts";
BA_ "Origin" SG_ 347 APS_SwtSts "fuel,ev";
BA_ "GenSigCycleTime" SG_ 347 APS_SlotDisp 20;
BA_ "Match" SG_ 347 APS_SlotDisp "APS_SlotDisp";
BA_ "Origin" SG_ 347 APS_SlotDisp "fuel,ev";
BA_ "GenSigCycleTime" SG_ 347 APS_SysSoundIndcn 20;
BA_ "Match" SG_ 347 APS_SysSoundIndcn "APS_SysSoundIndcn";
BA_ "Origin" SG_ 347 APS_SysSoundIndcn "fuel,ev";
BA_ "GenSigCycleTime" SG_ 347 APS_PrkgTyp 20;
BA_ "Match" SG_ 347 APS_PrkgTyp "APS_PrkgTyp";
BA_ "Origin" SG_ 347 APS_PrkgTyp "fuel,ev";
BA_ "GenSigCycleTime" SG_ 347 APS_TextDisp 20;
BA_ "Match" SG_ 347 APS_TextDisp "APS_TextDisp";
BA_ "Origin" SG_ 347 APS_TextDisp "fuel,ev";
BA_ "GenSigCycleTime" SG_ 347 APS_WorkSts 20;
BA_ "Match" SG_ 347 APS_WorkSts "APS_WorkSts";
BA_ "Origin" SG_ 347 APS_WorkSts "fuel,ev";
BA_ "GenSigCycleTime" SG_ 347 MEB_AVHReq 20;
BA_ "Match" SG_ 347 MEB_AVHReq "MEB_AVHReq";
BA_ "Origin" SG_ 347 MEB_AVHReq "fuel,ev";
BA_ "GenSigCycleTime" SG_ 347 APS_ESP_BrkDistance 20;
BA_ "Match" SG_ 347 APS_ESP_BrkDistance "APS_ESP_BrkDistance";
BA_ "Origin" SG_ 347 APS_ESP_BrkDistance "fuel,ev";
BA_ "GenSigCycleTime" SG_ 347 LParaPrkgOutVald 20;
BA_ "Match" SG_ 347 LParaPrkgOutVald "LParaPrkgOutVald";
BA_ "Origin" SG_ 347 LParaPrkgOutVald "fuel,ev";
BA_ "GenSigCycleTime" SG_ 347 RParaPrkgOutVald 20;
BA_ "Match" SG_ 347 RParaPrkgOutVald "RParaPrkgOutVald";
BA_ "Origin" SG_ 347 RParaPrkgOutVald "fuel,ev";
BA_ "GenSigCycleTime" SG_ 347 HeadVertPrkgOutVald 20;
BA_ "Match" SG_ 347 HeadVertPrkgOutVald "HeadVertPrkgOutVald";
BA_ "Origin" SG_ 347 HeadVertPrkgOutVald "fuel,ev";
BA_ "GenSigCycleTime" SG_ 347 TailVertPrkgOutVald 20;
BA_ "Match" SG_ 347 TailVertPrkgOutVald "TailVertPrkgOutVald";
BA_ "Origin" SG_ 347 TailVertPrkgOutVald "fuel,ev";
BA_ "GenSigCycleTime" SG_ 347 HAP_SwtDispCtrlCmd 20;
BA_ "Match" SG_ 347 HAP_SwtDispCtrlCmd "HAP_SwtDispCtrlCmd";
BA_ "Origin" SG_ 347 HAP_SwtDispCtrlCmd "fuel,ev";
BA_ "GenSigCycleTime" SG_ 347 HAP_PrkgModCurrSts 20;
BA_ "Match" SG_ 347 HAP_PrkgModCurrSts "HAP_PrkgModCurrSts";
BA_ "Origin" SG_ 347 HAP_PrkgModCurrSts "fuel,ev";
BA_ "GenSigCycleTime" SG_ 347 APS_MovgDirc 20;
BA_ "Match" SG_ 347 APS_MovgDirc "APS_MovgDirc";
BA_ "Origin" SG_ 347 APS_MovgDirc "fuel,ev";
BA_ "GenSigCycleTime" SG_ 347 ParallelSlotBtn_Ena 20;
BA_ "Match" SG_ 347 ParallelSlotBtn_Ena "ParallelSlotBtn_Ena";
BA_ "Origin" SG_ 347 ParallelSlotBtn_Ena "fuel,ev";
BA_ "GenSigCycleTime" SG_ 347 VerticalSlotBtn_Ena 20;
BA_ "Match" SG_ 347 VerticalSlotBtn_Ena "VerticalSlotBtn_Ena";
BA_ "Origin" SG_ 347 VerticalSlotBtn_Ena "fuel,ev";
BA_ "GenSigCycleTime" SG_ 347 ClockwiseBtn_Ena 20;
BA_ "Match" SG_ 347 ClockwiseBtn_Ena "ClockwiseBtn_Ena";
BA_ "Origin" SG_ 347 ClockwiseBtn_Ena "fuel,ev";
BA_ "GenSigCycleTime" SG_ 347 AnticlockwiseBtn_Ena 20;
BA_ "Match" SG_ 347 AnticlockwiseBtn_Ena "AnticlockwiseBtn_Ena";
BA_ "Origin" SG_ 347 AnticlockwiseBtn_Ena "fuel,ev";
BA_ "GenSigCycleTime" SG_ 347 SlotConfirmBtn_Ena 20;
BA_ "Match" SG_ 347 SlotConfirmBtn_Ena "SlotConfirmBtn_Ena";
BA_ "Origin" SG_ 347 SlotConfirmBtn_Ena "fuel,ev";
BA_ "GenSigCycleTime" SG_ 347 HAVP_StopBtn_Ena 20;
BA_ "Match" SG_ 347 HAVP_StopBtn_Ena "HAVP_StopBtn_Ena";
BA_ "Origin" SG_ 347 HAVP_StopBtn_Ena "fuel,ev";
BA_ "GenSigCycleTime" SG_ 347 HAVP_StartBtn_Ena 20;
BA_ "Match" SG_ 347 HAVP_StartBtn_Ena "HAVP_StartBtn_Ena";
BA_ "Origin" SG_ 347 HAVP_StartBtn_Ena "fuel,ev";
BA_ "GenSigCycleTime" SG_ 347 HAVP_SelfParLotEnding_Ena 20;
BA_ "Match" SG_ 347 HAVP_SelfParLotEnding_Ena "HAVP_SelfParLotEnding_Ena";
BA_ "Origin" SG_ 347 HAVP_SelfParLotEnding_Ena "fuel,ev";
BA_ "GenSigCycleTime" SG_ 347 PAVP_TextDis 20;
BA_ "Match" SG_ 347 PAVP_TextDis "PAVP_TextDis";
BA_ "Origin" SG_ 347 PAVP_TextDis "fuel,ev";
BA_ "GenSigCycleTime" SG_ 628 AutoAVMSwtSet_Sts 50;
BA_ "Match" SG_ 628 AutoAVMSwtSet_Sts "AutoAVMSwtSet_Sts";
BA_ "Origin" SG_ 628 AutoAVMSwtSet_Sts "fuel,ev";
BA_ "GenSigCycleTime" SG_ 628 AVM_CurrSts 50;
BA_ "Match" SG_ 628 AVM_CurrSts "AVM_CurrSts";
BA_ "Origin" SG_ 628 AVM_CurrSts "fuel,ev";
BA_ "GenSigCycleTime" SG_ 628 GuidOvlSts 50;
BA_ "Match" SG_ 628 GuidOvlSts "GuidOvlSts";
BA_ "Origin" SG_ 628 GuidOvlSts "fuel,ev";
BA_ "GenSigCycleTime" SG_ 628 FrntCamInpFailSts 50;
BA_ "Match" SG_ 628 FrntCamInpFailSts "FrntCamInpFailSts";
BA_ "Origin" SG_ 628 FrntCamInpFailSts "fuel,ev";
BA_ "GenSigCycleTime" SG_ 628 RearCamInpFailSts 50;
BA_ "Match" SG_ 628 RearCamInpFailSts "RearCamInpFailSts";
BA_ "Origin" SG_ 628 RearCamInpFailSts "fuel,ev";
BA_ "GenSigCycleTime" SG_ 628 LeCamInpFailSts 50;
BA_ "Match" SG_ 628 LeCamInpFailSts "LeCamInpFailSts";
BA_ "Origin" SG_ 628 LeCamInpFailSts "fuel,ev";
BA_ "GenSigCycleTime" SG_ 628 RiCamInpFailSts 50;
BA_ "Match" SG_ 628 RiCamInpFailSts "RiCamInpFailSts";
BA_ "Origin" SG_ 628 RiCamInpFailSts "fuel,ev";
BA_ "GenSigCycleTime" SG_ 628 EolNotCmpltd 50;
BA_ "Match" SG_ 628 EolNotCmpltd "EolNotCmpltd";
BA_ "Origin" SG_ 628 EolNotCmpltd "fuel,ev";
BA_ "GenSigCycleTime" SG_ 628 OvlOpFailSts 50;
BA_ "Match" SG_ 628 OvlOpFailSts "OvlOpFailSts";
BA_ "Origin" SG_ 628 OvlOpFailSts "fuel,ev";
BA_ "GenSigCycleTime" SG_ 628 LaneCalSts 50;
BA_ "Match" SG_ 628 LaneCalSts "LaneCalSts";
BA_ "Origin" SG_ 628 LaneCalSts "fuel,ev";
BA_ "GenSigCycleTime" SG_ 628 RadarDispSts 50;
BA_ "Match" SG_ 628 RadarDispSts "RadarDispSts";
BA_ "Origin" SG_ 628 RadarDispSts "fuel,ev";
BA_ "GenSigCycleTime" SG_ 628 LaneCalFltSts 50;
BA_ "Match" SG_ 628 LaneCalFltSts "LaneCalFltSts";
BA_ "Origin" SG_ 628 LaneCalFltSts "fuel,ev";
BA_ "GenSigCycleTime" SG_ 628 AutoViewChgFuncSts 50;
BA_ "Match" SG_ 628 AutoViewChgFuncSts "AutoViewChgFuncSts";
BA_ "Origin" SG_ 628 AutoViewChgFuncSts "fuel,ev";
BA_ "GenSigCycleTime" SG_ 628 CarMdlTrsprcySts 50;
BA_ "Match" SG_ 628 CarMdlTrsprcySts "CarMdlTrsprcySts";
BA_ "Origin" SG_ 628 CarMdlTrsprcySts "fuel,ev";
BA_ "GenSigCycleTime" SG_ 628 CarMdlDispSts 50;
BA_ "Match" SG_ 628 CarMdlDispSts "CarMdlDispSts";
BA_ "Origin" SG_ 628 CarMdlDispSts "fuel,ev";
BA_ "GenSigCycleTime" SG_ 628 CurrCalResultSts 50;
BA_ "Match" SG_ 628 CurrCalResultSts "CurrCalResultSts";
BA_ "Origin" SG_ 628 CurrCalResultSts "fuel,ev";
BA_ "GenSigCycleTime" SG_ 628 MdlColrSts 50;
BA_ "Match" SG_ 628 MdlColrSts "MdlColrSts";
BA_ "Origin" SG_ 628 MdlColrSts "fuel,ev";
BA_ "GenSigCycleTime" SG_ 628 SigViewIndcn 50;
BA_ "Match" SG_ 628 SigViewIndcn "SigViewIndcn";
BA_ "Origin" SG_ 628 SigViewIndcn "fuel,ev";
BA_ "GenSigCycleTime" SG_ 628 HAP_DispCmd 50;
BA_ "Match" SG_ 628 HAP_DispCmd "HAP_DispCmd";
BA_ "Origin" SG_ 628 HAP_DispCmd "fuel,ev";
BA_ "GenSigCycleTime" SG_ 628 AVM_3DAngSts 50;
BA_ "Match" SG_ 628 AVM_3DAngSts "AVM_3DAngSts";
BA_ "Origin" SG_ 628 AVM_3DAngSts "fuel,ev";
BA_ "GenSigCycleTime" SG_ 628 MOD_WorkSts 50;
BA_ "Match" SG_ 628 MOD_WorkSts "MOD_WorkSts";
BA_ "Origin" SG_ 628 MOD_WorkSts "fuel,ev";
BA_ "GenSigCycleTime" SG_ 628 MOD_AlarmSts 50;
BA_ "Match" SG_ 628 MOD_AlarmSts "MOD_AlarmSts";
BA_ "Origin" SG_ 628 MOD_AlarmSts "fuel,ev";
BA_ "GenSigCycleTime" SG_ 628 DVRWorkSts 50;
BA_ "Match" SG_ 628 DVRWorkSts "DVRWorkSts";
BA_ "Origin" SG_ 628 DVRWorkSts "fuel,ev";
BA_ "GenSigCycleTime" SG_ 628 HAP_Hmi_Index 50;
BA_ "Match" SG_ 628 HAP_Hmi_Index "HAP_Hmi_Index";
BA_ "Origin" SG_ 628 HAP_Hmi_Index "fuel,ev";
BA_ "GenSigCycleTime" SG_ 664 RPAS_NearBrrdstn 100;
BA_ "GenSigStartValue" SG_ 664 RPAS_NearBrrdstn 255;
BA_ "Match" SG_ 664 RPAS_NearBrrdstn "RPAS_NearBrrdstn";
BA_ "Origin" SG_ 664 RPAS_NearBrrdstn "fuel,ev";
BA_ "GenSigCycleTime" SG_ 664 HAVP_ProcRa 100;
BA_ "GenSigStartValue" SG_ 664 HAVP_ProcRa 127;
BA_ "Match" SG_ 664 HAVP_ProcRa "HAVP_ProcRa";
BA_ "Origin" SG_ 664 HAVP_ProcRa "fuel,ev";
BA_ "GenSigCycleTime" SG_ 664 APS_ObjRiSideAr1 100;
BA_ "Match" SG_ 664 APS_ObjRiSideAr1 "APS_ObjRiSideAr1";
BA_ "Origin" SG_ 664 APS_ObjRiSideAr1 "fuel,ev";
BA_ "GenSigCycleTime" SG_ 664 APS_ObjRiSideAr2 100;
BA_ "Match" SG_ 664 APS_ObjRiSideAr2 "APS_ObjRiSideAr2";
BA_ "Origin" SG_ 664 APS_ObjRiSideAr2 "fuel,ev";
BA_ "GenSigCycleTime" SG_ 664 APS_ObjRiSideAr3 100;
BA_ "Match" SG_ 664 APS_ObjRiSideAr3 "APS_ObjRiSideAr3";
BA_ "Origin" SG_ 664 APS_ObjRiSideAr3 "fuel,ev";
BA_ "GenSigCycleTime" SG_ 664 APS_ObjRiSideAr4 100;
BA_ "Match" SG_ 664 APS_ObjRiSideAr4 "APS_ObjRiSideAr4";
BA_ "Origin" SG_ 664 APS_ObjRiSideAr4 "fuel,ev";
BA_ "GenSigCycleTime" SG_ 664 APS_ObjRiSideAr5 100;
BA_ "Match" SG_ 664 APS_ObjRiSideAr5 "APS_ObjRiSideAr5";
BA_ "Origin" SG_ 664 APS_ObjRiSideAr5 "fuel,ev";
BA_ "GenSigCycleTime" SG_ 664 APS_ObjLeSideAr1 100;
BA_ "Match" SG_ 664 APS_ObjLeSideAr1 "APS_ObjLeSideAr1";
BA_ "Origin" SG_ 664 APS_ObjLeSideAr1 "fuel,ev";
BA_ "GenSigCycleTime" SG_ 664 APS_ObjLeSideAr2 100;
BA_ "Match" SG_ 664 APS_ObjLeSideAr2 "APS_ObjLeSideAr2";
BA_ "Origin" SG_ 664 APS_ObjLeSideAr2 "fuel,ev";
BA_ "GenSigCycleTime" SG_ 664 APS_ObjLeSideAr3 100;
BA_ "Match" SG_ 664 APS_ObjLeSideAr3 "APS_ObjLeSideAr3";
BA_ "Origin" SG_ 664 APS_ObjLeSideAr3 "fuel,ev";
BA_ "GenSigCycleTime" SG_ 664 APS_ObjLeSideAr4 100;
BA_ "Match" SG_ 664 APS_ObjLeSideAr4 "APS_ObjLeSideAr4";
BA_ "Origin" SG_ 664 APS_ObjLeSideAr4 "fuel,ev";
BA_ "GenSigCycleTime" SG_ 664 APS_ObjLeSideAr5 100;
BA_ "Match" SG_ 664 APS_ObjLeSideAr5 "APS_ObjLeSideAr5";
BA_ "Origin" SG_ 664 APS_ObjLeSideAr5 "fuel,ev";
BA_ "GenSigCycleTime" SG_ 664 APS_FRSideSnsrFailSts 100;
BA_ "Match" SG_ 664 APS_FRSideSnsrFailSts "APS_FRSideSnsrFailSts";
BA_ "Origin" SG_ 664 APS_FRSideSnsrFailSts "fuel,ev";
BA_ "GenSigCycleTime" SG_ 664 APS_FLSideSnsrFailSts 100;
BA_ "Match" SG_ 664 APS_FLSideSnsrFailSts "APS_FLSideSnsrFailSts";
BA_ "Origin" SG_ 664 APS_FLSideSnsrFailSts "fuel,ev";
BA_ "GenSigCycleTime" SG_ 664 APS_RRSideSnsrFailSts 100;
BA_ "Match" SG_ 664 APS_RRSideSnsrFailSts "APS_RRSideSnsrFailSts";
BA_ "Origin" SG_ 664 APS_RRSideSnsrFailSts "fuel,ev";
BA_ "GenSigCycleTime" SG_ 664 APS_RLSideSnsrFailSts 100;
BA_ "Match" SG_ 664 APS_RLSideSnsrFailSts "APS_RLSideSnsrFailSts";
BA_ "Origin" SG_ 664 APS_RLSideSnsrFailSts "fuel,ev";
BA_ "GenSigCycleTime" SG_ 664 SDW_SoundIndcn 100;
BA_ "Match" SG_ 664 SDW_SoundIndcn "SDW_SoundIndcn";
BA_ "Origin" SG_ 664 SDW_SoundIndcn "fuel,ev";
BA_ "GenSigCycleTime" SG_ 664 SDWActiveSts 100;
BA_ "Match" SG_ 664 SDWActiveSts "SDWActiveSts";
BA_ "Origin" SG_ 664 SDWActiveSts "fuel,ev";
BA_ "GenSigCycleTime" SG_ 664 RPAS_ObjRRCornrAr1 100;
BA_ "Match" SG_ 664 RPAS_ObjRRCornrAr1 "RPAS_ObjRRCornrAr1";
BA_ "Origin" SG_ 664 RPAS_ObjRRCornrAr1 "fuel,ev";
BA_ "GenSigCycleTime" SG_ 664 RPAS_ObjRRCornrAr2 100;
BA_ "Match" SG_ 664 RPAS_ObjRRCornrAr2 "RPAS_ObjRRCornrAr2";
BA_ "Origin" SG_ 664 RPAS_ObjRRCornrAr2 "fuel,ev";
BA_ "GenSigCycleTime" SG_ 664 RPAS_ObjRRMidlAr1 100;
BA_ "Match" SG_ 664 RPAS_ObjRRMidlAr1 "RPAS_ObjRRMidlAr1";
BA_ "Origin" SG_ 664 RPAS_ObjRRMidlAr1 "fuel,ev";
BA_ "GenSigCycleTime" SG_ 664 RPAS_ObjRRMidlAr2 100;
BA_ "Match" SG_ 664 RPAS_ObjRRMidlAr2 "RPAS_ObjRRMidlAr2";
BA_ "Origin" SG_ 664 RPAS_ObjRRMidlAr2 "fuel,ev";
BA_ "GenSigCycleTime" SG_ 664 RPAS_ObjRLMidlAr1 100;
BA_ "Match" SG_ 664 RPAS_ObjRLMidlAr1 "RPAS_ObjRLMidlAr1";
BA_ "Origin" SG_ 664 RPAS_ObjRLMidlAr1 "fuel,ev";
BA_ "GenSigCycleTime" SG_ 664 RPAS_ObjRLMidlAr2 100;
BA_ "Match" SG_ 664 RPAS_ObjRLMidlAr2 "RPAS_ObjRLMidlAr2";
BA_ "Origin" SG_ 664 RPAS_ObjRLMidlAr2 "fuel,ev";
BA_ "GenSigCycleTime" SG_ 664 RPAS_ObjRLCornrAr1 100;
BA_ "Match" SG_ 664 RPAS_ObjRLCornrAr1 "RPAS_ObjRLCornrAr1";
BA_ "Origin" SG_ 664 RPAS_ObjRLCornrAr1 "fuel,ev";
BA_ "GenSigCycleTime" SG_ 664 RPAS_ObjRLCornrAr2 100;
BA_ "Match" SG_ 664 RPAS_ObjRLCornrAr2 "RPAS_ObjRLCornrAr2";
BA_ "Origin" SG_ 664 RPAS_ObjRLCornrAr2 "fuel,ev";
BA_ "GenSigCycleTime" SG_ 664 RPAS_RLCornrSnsrFailSts 100;
BA_ "Match" SG_ 664 RPAS_RLCornrSnsrFailSts "RPAS_RLCornrSnsrFailSts";
BA_ "Origin" SG_ 664 RPAS_RLCornrSnsrFailSts "fuel,ev";
BA_ "GenSigCycleTime" SG_ 664 RPAS_RLMiddlSnsrFailSts 100;
BA_ "Match" SG_ 664 RPAS_RLMiddlSnsrFailSts "RPAS_RLMiddlSnsrFailSts";
BA_ "Origin" SG_ 664 RPAS_RLMiddlSnsrFailSts "fuel,ev";
BA_ "GenSigCycleTime" SG_ 664 RPAS_RRMiddlSnsrFailSts 100;
BA_ "Match" SG_ 664 RPAS_RRMiddlSnsrFailSts "RPAS_RRMiddlSnsrFailSts";
BA_ "Origin" SG_ 664 RPAS_RRMiddlSnsrFailSts "fuel,ev";
BA_ "GenSigCycleTime" SG_ 664 RPAS_RRCornrSnsrFailSts 100;
BA_ "Match" SG_ 664 RPAS_RRCornrSnsrFailSts "RPAS_RRCornrSnsrFailSts";
BA_ "Origin" SG_ 664 RPAS_RRCornrSnsrFailSts "fuel,ev";
BA_ "GenSigCycleTime" SG_ 664 RPAS_WorkSts 100;
BA_ "Match" SG_ 664 RPAS_WorkSts "RPAS_WorkSts";
BA_ "Origin" SG_ 664 RPAS_WorkSts "fuel,ev";
BA_ "GenSigCycleTime" SG_ 664 RPAS_SoundIndcn 100;
BA_ "Match" SG_ 664 RPAS_SoundIndcn "RPAS_SoundIndcn";
BA_ "Origin" SG_ 664 RPAS_SoundIndcn "fuel,ev";
BA_ "GenSigCycleTime" SG_ 664 MEBWorkSts 100;
BA_ "Match" SG_ 664 MEBWorkSts "MEBWorkSts";
BA_ "Origin" SG_ 664 MEBWorkSts "fuel,ev";
BA_ "GenSigCycleTime" SG_ 664 MEB_EnableSts 100;
BA_ "Match" SG_ 664 MEB_EnableSts "MEB_EnableSts";
BA_ "Origin" SG_ 664 MEB_EnableSts "fuel,ev";
BA_ "GenSigCycleTime" SG_ 664 FPAS_ObjFLCornrAr1 100;
BA_ "Match" SG_ 664 FPAS_ObjFLCornrAr1 "FPAS_ObjFLCornrAr1";
BA_ "Origin" SG_ 664 FPAS_ObjFLCornrAr1 "fuel,ev";
BA_ "GenSigCycleTime" SG_ 664 FPAS_ObjFLCornrAr2 100;
BA_ "Match" SG_ 664 FPAS_ObjFLCornrAr2 "FPAS_ObjFLCornrAr2";
BA_ "Origin" SG_ 664 FPAS_ObjFLCornrAr2 "fuel,ev";
BA_ "GenSigCycleTime" SG_ 664 FPAS_ObjFLMidlAr1 100;
BA_ "Match" SG_ 664 FPAS_ObjFLMidlAr1 "FPAS_ObjFLMidlAr1";
BA_ "Origin" SG_ 664 FPAS_ObjFLMidlAr1 "fuel,ev";
BA_ "GenSigCycleTime" SG_ 664 FPAS_ObjFLMidlAr2 100;
BA_ "Match" SG_ 664 FPAS_ObjFLMidlAr2 "FPAS_ObjFLMidlAr2";
BA_ "Origin" SG_ 664 FPAS_ObjFLMidlAr2 "fuel,ev";
BA_ "GenSigCycleTime" SG_ 664 FPAS_ObjFRMidlAr1 100;
BA_ "Match" SG_ 664 FPAS_ObjFRMidlAr1 "FPAS_ObjFRMidlAr1";
BA_ "Origin" SG_ 664 FPAS_ObjFRMidlAr1 "fuel,ev";
BA_ "GenSigCycleTime" SG_ 664 FPAS_ObjFRMidlAr2 100;
BA_ "Match" SG_ 664 FPAS_ObjFRMidlAr2 "FPAS_ObjFRMidlAr2";
BA_ "Origin" SG_ 664 FPAS_ObjFRMidlAr2 "fuel,ev";
BA_ "GenSigCycleTime" SG_ 664 FPAS_ObjFRCornrAr1 100;
BA_ "Match" SG_ 664 FPAS_ObjFRCornrAr1 "FPAS_ObjFRCornrAr1";
BA_ "Origin" SG_ 664 FPAS_ObjFRCornrAr1 "fuel,ev";
BA_ "GenSigCycleTime" SG_ 664 FPAS_ObjFRCornrAr2 100;
BA_ "Match" SG_ 664 FPAS_ObjFRCornrAr2 "FPAS_ObjFRCornrAr2";
BA_ "Origin" SG_ 664 FPAS_ObjFRCornrAr2 "fuel,ev";
BA_ "GenSigCycleTime" SG_ 664 FPAS_FLCornrSnsrFailSts 100;
BA_ "Match" SG_ 664 FPAS_FLCornrSnsrFailSts "FPAS_FLCornrSnsrFailSts";
BA_ "Origin" SG_ 664 FPAS_FLCornrSnsrFailSts "fuel,ev";
BA_ "GenSigCycleTime" SG_ 664 FPAS_FLMiddlSnsrFailSts 100;
BA_ "Match" SG_ 664 FPAS_FLMiddlSnsrFailSts "FPAS_FLMiddlSnsrFailSts";
BA_ "Origin" SG_ 664 FPAS_FLMiddlSnsrFailSts "fuel,ev";
BA_ "GenSigCycleTime" SG_ 664 FPAS_FRMiddlSnsrFailSts 100;
BA_ "Match" SG_ 664 FPAS_FRMiddlSnsrFailSts "FPAS_FRMiddlSnsrFailSts";
BA_ "Origin" SG_ 664 FPAS_FRMiddlSnsrFailSts "fuel,ev";
BA_ "GenSigCycleTime" SG_ 664 FPAS_FRCornrSnsrFailSts 100;
BA_ "Match" SG_ 664 FPAS_FRCornrSnsrFailSts "FPAS_FRCornrSnsrFailSts";
BA_ "Origin" SG_ 664 FPAS_FRCornrSnsrFailSts "fuel,ev";
BA_ "GenSigCycleTime" SG_ 664 FPAS_WorkSts 100;
BA_ "Match" SG_ 664 FPAS_WorkSts "FPAS_WorkSts";
BA_ "Origin" SG_ 664 FPAS_WorkSts "fuel,ev";
BA_ "GenSigCycleTime" SG_ 664 FPAS_AutoModSts 100;
BA_ "Match" SG_ 664 FPAS_AutoModSts "FPAS_AutoModSts";
BA_ "Origin" SG_ 664 FPAS_AutoModSts "fuel,ev";
BA_ "GenSigCycleTime" SG_ 664 FPAS_SoundIndcn 100;
BA_ "Match" SG_ 664 FPAS_SoundIndcn "FPAS_SoundIndcn";
BA_ "Origin" SG_ 664 FPAS_SoundIndcn "fuel,ev";
BA_ "GenSigCycleTime" SG_ 664 FPAS_NearBrrdstn 100;
BA_ "GenSigStartValue" SG_ 664 FPAS_NearBrrdstn 127;
BA_ "Match" SG_ 664 FPAS_NearBrrdstn "FPAS_NearBrrdstn";
BA_ "Origin" SG_ 664 FPAS_NearBrrdstn "fuel,ev";
BA_ "GenSigCycleTime" SG_ 664 APA_MenuDispCtrlCmd 100;
BA_ "Match" SG_ 664 APA_MenuDispCtrlCmd "APA_MenuDispCtrlCmd";
BA_ "Origin" SG_ 664 APA_MenuDispCtrlCmd "fuel,ev";
BA_ "GenSigCycleTime" SG_ 664 APA_FuncSts 100;
BA_ "Match" SG_ 664 APA_FuncSts "APA_FuncSts";
BA_ "Origin" SG_ 664 APA_FuncSts "fuel,ev";
BA_ "GenSigCycleTime" SG_ 664 RADS_FuncSts 100;
BA_ "Match" SG_ 664 RADS_FuncSts "RADS_FuncSts";
BA_ "Origin" SG_ 664 RADS_FuncSts "fuel,ev";
BA_ "GenSigCycleTime" SG_ 664 FADS_FuncSts 100;
BA_ "Match" SG_ 664 FADS_FuncSts "FADS_FuncSts";
BA_ "Origin" SG_ 664 FADS_FuncSts "fuel,ev";
BA_ "GenSigCycleTime" SG_ 664 HAP_TextIconDispCtrl 100;
BA_ "Match" SG_ 664 HAP_TextIconDispCtrl "HAP_TextIconDispCtrl";
BA_ "Origin" SG_ 664 HAP_TextIconDispCtrl "fuel,ev";
BA_ "GenSigCycleTime" SG_ 649 HAP_RtCam_WorkSts 100;
BA_ "GenSigStartValue" SG_ 649 HAP_RtCam_WorkSts 1;
BA_ "Match" SG_ 649 HAP_RtCam_WorkSts "HAP_RtCam_WorkSts";
BA_ "Origin" SG_ 649 HAP_RtCam_WorkSts "fuel,ev";
BA_ "GenSigCycleTime" SG_ 649 HAP_RtSide_Obj1_ID 100;
BA_ "Match" SG_ 649 HAP_RtSide_Obj1_ID "HAP_RtSide_Obj1_ID";
BA_ "Origin" SG_ 649 HAP_RtSide_Obj1_ID "fuel,ev";
BA_ "GenSigCycleTime" SG_ 649 HAP_RtSide_Obj1_type 100;
BA_ "Match" SG_ 649 HAP_RtSide_Obj1_type "HAP_RtSide_Obj1_type";
BA_ "Origin" SG_ 649 HAP_RtSide_Obj1_type "fuel,ev";
BA_ "GenSigCycleTime" SG_ 649 HAP_RtSide_Obj1_Confidence 100;
BA_ "Match" SG_ 649 HAP_RtSide_Obj1_Confidence "HAP_RtSide_Obj1_Confidence";
BA_ "Origin" SG_ 649 HAP_RtSide_Obj1_Confidence "fuel,ev";
BA_ "GenSigCycleTime" SG_ 649 HAP_RtSide_Obj1_Ground_Pos_X 100;
BA_ "Match" SG_ 649 HAP_RtSide_Obj1_Ground_Pos_X "HAP_RtSide_Obj1_Ground_Pos_X";
BA_ "Origin" SG_ 649 HAP_RtSide_Obj1_Ground_Pos_X "fuel,ev";
BA_ "GenSigCycleTime" SG_ 649 HAP_RtSide_Obj1_Ground_Pos_Y 100;
BA_ "Match" SG_ 649 HAP_RtSide_Obj1_Ground_Pos_Y "HAP_RtSide_Obj1_Ground_Pos_Y";
BA_ "Origin" SG_ 649 HAP_RtSide_Obj1_Ground_Pos_Y "fuel,ev";
BA_ "GenSigCycleTime" SG_ 649 HAP_RtSide_Obj2_ID 100;
BA_ "Match" SG_ 649 HAP_RtSide_Obj2_ID "HAP_RtSide_Obj2_ID";
BA_ "Origin" SG_ 649 HAP_RtSide_Obj2_ID "fuel,ev";
BA_ "GenSigCycleTime" SG_ 649 HAP_RtSide_Obj2_type 100;
BA_ "Match" SG_ 649 HAP_RtSide_Obj2_type "HAP_RtSide_Obj2_type";
BA_ "Origin" SG_ 649 HAP_RtSide_Obj2_type "fuel,ev";
BA_ "GenSigCycleTime" SG_ 649 HAP_RtSide_Obj2_Confidence 100;
BA_ "Match" SG_ 649 HAP_RtSide_Obj2_Confidence "HAP_RtSide_Obj2_Confidence";
BA_ "Origin" SG_ 649 HAP_RtSide_Obj2_Confidence "fuel,ev";
BA_ "GenSigCycleTime" SG_ 649 HAP_RtSide_Obj2_Ground_Pos_X 100;
BA_ "Match" SG_ 649 HAP_RtSide_Obj2_Ground_Pos_X "HAP_RtSide_Obj2_Ground_Pos_X";
BA_ "Origin" SG_ 649 HAP_RtSide_Obj2_Ground_Pos_X "fuel,ev";
BA_ "GenSigCycleTime" SG_ 649 HAP_RtSide_Obj2_Ground_Pos_Y 100;
BA_ "Match" SG_ 649 HAP_RtSide_Obj2_Ground_Pos_Y "HAP_RtSide_Obj2_Ground_Pos_Y";
BA_ "Origin" SG_ 649 HAP_RtSide_Obj2_Ground_Pos_Y "fuel,ev";
BA_ "GenSigCycleTime" SG_ 649 HAP_RtSide_Obj3_ID 100;
BA_ "Match" SG_ 649 HAP_RtSide_Obj3_ID "HAP_RtSide_Obj3_ID";
BA_ "Origin" SG_ 649 HAP_RtSide_Obj3_ID "fuel,ev";
BA_ "GenSigCycleTime" SG_ 649 HAP_RtSide_Obj3_type 100;
BA_ "Match" SG_ 649 HAP_RtSide_Obj3_type "HAP_RtSide_Obj3_type";
BA_ "Origin" SG_ 649 HAP_RtSide_Obj3_type "fuel,ev";
BA_ "GenSigCycleTime" SG_ 649 HAP_RtSide_Obj3_Confidence 100;
BA_ "Match" SG_ 649 HAP_RtSide_Obj3_Confidence "HAP_RtSide_Obj3_Confidence";
BA_ "Origin" SG_ 649 HAP_RtSide_Obj3_Confidence "fuel,ev";
BA_ "GenSigCycleTime" SG_ 649 HAP_RtSide_Obj3_Ground_Pos_X 100;
BA_ "Match" SG_ 649 HAP_RtSide_Obj3_Ground_Pos_X "HAP_RtSide_Obj3_Ground_Pos_X";
BA_ "Origin" SG_ 649 HAP_RtSide_Obj3_Ground_Pos_X "fuel,ev";
BA_ "GenSigCycleTime" SG_ 649 HAP_RtSide_Obj3_Ground_Pos_Y 100;
BA_ "Match" SG_ 649 HAP_RtSide_Obj3_Ground_Pos_Y "HAP_RtSide_Obj3_Ground_Pos_Y";
BA_ "Origin" SG_ 649 HAP_RtSide_Obj3_Ground_Pos_Y "fuel,ev";
BA_ "GenSigCycleTime" SG_ 649 HAP_RtSide_Obj4_ID 100;
BA_ "Match" SG_ 649 HAP_RtSide_Obj4_ID "HAP_RtSide_Obj4_ID";
BA_ "Origin" SG_ 649 HAP_RtSide_Obj4_ID "fuel,ev";
BA_ "GenSigCycleTime" SG_ 649 HAP_RtSide_Obj4_type 100;
BA_ "Match" SG_ 649 HAP_RtSide_Obj4_type "HAP_RtSide_Obj4_type";
BA_ "Origin" SG_ 649 HAP_RtSide_Obj4_type "fuel,ev";
BA_ "GenSigCycleTime" SG_ 649 HAP_RtSide_Obj4_Confidence 100;
BA_ "Match" SG_ 649 HAP_RtSide_Obj4_Confidence "HAP_RtSide_Obj4_Confidence";
BA_ "Origin" SG_ 649 HAP_RtSide_Obj4_Confidence "fuel,ev";
BA_ "GenSigCycleTime" SG_ 649 HAP_RtSide_Obj4_Ground_Pos_X 100;
BA_ "Match" SG_ 649 HAP_RtSide_Obj4_Ground_Pos_X "HAP_RtSide_Obj4_Ground_Pos_X";
BA_ "Origin" SG_ 649 HAP_RtSide_Obj4_Ground_Pos_X "fuel,ev";
BA_ "GenSigCycleTime" SG_ 649 HAP_RtSide_Obj4_Ground_Pos_Y 100;
BA_ "Match" SG_ 649 HAP_RtSide_Obj4_Ground_Pos_Y "HAP_RtSide_Obj4_Ground_Pos_Y";
BA_ "Origin" SG_ 649 HAP_RtSide_Obj4_Ground_Pos_Y "fuel,ev";
BA_ "GenSigCycleTime" SG_ 649 USS_FLSide1_Status 100;
BA_ "GenSigStartValue" SG_ 649 USS_FLSide1_Status 1;
BA_ "Match" SG_ 649 USS_FLSide1_Status "USS_FLSide1_Status";
BA_ "Origin" SG_ 649 USS_FLSide1_Status "fuel,ev";
BA_ "GenSigCycleTime" SG_ 649 USS_FLSide1_Dist 100;
BA_ "Match" SG_ 649 USS_FLSide1_Dist "USS_FLSide1_Dist";
BA_ "Origin" SG_ 649 USS_FLSide1_Dist "fuel,ev";
BA_ "GenSigCycleTime" SG_ 649 USS_RLSide2_Status 100;
BA_ "GenSigStartValue" SG_ 649 USS_RLSide2_Status 1;
BA_ "Match" SG_ 649 USS_RLSide2_Status "USS_RLSide2_Status";
BA_ "Origin" SG_ 649 USS_RLSide2_Status "fuel,ev";
BA_ "GenSigCycleTime" SG_ 649 USS_RLSide2_Dist 100;
BA_ "Match" SG_ 649 USS_RLSide2_Dist "USS_RLSide2_Dist";
BA_ "Origin" SG_ 649 USS_RLSide2_Dist "fuel,ev";
BA_ "GenSigCycleTime" SG_ 649 USS_FRSide1_Status 100;
BA_ "GenSigStartValue" SG_ 649 USS_FRSide1_Status 1;
BA_ "Match" SG_ 649 USS_FRSide1_Status "USS_FRSide1_Status";
BA_ "Origin" SG_ 649 USS_FRSide1_Status "fuel,ev";
BA_ "GenSigCycleTime" SG_ 649 USS_FRSide1_Dist 100;
BA_ "Match" SG_ 649 USS_FRSide1_Dist "USS_FRSide1_Dist";
BA_ "Origin" SG_ 649 USS_FRSide1_Dist "fuel,ev";
BA_ "GenSigCycleTime" SG_ 649 USS_RRSide2_Status 100;
BA_ "GenSigStartValue" SG_ 649 USS_RRSide2_Status 1;
BA_ "Match" SG_ 649 USS_RRSide2_Status "USS_RRSide2_Status";
BA_ "Origin" SG_ 649 USS_RRSide2_Status "fuel,ev";
BA_ "GenSigCycleTime" SG_ 649 USS_RRSide2_Dist 100;
BA_ "Match" SG_ 649 USS_RRSide2_Dist "USS_RRSide2_Dist";
BA_ "Origin" SG_ 649 USS_RRSide2_Dist "fuel,ev";
BA_ "GenSigCycleTime" SG_ 667 HAVP_LrngDst 100;
BA_ "GenSigStartValue" SG_ 667 HAVP_LrngDst 255;
BA_ "Match" SG_ 667 HAVP_LrngDst "HAVP_LrngDst";
BA_ "Origin" SG_ 667 HAVP_LrngDst "fuel,ev";
BA_ "GenSigCycleTime" SG_ 667 HAVP_HUT_TextDisp 100;
BA_ "Match" SG_ 667 HAVP_HUT_TextDisp "HAVP_HUT_TextDisp";
BA_ "Origin" SG_ 667 HAVP_HUT_TextDisp "fuel,ev";
BA_ "GenSigCycleTime" SG_ 962 HCU_RecupPwr 1000;
BA_ "Match" SG_ 962 HCU_RecupPwr "HCU_RecupPwr";
BA_ "Origin" SG_ 962 HCU_RecupPwr "fuel,ev";
BA_ "GenSigCycleTime" SG_ 962 HCU_EVContnsDistance 1000;
BA_ "Match" SG_ 962 HCU_EVContnsDistance "HCU_EVContnsDistance";
BA_ "Origin" SG_ 962 HCU_EVContnsDistance "ev";
BA_ "GenSigCycleTime" SG_ 962 HCU_EVContnsDistanceVld 1000;
BA_ "Match" SG_ 962 HCU_EVContnsDistanceVld "HCU_EVContnsDistanceVld";
BA_ "Origin" SG_ 962 HCU_EVContnsDistanceVld "ev";
BA_ "GenSigCycleTime" SG_ 962 HCU_EgyUsed 1000;
BA_ "Match" SG_ 962 HCU_EgyUsed "HCU_EgyUsed";
BA_ "Origin" SG_ 962 HCU_EgyUsed "ev";
VAL_ 653 SecRowLeSeatVentSts 0 "OFF" 1 "Level 1_low" 2 "Level 2_middle" 3 "Level 3_high";
VAL_ 653 SecRowRiSeatVentSts 0 "OFF" 1 "Level 1_low" 2 "Level 2_middle" 3 "Level 3_high";
VAL_ 671 RemoteModSts 0 "Normal mode" 1 "Remote mode";
VAL_ 671 PASWorkCmd 0 "OFF" 1 "ON";
VAL_ 671 KL30BRelaySts 0 "Off" 1 "On";
VAL_ 671 RViewMirrorSts 0 "Unfold" 1 "Fold";
VAL_ 671 WiprReq_F_PBox 0 "Wiper Off" 1 "Wiper action once" 2 "Speed1 (Lo)" 3 "Speed2 (Hi)" 4 "Reserved" 6 "Reserved" 7 "Invalid";
VAL_ 671 DrivingModReq 0 "Standard" 1 "reserved" 2 "Reserved" 3 "Economic" 4 "Sport" 5 "Reserved" 6 "Reserved" 7 "Reserved" 8 "Reserved" 9 "AUTO" 10 "Reserved" 11 "Mud" 12 "_Snow_TOD" 13 "Sand" 14 "_Rock" 15 "4H";
VAL_ 845 ColMemPosnSetSwtFB 0 "No action" 1 "Set memory button 1 successfully" 2 "Set memory button 1 unsuccessfully" 3 "Set memory button 2 successfully" 4 "Set memory button 2 unsuccessfully" 5 "Set memory button 3 successfully" 6 "Set memory button 3 unsuccessfully" 7 "Reserved";
VAL_ 241 BMS_ErrCategory 0 "No Error" 1 "Warning" 2 "Derating" 3 "Reserved" 4 "Reserved" 5 "Error" 6 "Reserved" 7 "Emergency Open";
VAL_ 241 CheckSum_BMS4 0 "Valid value" 255 "Valid value";
VAL_ 241 BMS_PackCurr 0 "Valid value" 10000 "Valid value" 10001 "Reserved" 16382 "Reserved" 16383 "Invalid";
VAL_ 241 BMS_PackVolt 0 "Valid value" 245 "Valid value" 246 "Reserved" 254 "Reserved" 255 "Invalid";
VAL_ 241 BMS_PowerDownCmplt 0 "Not complete" 1 "Complete";
VAL_ 241 BMS_BattPoweErr 0 "No Error" 1 "TM power unavailable" 2 "P2M power unavailable" 3 "OBC power unavailable";
VAL_ 241 RollingCounter_BMS4 0 "Valid value" 14 "Valid value" 15 "Invalid value";
VAL_ 862 RoofModFb 0 "OFF" 1 "ON";
VAL_ 862 AllTerrainDislFb 0 "OFF" 1 "ON";
VAL_ 862 ElecSideStepSysFb 0 "OFF" 1 "ON";
VAL_ 350 CR_FCTA_Resp 0 "OFF" 1 "ON";
VAL_ 350 CR_FCTB_Resp 0 "OFF" 1 "ON";
VAL_ 350 CR_BliSts 0 "No Blindness" 1 "Blindness";
VAL_ 350 FCTA_Warn 0 "No warning" 1 "Warning";
VAL_ 350 FCTBTrig 0 "Not tirggered" 1 "tirggered";
VAL_ 350 FCTA_B_FuncSts 0 "No display" 1 "error" 2 "FCTA_B temporarily unavailable" 3 "FCTA_B Performance degradation";
VAL_ 350 FCTA_B_TTC 0 "No Display" 1 "valid value" 63 "valid value";
VAL_ 357 LTurnLmpSwtSts 0 "OFF" 1 "ON";
VAL_ 357 RTurnLmpSwtSts 0 "OFF" 1 "ON";
VAL_ 357 AutoLmpSwtSts 0 "Non-Auto" 1 "Auto";
VAL_ 357 HornSwtSts 0 "OFF" 1 "ON";
VAL_ 357 FrntWiprSwtSts 0 "Wiper Off" 1 "Wiper Auto Or Intermittent" 2 "Low Speed" 3 "High Speed" 4 "reserved" 6 "reserved" 7 "Error";
VAL_ 161 SteerWheelAng 0 "Valid value" 7800 "Valid value" 7801 "Reserved" 32766 "Reserved" 32767 "Invalid";
VAL_ 161 SteerWheelAngSign 0 "Left (Positive)" 1 "Right (Negative)";
VAL_ 161 SAS_Sts 0 "SAS Angle And Speed Correct" 1 "SAS Not Calibrated" 2 "Intermittent Error Detected" 3 "Permanent Error Detected";
VAL_ 580 MenuReturnSwtSts 0 "Released" 1 "Pressed" 2 "error" 3 "invalidation";
VAL_ 580 SteerWheelHeatdSts 0 "Not active" 1 "Active";
VAL_ 580 HomeSwtSts 0 "Released" 1 "Pressed" 2 "error" 3 "invalidation";
VAL_ 580 MuteSwtSts 0 "Released" 1 "Pressed" 2 "Error" 3 "invalidation";
VAL_ 580 CustomSwtSts 0 "Released" 1 "Pressed" 2 "error" 3 "invalidation";
VAL_ 580 PageUpSwtSts 0 "Released" 1 "Pressed" 2 "error" 3 "invalid";
VAL_ 580 PageDwnSwtSts 0 "Released" 1 "Pressed" 2 "error" 3 "invalidation";
VAL_ 580 PageLSwtSts 0 "Released" 1 "Pressed" 2 "error" 3 "invalidation";
VAL_ 580 PageRSwtSts 0 "Released" 1 "Pressed" 2 "error" 3 "invalidation";
VAL_ 580 SeekUpSwtSts 0 "Released" 1 "Pressed" 2 "error" 3 "invalidation";
VAL_ 580 SeekDwnSwtSts 0 "Released" 1 "Pressed" 2 "error" 3 "invalidation";
VAL_ 580 AdjVolUpSwtSts 0 "Released" 1 "Pressed" 2 "error" 3 "invalidation";
VAL_ 580 AdjVolDwnSwtSts 0 "Released" 1 "Pressed" 2 "error" 3 "invalidation";
VAL_ 580 VRSwtSts 0 "Released" 1 "Pressed" 2 "error" 3 "invalidation";
VAL_ 580 EnterSwtSts 0 "Released" 1 "Pressed" 2 "error" 3 "invalidation";
VAL_ 580 EnterSwtSts_Mmed 0 "Released" 1 "Pressed" 2 "error" 3 "invalidation";
VAL_ 580 CustomSwtSts_Mmed 0 "Released" 1 "Pressed" 2 "error" 3 "invalidation";
VAL_ 580 IpMenuSwtSts 0 "Released" 1 "Pressed" 2 "Error" 3 "Invalidation";
VAL_ 566 CheckSum_DCT7 0 "Valid values" 255 "Valid values";
VAL_ 566 TrsmStNID 0 "Inactive" 1 "Break down powerflow" 2 "CSN or NUN active" 3 "Geneate power flow" 4 "Reserve" 7 "Reserve";
VAL_ 566 DCT_RaceModeSts 0 "Inactive" 1 "Active" 2 "Turn Off" 3 "Forbidden" 4 "Reserved (treat as 0x0 inactive)" 7 "Reserved (treat as 0x0 inactive)";
VAL_ 566 TRANS_OIL_TEMP 0 "Valid values" 254 "Valid values" 255 "Invalid";
VAL_ 566 DCT_PrsBrk_Warn 0 "No warning" 1 "Press brake and Unlock-button to shift" 2 "Press Unlock-button to shift" 3 "Press brake to shift";
VAL_ 566 DCT_ShftNotAlwd_Warn 0 "No warning" 1 "Vehicle speed too high, shift not allowed" 2 "Engage P not allowed due to high vehicle speed" 3 "Transmission is in N, park-lock is not locked";
VAL_ 566 DCT_ShftRecom_M 0 "No Recommendation" 1 "Up Shift" 2 "Down Shift" 3 "Reserved";
VAL_ 566 DrvWarnMsg 0 "No Text" 1 "PressBrake" 2 "TransToo_Hot" 3 "N Lock and unable to shift" 4 "Reserved" 7 "Reserved";
VAL_ 566 DrvFaiMsg 0 "No Message" 1 "Transmission Malfunction" 2 "Transmission P engagement fault" 3 "Transmission P disengagement fault" 4 "Atuthentication failure(reserved)" 5 "E-shift faulty" 6 "Reserved" 14 "Reserved" 15 "transmission limit function";
VAL_ 566 DrvModDisp 0 "P" 1 "R" 2 "N" 3 "D" 4 "M" 5 "Reserved" 7 "Reserved";
VAL_ 566 DrvModDispSts 0 "BlankNo Display" 1 "On" 2 "Flashing" 3 "Reserved(treat as BlankNo Display)";
VAL_ 566 DrvAutoGearDisp 0 "Neutral" 1 "1st Gear" 2 "2nd Gear" 3 "3rd Gear" 4 "4th Gear" 5 "5th Gear" 6 "6th Gear" 7 "7th Gear" 8 "8th Gear" 9 "9th Gear" 10 "Reserved" 15 "Reserved";
VAL_ 566 DrvGearDispSts 0 "Blank  No display" 1 "On" 2 "Flashing" 3 "Reserved (treat as BlankNo display)";
VAL_ 566 RollingCounter_DCT7 0 "Valid value" 14 "Valid value" 15 "Invalid value";
VAL_ 166 TgtEngSpdIP 0 "Valid values" 4095 "Valid values";
VAL_ 166 TgtEngSpdIPValid 0 "Invalid" 1 "valid";
VAL_ 545 CurrentGearValid 0 "Invalid" 1 "Valid";
VAL_ 545 CURRENT_GEAR 0 "Current gear 'N' or 'P'" 1 "Current gear '1'" 2 "Current gear '2'" 3 "Current gear '3'" 4 "Current gear '4'" 5 "Current gear '5'" 6 "Current gear '6'" 7 "Current gear '7'" 8 "Current gear 'R'" 9 "Current gear '8'" 10 "Reserved" 15 "Reserved";
VAL_ 545 TGS_LEVER 0 "Select lever in position 'P'" 1 "Reserved" 2 "Reserved" 3 "Reserved" 4 "Reserved" 5 "Select lever in position 'D'" 6 "Select lever in position 'N'" 7 "Select lever in position 'R'" 8 "Select lever in position 'M'" 9 "Reserved" 13 "Reserved" 14 "Intermediate position" 15 "Invalid";
VAL_ 545 TRANS_Warning_LAMP 0 "The Warning(Mil) light is off" 1 "The Warning(Mil) light is on";
VAL_ 714 DrvWinPosnSts_Perc 0 "Unknown" 1 "Close" 2 "Open" 3 "5%Open" 4 "10%Open" 5 "15%Open" 6 "20%Open" 7 "25%Open" 8 "30%Open" 9 "35%Open" 10 "40%Open" 11 "45%Open" 12 "50%Open" 13 "55%Open" 14 "60%Open" 15 "65%Open" 16 "70%Open" 17 "75%Open" 18 "80%Open" 19 "85%Open" 20 "90%Open" 21 "95%Open" 22 "Reserved" 31 "Reserved";
VAL_ 714 DrvWinLrnSts 0 "Unlearn" 1 "Learn";
VAL_ 714 DrvWinHotProtSts 0 "NO" 1 "Hot prtect";
VAL_ 714 DrvSideRearWinLrnSts 0 "Unlearn" 1 "Learn";
VAL_ 714 DrvSideRearWinHotProtSts 0 "NO" 1 "Hot prtect";
VAL_ 759 DrvSideRearWinPosnSts_Perc 0 "Unknown" 1 "Close" 2 "Open" 3 "5%Open" 4 "10%Open" 5 "15%Open" 6 "20%Open" 7 "25%Open" 8 "30%Open" 9 "35%Open" 10 "40%Open" 11 "45%Open" 12 "50%Open" 13 "55%Open" 14 "60%Open" 15 "65%Open" 16 "70%Open" 17 "75%Open" 18 "80%Open" 19 "85%Open" 20 "90%Open" 21 "95%Open" 22 "Reserved" 31 "Reserved";
VAL_ 589 DrowsnsLvl 0 "No Drowsiness" 1 "Low level Drowsiness" 2 "Middle level Drowsiness" 3 "High level Drowsiness" 4 "Reserved" 6 "Reserved" 7 "Invalid";
VAL_ 589 DrowsnsLvlQlty 0 "Valid value" 100 "Valid value" 101 "Reserved" 126 "Reserved" 127 "Invalid";
VAL_ 589 GenderSts 0 "Male" 1 "Female" 2 "Reserved" 3 "Invalid";
VAL_ 589 GenderStsQlty 0 "Valid value" 100 "Valid value" 101 "Reserved" 126 "Reserved" 127 "Invalid";
VAL_ 589 ExprsnSts 0 "No expression" 1 "Smile" 2 "Angry" 3 "Surprise" 4 "Sad" 5 "Calm" 6 "Reserved" 7 "Invalid";
VAL_ 589 Checksum_DMS2 0 "Valid values" 255 "Valid values";
VAL_ 589 DistrctnLvl_ACC 0 "No distraction" 1 "Low level distraction" 2 "Middle level distraction" 3 "Hi level distraction" 4 "Reserved" 6 "Reserved" 7 "Invalid";
VAL_ 589 DistrctnLvlQlty_ACC 0 "Valid value" 100 "Valid value" 101 "Reserved" 126 "Reserved" 127 "Invalid";
VAL_ 589 DrowsnsLvl_ACC 0 "No Drowsiness" 1 "Low level Drowsiness" 2 "Middle level Drowsiness" 3 "Hi level Drowsiness" 4 "Reserved" 6 "Reserved" 7 "Invalid";
VAL_ 589 DrowsnsLvlQlty_ACC 0 "Valid value" 100 "Valid value" 101 "Reserved" 126 "Reserved" 127 "Invalid";
VAL_ 589 RollingCounter_DMS2 0 "Valid value" 14 "Valid value" 15 "Invalid value";
VAL_ 589 Checksum_DMS3 0 "Valid values" 255 "Valid values";
VAL_ 589 HeadPosnX 0 "Valid value" 1500 "Valid value" 1501 "Reserved" 2046 "Reserved" 2047 "Invalid";
VAL_ 589 HeadPosnY 0 "Valid value" 1000 "Valid value" 1001 "Reserved" 2046 "Reserved" 2047 "Invalid";
VAL_ 589 HeadPosnZ 0 "Valid value" 1000 "Valid value" 1001 "Reserved" 2046 "Reserved" 2047 "Invalid";
VAL_ 589 HeadPosQlty 0 "Valid value" 100 "Valid value" 101 "Reserved" 126 "Reserved" 127 "Invalid";
VAL_ 589 RollingCounter_DMS3 0 "Valid value" 14 "Valid value" 15 "Invalid value";
VAL_ 589 GazePosnX 0 "Valid value" 1500 "Valid value" 1501 "Reserved" 2046 "Reserved" 2047 "Invalid";
VAL_ 589 GazePosnY 0 "Valid value" 1000 "Valid value" 1001 "Reserved" 2046 "Reserved" 2047 "Invalid";
VAL_ 589 GazePosnZ 0 "Valid value" 1000 "Valid value" 1001 "Reserved" 2046 "Reserved" 2047 "Invalid";
VAL_ 589 Checksum_DMS5 0 "Valid values" 255 "Valid values";
VAL_ 589 DMSSts 0 "Blindness" 1 "Error" 2 "Active" 3 "Not active" 4 "Reserved" 6 "Reserved" 7 "Invalid";
VAL_ 589 HeadDetn 0 "No" 1 "Yes";
VAL_ 589 HeadYawAng 0 "Valid value" 150 "Valid value" 151 "Reserved" 254 "Reserved" 255 "Invalid";
VAL_ 589 HeadPitchAng 0 "Valid value" 70 "Valid value" 71 "Reserved" 254 "Reserved" 255 "Invalid";
VAL_ 589 HeadRollAng 0 "Valid value" 90 "Valid value" 91 "Reserved" 254 "Reserved" 255 "Invalid";
VAL_ 589 HeadRotAngQlty 0 "Valid value" 100 "Valid value" 101 "Reserved" 126 "Reserved" 127 "Invalid";
VAL_ 589 RollingCounter_DMS5 0 "Valid value" 14 "Valid value" 15 "Invalid value";
VAL_ 589 Checksum_DMS6 0 "Valid values" 255 "Valid values";
VAL_ 589 LEyeOpenSts 0 "No" 1 "Yes" 2 "Loss left eye" 3 "Invalid";
VAL_ 589 LEyeOpenStsQlty 0 "Valid value" 100 "Valid value" 101 "Reserved" 126 "Reserved" 127 "Invalid";
VAL_ 589 REyeOpenSts 0 "No" 1 "Yes" 2 "Loss right eye" 3 "Invalid";
VAL_ 589 REyeOpenStsQlty 0 "Valid value" 100 "Valid value" 101 "Reserved" 126 "Reserved" 127 "Invalid";
VAL_ 589 RobustGazeYawAng 0 "Valid value" 180 "Valid value" 181 "Reserved" 254 "Reserved" 255 "Invalid";
VAL_ 589 RobustGazePitchAng 0 "Valid value" 180 "Valid value" 181 "Reserved" 254 "Reserved" 255 "Invalid";
VAL_ 589 RobustGazeAngQlty 0 "Valid value" 100 "Valid value" 101 "Reserved" 126 "Reserved" 127 "Invalid";
VAL_ 589 DrvBehvSts 0 "No action" 1 "Smoking" 2 "on the phone" 3 "Drinking" 4 "Reserved" 6 "Reserved" 7 "Invalid";
VAL_ 589 RollingCounter_DMS6 0 "Valid value" 14 "Valid value" 15 "Invalid value";
VAL_ 705 ChairMemPosnSetSwtFB 0 "noÃ‚Â action" 1 "setÃ‚Â memoryÃ‚Â buttonÃ‚Â 1Ã‚Â successfully" 2 "setÃ‚Â memoryÃ‚Â buttonÃ‚Â 1Ã‚Â unsuccessfully" 3 "setÃ‚Â memoryÃ‚Â buttonÃ‚Â 2Ã‚Â successfully" 4 "setÃ‚Â memoryÃ‚Â buttonÃ‚Â 2Ã‚Â unsuccessfully" 5 "setÃ‚Â memoryÃ‚Â buttonÃ‚Â 3Ã‚Â successfully" 6 "setÃ‚Â memoryÃ‚Â buttonÃ‚Â 3Ã‚Â unsuccessfully" 7 "reserved";
VAL_ 748 DVR_360VideoCaptureReq 0 "Off" 1 "On";
VAL_ 748 DVRRemtCnSts 0 "Default" 1 "Connect success" 2 "Network anomaly" 3 "Register fail" 4 "Authenticate fail" 5 "Connection timeout" 6 "Connection disconnected" 7 "Reserved";
VAL_ 748 DVRSts 0 "DVR_Normal Operation" 1 "DVR_Error Operation" 2 "TF1 is not inset" 3 "TF1 is fault" 4 "TF1 is full" 5 "TF1 is writing slow" 6 "TF2 is not inset" 7 "TF2 is fault" 8 "TF2 is full" 9 "TF2 is writing slow" 10 "Reserved" 15 "Reserved";
VAL_ 656 EngOilLvl 0 "No display" 1 "Waiting for measruement" 2 "Below min" 3 "Min" 4 "14 Max" 5 "12 Max" 6 "34Max" 7 "Max" 8 "Overfill" 9 "Failed because low temperature" 10 "Failed because Large slope" 11 "Failed because vehicle condition changed" 12 "Failed because loss of communication" 13 "Failed because vehicle is running" 14 "Reserved" 15 "Reserved";
VAL_ 656 FTIVFault 0 "No warning" 1 "Warning";
VAL_ 656 FuelTankCapWarning 0 "No warning" 1 "Warning(Fuel tank cap did not close)" 2 "Reserved" 3 "Fault(Fuel tank cap did not open)";
VAL_ 656 PressReliProgs 0 "Valid values" 99 "Valid values" 100 "Finish" 101 "reserved" 127 "reserved";
VAL_ 273 EMS_AuthenResult 0 "Nothing" 1 "Authentication failure" 2 "Authentication success" 3 "Reserved";
VAL_ 273 EngSpd 0 "Valid values" 65535 "Valid values";
VAL_ 273 EngSpdVldty 0 "Invalid" 1 "Valid" 2 "Initial value" 3 "Reserved";
VAL_ 273 EngSpd_PHEV 0 "Valid values" 65535 "Valid values";
VAL_ 273 EngSpdVldty_PHEV 0 "Invalid" 1 "Valid" 2 "Initial value" 3 "Reserved";
VAL_ 723 EngSpd_ForIP 0 "Valid values" 65535 "Valid values";
VAL_ 723 EWP_Err 0 "No error" 1 "Error";
VAL_ 625 FuelConsumption 0 "Valid values" 65535 "Valid values";
VAL_ 625 TgtCrsVehSpd 0 "Valid values" 255 "Valid values";
VAL_ 625 CruiseCtrlSts 0 "Inactive" 1 "Active" 2 "Standby" 3 "error";
VAL_ 625 AccelPedalPosn 0 "Valid values" 255 "Valid values";
VAL_ 625 AccelPedalPosnVldty 0 "Invalid" 1 "Valid" 2 "Init value" 3 "Reserved";
VAL_ 625 ThrtlPosRatio 0 "Valid values" 254 "Valid values" 255 "Invalid";
VAL_ 625 EngSVSSig 0 "SVS off" 1 "SVS on";
VAL_ 625 MILSts 0 "Off" 1 "On";
VAL_ 625 EngState 0 "Stopped" 1 "Cranking" 2 "Running" 3 "Stalling";
VAL_ 951 ECM_VehDstBackup 0 "0-9999999-km" 9999999 "0-9999999-km" 10000000 "Reserved" 16777214 "Reserved" 16777215 "Invalid";
VAL_ 881 BaroPressure 0 "Valid values" 254 "Valid values" 255 "Invalid value";
VAL_ 881 EngCoolantTemp 0 "Valid values" 255 "Valid values";
VAL_ 881 GPF_Warning 0 "No Warning" 1 "GPF is regenerating" 2 "GPF need to regenerate" 3 "Reserved";
VAL_ 881 GentrWarnLmpSts 0 "Off" 1 "On";
VAL_ 881 EngClntTempWarn 0 "No" 1 "Yes";
VAL_ 881 EngClntTempVldty 0 "Invalid" 1 "Valid" 2 "Init value" 3 "Reserved";
VAL_ 881 SS_Screen_tip 0 "no screen tip" 1 "screen tip";
VAL_ 881 SSSSetSts 0 "Off" 1 "On";
VAL_ 881 SS_Enable_Lamp 0 "Lamp off" 1 "Lamp on";
VAL_ 881 SS_Fault_Lamp 0 "Lamp off" 1 "Lamp on";
VAL_ 881 MaxEngTrqNorm 0 "Valid values" 130 "Valid values" 131 "Rserved" 255 "Rserved";
VAL_ 881 AGS_Failure 0 "No Failure" 1 "Failure";
VAL_ 680 TranPMode_Sts 0 "Normal Mode" 1 "Transport Mode";
VAL_ 680 Stat_PwrSv_Lvl 0 "Normal" 1 "Level 1" 2 "Level 2" 3 "Reserved" 7 "Reserved";
VAL_ 680 Dyn_PwrSv_Lvl 0 "Normal" 1 "Level 1" 2 "Level 2" 3 "Level 3" 4 "Level 4" 5 "Level 5" 6 "Reserved" 7 "Reserved";
VAL_ 680 LvPwrSysErr 0 "No error" 1 "error" 2 "Reservrd" 3 "Reservrd";
VAL_ 338 FrntELDLckSts 0 "UnLocked" 1 "Locked" 2 "Over-Speed Warning" 3 "Reserved" 4 "Lock Request Deny" 5 "Reserved" 13 "Reserved" 14 "Fault" 15 "Invalid";
VAL_ 338 RearELDLckSts 0 "UnLocked" 1 "Locked" 2 "Over-Speed Warning" 3 "Driving Mode Select Error" 4 "Lock Request Deny" 5 "Reserved" 13 "Reserved" 14 "Fault" 15 "Invalid";
VAL_ 363 CheckSum_EPB1 0 "Valid values" 255 "Valid values";
VAL_ 363 EPBErrSts 0 "Undefined" 1 "No Error" 2 "Error" 3 "Diagnosis";
VAL_ 363 EPBRedLmpSts 0 "Lamp off" 1 "Lamp on" 2 "Lamp flash" 3 "Reserved";
VAL_ 363 EPBSts 0 "Released" 1 "Closed" 2 "In progress" 3 "unknown";
VAL_ 363 EPBTextDisp 0 "No_Display" 1 "Gradient_Too_High" 2 "Park_Brake_Force_Not_Enough" 3 "Park_Brake_System_Overheated" 4 "Remind_Driver_To_Apply_Safety_Belt" 5 "Park_Brake_Maintenance_Mode" 6 "Roller_Bench_Mode" 7 "Please_Release_EPB" 8 "Please_Release_Rear_ELD" 9 "Switch_To_Non_P_and_Release_The_Parking" 10 "Please_Quit_TAB" 11 "Reserved" 15 "Reserved";
VAL_ 363 PressBrakePedalPointOut 0 "No reminder" 1 "Pedal needs to be applied";
VAL_ 363 RollingCounter_EPB1 0 "Valid value" 14 "Valid value" 15 "Invalid value";
VAL_ 327 CheckSum_EPS1 0 "Valid values" 255 "Valid values";
VAL_ 327 EPS_FailSts 0 "No fault" 1 "Permanent Error Detected" 2 "Intermittent Error Detected" 3 "Reserved";
VAL_ 327 EPS_SteerMod 0 "Comfort Mode" 1 "sport mode" 2 "Handiness Mode" 3 "Reserved" 7 "Reserved";
VAL_ 327 SteerCorrnRmn 0 "No Tip" 1 "Tip return finish" 2 "Tip return R" 3 "Tip return L";
VAL_ 327 SteerCorrnResp 0 "OFF" 1 "ON";
VAL_ 327 RollingCounter_EPS1 0 "Valid value" 14 "Valid value" 15 "Invalid value";
VAL_ 771 RotSteerWheel 0 "Off" 1 "Warning";
VAL_ 311 CheckSum_ESP2 0 "Valid values" 255 "Valid values";
VAL_ 311 HDCFault 0 "No failure" 1 "Failure when HDC is on need" 2 "Failure when is not on need" 3 "Reserved";
VAL_ 311 HDCCtrl 0 "OFF" 1 "On active braking" 2 "On not active braking" 3 "Reserved";
VAL_ 311 AVHErrSts 0 "No failure" 1 "Failure when AVH is on need" 2 "Failure when is not on need" 3 "Reserved";
VAL_ 311 AVHSts 0 "Off" 1 "Standby" 2 "active" 3 "Reserved";
VAL_ 311 CDPActv 0 "Not active" 1 "Active";
VAL_ 311 DrivingModDis 0 "Standard" 1 "Sport" 2 "Snow" 3 "Mud" 4 "Sand" 5 "4L" 6 "Economic" 7 "Mode_Unkown" 8 "AUTO" 9 "Sport+" 10 "Off_road" 11 "Stand_2H" 12 "Expert" 13 "Stand_4H" 14 "Failed" 15 "Invalid_Value" 16 "Snow_4H" 17 "Normal_4L" 18 "Rock_4L" 19 "Pothle_4L" 20 "MudSand_4L" 21 "Mountain_4L" 22 "reserved" 23 "Race" 24 "Reserved" 25 "Reserved" 26 "Wade_4H" 27 "Wade_4L" 28 "Reserved" 29 "4H" 31 "Reserved";
VAL_ 311 DrivingModReq_ESP 0 "No_Terrain_Control" 1 "Standard" 2 "Sport" 3 "Snow_Nex" 4 "Expert" 5 "Deep_Mud" 6 "Reserved" 7 "Soft_sand" 8 "4H" 9 "4L" 10 "Economic" 11 "Reserved" 12 "Snow_TOD" 13 "Off_road" 14 "Sport+" 15 "Invalid_Value" 16 "Standard_2H" 17 "Reserved" 18 "Standard_4H" 19 "Snow_4H" 20 "Normal_4L" 21 "Rock_4L" 22 "Pothole_4L" 23 "MudSand_4L" 24 "Mountain_4L" 25 "Reserved" 26 "Race" 27 "Reserved" 28 "Reserved" 29 "Wade_4H" 30 "Wade_4L" 31 "Reserved";
VAL_ 311 Shift_N_Warn 0 "Shift_N" 1 "No_shift_N";
VAL_ 311 Over_Spd_Warn 0 "No_warn" 1 "Warn";
VAL_ 311 FourL_Warn 0 "No_warn" 1 "Warn";
VAL_ 311 TAB_Sts 0 "Function OFF" 1 "Standby" 2 "Active" 3 "Failure";
VAL_ 311 RollingCounter_ESP2 0 "Valid value" 14 "Valid value" 15 "Invalid value";
VAL_ 311 CheckSum_ESP1 0 "Valid values" 255 "Valid values";
VAL_ 311 ESPFuncOffSts 0 "AvailableOn" 1 "UnavailableOff";
VAL_ 311 ESPActvInfoLmp 0 "Not active" 1 "Active";
VAL_ 311 ESPFailSts 0 "No failure" 1 "Failure";
VAL_ 311 IMC_Actv 0 "Not active" 1 "Active";
VAL_ 311 RollingCounter_ESP1 0 "Valid value" 14 "Valid value" 15 "Invalid value";
VAL_ 311 CheckSum_ABS3 0 "Valid values" 255 "Valid values";
VAL_ 311 ABSActv 0 "Not active" 1 "Active";
VAL_ 311 ABSFailSts 0 "No failure" 1 "Failure";
VAL_ 311 EBDFailSts 0 "No failure" 1 "Failure";
VAL_ 311 VehSpdVld 0 "Invalid" 1 "Valid";
VAL_ 311 VehSpd 0 "Valid values" 5333 "Valid values" 5334 "Reserved" 8191 "Reserved";
VAL_ 311 VehOdoInfoSts 0 "Invalid" 1 "Valid";
VAL_ 311 VehOdoInfo 0 "Valid values" 999 "Valid values" 1000 "Reserved" 1023 "Reserved";
VAL_ 311 RollingCounter_ABS3 0 "Valid value" 14 "Valid value" 15 "Invalid value";
VAL_ 200 ESP_HMI_WarningOn 0 "No warning lamp" 1 "Yellow Lamp" 2 "Red Lamp" 3 "reserved";
VAL_ 200 WadeModeWarn 0 "No_Warn" 1 "Please_slow_down" 2 "Please_pay_attention_to_the_surrounding_conditions_ignition_caution" 3 "Please_press_on_the_brake_gently_to_test_the_brake_performance";
VAL_ 368 CCO_Warn 0 "No Warn" 1 "Please Release EPB" 2 "Please  slow down" 3 "Reserved";
VAL_ 368 CCO_Active 0 "Not Active" 1 "Active" 2 "Stand by" 3 "Failed";
VAL_ 368 CCO_TgtVel 0 "Valid values" 31 "Valid values";
VAL_ 368 EspFuncOffSts_mode 0 "AvailableOn" 1 "Cross-country expert mode";
VAL_ 411 FFogLmpSts_F_PBox 0 "Off" 1 "On";
VAL_ 411 HiBeamSts_F_PBox 0 "Off" 1 "On";
VAL_ 411 HoodSts_F_PBox 0 "Closed" 1 "Open";
VAL_ 411 LasHdLmpSts_F_PBox 0 "Off" 1 "On";
VAL_ 411 LHiBeamFailSts 0 "No failure" 1 "failure";
VAL_ 411 RHiBeamFailSts 0 "No failure" 1 "failure";
VAL_ 411 LLowBeamFailSts 0 "No failure" 1 "failure";
VAL_ 411 LHeadLmpFailSts 0 "No failure" 1 "failure";
VAL_ 411 RHeadLmpFailSts 0 "No failure" 1 "failure";
VAL_ 411 RLowBeamFailSts 0 "No failure" 1 "failure";
VAL_ 411 RLasHdLmpDiagSig 0 "No failure" 1 "failure";
VAL_ 411 LLasHdLmpDiagSig 0 "No failure" 1 "failure";
VAL_ 411 LowBeamSts_F_PBox 0 "Off" 1 "On";
VAL_ 411 WhistleSts_F_PBox 0 "Off" 1 "On";
VAL_ 699 U_BATT 0 "valid value" 15360 "valid value" 15361 "Reserved" 16382 "Reserved" 16383 "Invalid";
VAL_ 699 I_RANGE 0 "current Range [-1, 1A]" 1 "current Range [-200, 200A]" 2 "current Range [-1500, 1500A]" 3 "Invalid";
VAL_ 699 I_BATT 7168 "valid value [-200, 200A]" 8768 "valid value  [-1500, 1500A]" 31744 "valid value[-1, 1A]" 33792 "valid value[-1, 1A]" 56768 "valid value  [-1500, 1500A]" 58368 "valid value [-200, 200A]" 65535 "Invalid";
VAL_ 699 SOC 0 "valid value" 100 "valid value" 101 "Reserved" 254 "Reserved" 255 "Invalid";
VAL_ 699 SOH_SUL 0 "valid value" 100 "valid value" 101 "Reserved" 254 "Reserved" 255 "Invalid";
VAL_ 699 SOC_STATE 0 "deviation > 15%" 1 "deviation <15%" 2 "deviation < 10%" 3 "Invalid";
VAL_ 699 SOH_SUL_STATE 0 "not learned" 1 "learned" 2 "Reserved" 3 "Invalid";
VAL_ 699 OTA_UpgrdModSts 0 "Upgrade_mode_Off" 1 "Remote_upgrade_mode_ON_Powertrain_OFF" 2 "Normal_upgrade_mode_ON_Powertrain_OFF" 3 "Reserved";
VAL_ 699 CheckSum_GWM1 0 "Valid value" 255 "Valid value";
VAL_ 699 RollingCounter_GWM1 0 "Valid value" 14 "Valid value" 15 "Invalid value";
VAL_ 347 APS_PrkgMod 0 "None" 1 "Parking in" 2 "Parking out" 3 "Reserved";
VAL_ 347 APS_ProcBar 0 "0-100" 100 "0-100" 101 "Reserved" 126 "Reserved" 127 "No Display";
VAL_ 347 APS_SwtSts 0 "no press" 1 "press";
VAL_ 347 APS_SlotDisp 0 "No parking slot" 1 "Left parallel parking slot" 2 "Left vertical parking slot" 3 "Left T-shape parking slot" 4 "Right parallel parking slot" 5 "Right vertical parking slot" 6 "Right T-shape parking slot" 7 "Reserved";
VAL_ 347 APS_SysSoundIndcn 0 "Tone 0 - No Warning" 1 "Tone 1 - APS failed tone" 2 "Tone 2 - APS successful tone" 3 "Tone 3 - APS warning tone" 4 "Tone 4 - APS request tone" 5 "Reserved" 7 "Reserved";
VAL_ 347 APS_PrkgTyp 0 "None" 1 "Parallel parking" 2 "Vertical parking" 3 "Reserved";
VAL_ 347 APS_TextDisp 0 "No Request" 1 "Wrong gear position to start parking" 2 "Turn D to search for slot" 3 "Please close the trunk" 4 "Please close the door" 5 "Please fasten the seat belt" 6 "Please unfold the Mirror" 7 "Speed is too high,need <23kmh" 8 "System error Parking sys exits" 9 "control unit error parking sys exits" 10 "Please brake" 11 "please select parking mode" 12 "please select internal parking" 13 "please select Slot and parking mode" 14 "please select Slot and internal parking" 15 "Please keep braking" 16 "Hands off the steering wheel" 17 "Release the brake,parking start" 18 "Auto parking,be ready to brake" 19 "parking suspended,close trunk" 20 "parking suspended,close door" 21 "parking suspended,fasten seat belt" 22 "Obstacles Detected" 23 "brake recovered,confirm to continue" 24 "Parking quited" 25 "parking   finished" 26 "interfered by driver parking quited" 27 "too many parking times parking sys exits" 28 "Parking time too long Parking sys exits" 29 "Too Small Slot Parking sys exits" 30 "Please Clean the Camera" 31 "Select the parking mode(APA3)" 32 "Searching the right slot" 33 "Searching the left slot" 34 "Please turn D to search for parking slot" 35 "Speed is too high,need <30kmh" 36 "Speed is too high,sys exits" 37 "Select parking type" 38 "Long press switch 2s to enter auto parking" 39 "Parking suspended,Please release the gas pedal" 40 "Please brake,And long press switch 2s to continue auto parking" 41 "Parking is not available" 42 "Please select the parking direction by turning the turn switch" 43 "Please brake,And long press switch 2s to enter_POC_left" 44 "Parking sys exits" 45 "Parking suspended,fold the Mirror" 46 "Too Small Slot Please select another direction" 47 "Driving Mode not supported" 48 "Path is smooth" 49 "Please select park out" 50 "Please select park out direction" 51 "Please get off the car with keys to start remote parking" 52 "Please confirm to start parking" 53 "Remote Parking in exit" 54 "Parking suspended,Remote connection error" 55 "System error,Parking sys can not start" 56 "Control unit error,Parking sys can not start" 57 "Please Turn P and Apply EPB Remote parking sys not Running" 58 "Select Remote parking out type" 59 "Please brake,And long press switch 2s to enter_POC_Right" 60 "Please release switch to en-ter guidance" 61 "Slope over ,system exits" 62 "Please select Summon Path" 63 "Reserved" 64 "Path study begin please drive the car" 65 "Path studying" 66 "Confirm study finished" 67 "Path studying failed caused by Path too long" 68 "Path studying failed caused by Speed too high" 69 "Path studying failed caused by communication error" 70 "Path studying failed caused by Path error" 71 "Path studying failed caused by learn time too long" 72 "Path studying failed caused by internal error" 73 "Path studying failed caused by Path too short" 74 "Path studying failed caused by Path backward too long" 75 "Path studying failed caused by shift gear too many times" 76 "Speed is too high,need <5kmh" 77 "Speed is too high,need <10kmh" 78 "Speed is too high,need <15kmh" 79 "Reserved" 80 "Path saving" 81 "Path saving Succeed" 82 "Path saving failed caused by Path too short" 83 "Path saving failed caused by communication error" 84 "Path saving failed caused by Path error" 85 "Path saving failed caused by Path error limit storage room" 86 "Path saving failed caused by internal error" 87 "Reserved" 95 "Reserved" 96 "Please drive to path start point" 97 "Path matche please stop" 98 "Please select play back mode" 99 "Path match failed caused by communication error" 100 "Path match failed caused by path error" 101 "Path match failed caused by long time no action" 102 "Path match failed caused by internal error" 103 "Reserved" 111 "Reserved" 112 "No save distance,RADS sys esits" 113 "RADS running,be ready to brake" 114 "Near the bourn" 115 "Arrive at the bourn" 116 "Release the brake" 117 "Trunk open,RADS sys exits" 118 "Door open,RADS sys exits" 119 "Seat belt drop,RADS sys exits" 120 "Mirror fold,RADS sys exits" 121 "Obstacles Detected,RADS sys exits" 122 "No continue driving Parking quited" 123 "Please turn to R" 124 "Release the brake,Driving assistance start" 125 "Please turn to D" 126 "Reserved for RADS" 127 "Reserved for RADS" 128 "FADS running,be ready to brake" 129 "Trunk open,FADS sys exits" 130 "Door open,FADS sys exits" 131 "Seat belt drop,FADS sys exits" 132 "Mirror fold,FADS sys exits" 133 "Obstacles Detected,FADS sys exits" 134 "Vehicle can not move,FADS sys exits" 135 "Remote control straight Search" 136 "Over limit search distance" 137 "Please select suitable parking slot icon" 138 "Please drag the parking slot to suitable place and adjust the angle" 139 "Move over 25m,system exits" 140 "Move over 5m,system exits" 142 "Reserved" 255 "Reserved";
VAL_ 347 APS_WorkSts 0 "Disable" 1 "Standby" 2 "Searching" 3 "Guidance" 4 "Failed" 5 "Wait for Engine restart" 6 "Reserved" 7 "Reserved";
VAL_ 347 MEB_AVHReq 0 "No Request" 1 "Request";
VAL_ 347 APS_ESP_BrkDistance 0 "Valid value" 4095 "Valid value";
VAL_ 347 LParaPrkgOutVald 0 "valid" 1 "Invalid";
VAL_ 347 RParaPrkgOutVald 0 "valid" 1 "Invalid";
VAL_ 347 HeadVertPrkgOutVald 0 "valid" 1 "Invalid";
VAL_ 347 TailVertPrkgOutVald 0 "valid" 1 "Invalid";
VAL_ 347 HAP_SwtDispCtrlCmd 0 "no display" 1 "park out direction Select menu" 2 "continue park menu" 3 "Study finish button" 4 "RDAS distance arrow" 5 "RDAS active distance arrow steering" 6 "Reserved" 7 "Reserved";
VAL_ 347 HAP_PrkgModCurrSts 0 "No display" 1 "Left parallel park in" 2 "Right parallel park in" 3 "Left vert park in" 4 "Right vert park in" 5 "Left Tshape park in" 6 "Right Tshape park in" 7 "Left parallel park out" 8 "Right parallel park out" 9 "Front vert park out" 10 "Rear vert park out" 11 "P2P Summon" 12 "Reserved" 15 "Reserved";
VAL_ 347 APS_MovgDirc 0 "No Display" 1 "Moving forward" 2 "Moving backward" 3 "Reserved";
VAL_ 347 ParallelSlotBtn_Ena 0 "No Display" 1 "Disable" 2 "Enable" 3 "Active";
VAL_ 347 VerticalSlotBtn_Ena 0 "No Display" 1 "Disable" 2 "Enable" 3 "Active";
VAL_ 347 ClockwiseBtn_Ena 0 "No Display" 1 "Disable" 2 "Enable" 3 "Active";
VAL_ 347 AnticlockwiseBtn_Ena 0 "No Display" 1 "Disable" 2 "Enable" 3 "Active";
VAL_ 347 SlotConfirmBtn_Ena 0 "No Display" 1 "Disable" 2 "Enable" 3 "Active";
VAL_ 347 HAVP_StopBtn_Ena 0 "No Display" 1 "Disable" 2 "Enable" 3 "Active";
VAL_ 347 HAVP_StartBtn_Ena 0 "No Display" 1 "Disable" 2 "Enable" 3 "Active";
VAL_ 347 HAVP_SelfParLotEnding_Ena 0 "No Display" 1 "Disable" 2 "Enable" 3 "Active";
VAL_ 347 PAVP_TextDis 0 "No tex" 1 "Selfchecking" 2 "AVP unavailable" 3 "Map update failed" 4 "Wrong position" 5 "Req_Close_Door_all doors" 6 "Req_Close_Hood_door" 7 "Req_Close_Trunk_door" 8 "Req_Gear_P_EPB" 9 "Path download failed" 10 "Power off failed" 11 "Pick-up location" 12 "Drop-off area" 13 "No parking lot" 14 "Parking in inprocess" 15 "Parking in complete" 16 "Task failed" 17 "Parking out in process" 18 "Cruising" 19 "Parking out complete" 20 "Req_Quit_System failure" 21 "Req_Suspend_User Req" 22 "Req_Quit_EPS failure" 23 "Req_Quit_ESP failure" 24 "Req_Abort_Terminate_Button_Pressed_HMI_Cancel_RD_Cancel" 25 "Req_Abort_Steering Wheel Intervention" 26 "Req_Abort_Gear Intervention" 27 "Req_Abort_EPB Intervention" 28 "Req_Abort_Function Activation" 29 "Reserved" 31 "Reserved" 32 "Req_Abort_Parking Timeout" 33 "Req_Abort_Speed high" 34 "Req_Abort_Parking Too Many Times" 35 "Req_Abort_Hood Open" 36 "Req_Abort_Trunk Open" 37 "Req_Abort_Door Open" 38 "Req_Abort_Deficient Space" 39 "Req_Abort_Network Disconnection" 40 "Req_Abort_Path Invalid" 41 "Req_Abort_Parking Lot Invalid" 42 "Req_Abort_Rear Mirror Fold" 43 "Req_Abort_ODD Dissatisfied" 44 "Req_Abort_Suspend Too Many Times" 45 "Req_Abort_Suspend Timeout" 46 "Req_Abort_Tire Pressure" 47 "Req_Abort_TBOX Err" 48 "Network fault" 49 "No parking area" 50 "Reserved" 63 "Reserved";
VAL_ 628 AutoAVMSwtSet_Sts 0 "Off" 1 "ON";
VAL_ 628 AVM_CurrSts 0 "Off" 1 "ON" 2 "AVM no videoÃ¯Â¼ÂˆÃ©Â›Â·Ã¨Â¾Â¾Ã¦Â¨Â¡Ã¥Â¼ÂÃ¯Â¼Â‰" 3 "Reserved";
VAL_ 628 GuidOvlSts 0 "Around View and Single View" 1 "Only Around View" 2 "Only Single View" 3 "No Guidance";
VAL_ 628 FrntCamInpFailSts 0 "no failure" 1 "failure";
VAL_ 628 RearCamInpFailSts 0 "no failure" 1 "failure";
VAL_ 628 LeCamInpFailSts 0 "no failure" 1 "failure";
VAL_ 628 RiCamInpFailSts 0 "no failure" 1 "failure";
VAL_ 628 EolNotCmpltd 0 "Ccompleted" 1 "No completed";
VAL_ 628 OvlOpFailSts 0 "no failure" 1 "failure";
VAL_ 628 LaneCalSts 0 "No Commands" 1 "In Calibration process" 2 "Calibration success" 3 "Calibration failure";
VAL_ 628 RadarDispSts 0 "Both Around View and Single View Radar Display" 1 "Only Around View Radar Display" 2 "Only Single View Radar Display" 3 "No Radar Display";
VAL_ 628 LaneCalFltSts 0 "No fault" 1 "Front view Calibration abnormal" 2 "Rear view Calibration abnormal" 3 "left view Calibration abnormal" 4 "Right view Calibration abnormal" 5 "Calibration data storage failed" 6 "Reserved" 7 "Reserved";
VAL_ 628 AutoViewChgFuncSts 0 "Off" 1 "ON";
VAL_ 628 CarMdlTrsprcySts 0 "Opaque" 1 "Translucent" 2 "Completely transparent" 3 "Reserved";
VAL_ 628 CarMdlDispSts 0 "2D mode" 1 "3D mode";
VAL_ 628 CurrCalResultSts 0 "Use Factory Calibration Result" 1 "Use Lane Calibration Result";
VAL_ 628 MdlColrSts 0 "Silvery" 1 "Red" 2 "Gray" 3 "White" 4 "Black" 5 "Brown" 6 "Blue" 7 "Orange" 8 "Green" 9 "Gold" 10 "Purple" 11 "Reserved" 15 "Reserved";
VAL_ 628 SigViewIndcn 0 "No Commands" 1 "Front to Center View" 2 "Rear to Center View" 3 "Left to Center View" 4 "Right to Center View" 5 "Left Front to Center View" 6 "Right Front to Center View" 7 "Left Rear to Center View" 8 "Right Rear to Center View" 9 "Front View" 10 "Rear View" 11 "Left View" 12 "Right View" 13 "Left Turn 3D View" 14 "Right Turn 3D View" 15 "Front Overlook View" 16 "Rear Overlook View" 17 "Front 180 Deg View" 18 "Rear 180 Deg View" 19 "Front Wheel View" 20 "Rear Wheel View" 21 "Front Wash View" 22 "Rear Wash View" 23 "Free_3D View" 24 "LeftRight View" 25 "Engine Room View" 26 "CCO View" 27 "Reserved" 62 "Reserved" 63 "3D Car Model Round View";
VAL_ 628 HAP_DispCmd 0 "OFF" 1 "ON";
VAL_ 628 AVM_3DAngSts 0 "Not active" 1 "0~360Ã‚Â°" 361 "0~360Ã‚Â°" 362 "reserved" 510 "reserved" 511 "invalid";
VAL_ 628 MOD_WorkSts 0 "OFF" 1 "ON";
VAL_ 628 MOD_AlarmSts 0 "OFF" 1 "ON";
VAL_ 628 DVRWorkSts 0 "DVR_Standby" 1 "DVR_Active" 2 "DVR_InterFailed" 3 "DVR_NetFailed";
VAL_ 628 HAP_Hmi_Index 0 "Reserved" 1 "Main Screen" 2 "EOLTest" 3 "P2P Screen" 4 "Assist Screen" 5 "HAVP Screen" 6 "PAVP Screen" 7 "Reserved" 15 "Reserved";
VAL_ 664 RPAS_NearBrrdstn 0 "Valid value" 150 "Valid value" 151 "Reserved" 254 "Reserved" 255 "No Display";
VAL_ 664 HAVP_ProcRa 0 "0-100%" 100 "0-100%" 101 "Reserved" 126 "Reserved" 127 "No Display";
VAL_ 664 APS_ObjRiSideAr1 0 "No object" 1 "Object in zone 1, 0~10cm" 2 "Object in zone 2, 11~20cm" 3 "Object in zone 3, 21~30cm" 4 "Object in zone 4, 31~40cm" 5 "Object in zone 5, 41~50cm" 6 "Object in zone 6, 51~60cm" 7 "Reserved" 15 "Reserved";
VAL_ 664 APS_ObjRiSideAr2 0 "No object" 1 "Object in zone 1, 0~10cm" 2 "Object in zone 2, 11~20cm" 3 "Object in zone 3, 21~30cm" 4 "Object in zone 4, 31~40cm" 5 "Object in zone 5, 41~50cm" 6 "Object in zone 6, 51~60cm" 7 "Reserved" 15 "Reserved";
VAL_ 664 APS_ObjRiSideAr3 0 "No object" 1 "Object in zone 1, 0~10cm" 2 "Object in zone 2, 11~20cm" 3 "Object in zone 3, 21~30cm" 4 "Object in zone 4, 31~40cm" 5 "Object in zone 5, 41~50cm" 6 "Object in zone 6, 51~60cm" 7 "Reserved" 15 "Reserved";
VAL_ 664 APS_ObjRiSideAr4 0 "No object" 1 "Object in zone 1, 0~10cm" 2 "Object in zone 2, 11~20cm" 3 "Object in zone 3, 21~30cm" 4 "Object in zone 4, 31~40cm" 5 "Object in zone 5, 41~50cm" 6 "Object in zone 6, 51~60cm" 7 "Reserved" 15 "Reserved";
VAL_ 664 APS_ObjRiSideAr5 0 "No object" 1 "Object in zone 1, 0~10cm" 2 "Object in zone 2, 11~20cm" 3 "Object in zone 3, 21~30cm" 4 "Object in zone 4, 31~40cm" 5 "Object in zone 5, 41~50cm" 6 "Object in zone 6, 51~60cm" 7 "Reserved" 15 "Reserved";
VAL_ 664 APS_ObjLeSideAr1 0 "No object" 1 "Object in zone 1, 0~10cm" 2 "Object in zone 2, 11~20cm" 3 "Object in zone 3, 21~30cm" 4 "Object in zone 4, 31~40cm" 5 "Object in zone 5, 41~50cm" 6 "Object in zone 6, 51~60cm" 7 "Reserved" 15 "Reserved";
VAL_ 664 APS_ObjLeSideAr2 0 "No object" 1 "Object in zone 1, 0~10cm" 2 "Object in zone 2, 11~20cm" 3 "Object in zone 3, 21~30cm" 4 "Object in zone 4, 31~40cm" 5 "Object in zone 5, 41~50cm" 6 "Object in zone 6, 51~60cm" 7 "Reserved" 15 "Reserved";
VAL_ 664 APS_ObjLeSideAr3 0 "No object" 1 "Object in zone 1, 0~10cm" 2 "Object in zone 2, 11~20cm" 3 "Object in zone 3, 21~30cm" 4 "Object in zone 4, 31~40cm" 5 "Object in zone 5, 41~50cm" 6 "Object in zone 6, 51~60cm" 7 "Reserved" 15 "Reserved";
VAL_ 664 APS_ObjLeSideAr4 0 "No object" 1 "Object in zone 1, 0~10cm" 2 "Object in zone 2, 11~20cm" 3 "Object in zone 3, 21~30cm" 4 "Object in zone 4, 31~40cm" 5 "Object in zone 5, 41~50cm" 6 "Object in zone 6, 51~60cm" 7 "Reserved" 15 "Reserved";
VAL_ 664 APS_ObjLeSideAr5 0 "No object" 1 "Object in zone 1, 0~10cm" 2 "Object in zone 2, 11~20cm" 3 "Object in zone 3, 21~30cm" 4 "Object in zone 4, 31~40cm" 5 "Object in zone 5, 41~50cm" 6 "Object in zone 6, 51~60cm" 7 "Reserved" 15 "Reserved";
VAL_ 664 APS_FRSideSnsrFailSts 0 "no failure" 1 "failure";
VAL_ 664 APS_FLSideSnsrFailSts 0 "no failure" 1 "failure";
VAL_ 664 APS_RRSideSnsrFailSts 0 "no failure" 1 "failure";
VAL_ 664 APS_RLSideSnsrFailSts 0 "no failure" 1 "failure";
VAL_ 664 SDW_SoundIndcn 0 "Tone 0 - No warning" 1 "Tone 1 - Long beep" 2 "Tone 2 - 1.5 Hz" 3 "Tone 3 - 3Hz";
VAL_ 664 SDWActiveSts 0 "Not active" 1 "Active";
VAL_ 664 RPAS_ObjRRCornrAr1 0 "No object" 1 "Object in zone 1, 0~10cm" 2 "Object in zone 2, 11~20cm" 3 "Object in zone 3, 21~30cm" 4 "Object in zone 4, 31~40cm" 5 "Object in zone 5, 41~50cm" 6 "Object in zone 6, 51~60cm" 7 "Reserved" 15 "Reserved";
VAL_ 664 RPAS_ObjRRCornrAr2 0 "No object" 1 "Object in zone 1, 0~10cm" 2 "Object in zone 2, 11~20cm" 3 "Object in zone 3, 21~30cm" 4 "Object in zone 4, 31~40cm" 5 "Object in zone 5, 41~50cm" 6 "Object in zone 6, 51~60cm" 7 "Reserved" 15 "Reserved";
VAL_ 664 RPAS_ObjRRMidlAr1 0 "No object" 1 "Object in zone 1, 0~10cm" 2 "Object in zone 2, 11~20cm" 3 "Object in zone 3, 21~30cm" 4 "Object in zone 4, 31~40cm" 5 "Object in zone 5, 41~50cm" 6 "Object in zone 6, 51~60cm" 7 "Object in zone 7, 61~70cm" 8 "Object in zone 8, 71~80cm" 9 "Object in zone 9, 81~90cm" 10 "Object in zone 10, 91~100cm" 11 "Object in zone 11, 101~110cm" 12 "Object in zone 12, 111~120cm" 13 "Object in zone 13, 121~130cm" 14 "Object in zone 14, 131~140cm" 15 "Object in zone 15, 141~150cm";
VAL_ 664 RPAS_ObjRRMidlAr2 0 "No object" 1 "Object in zone 1, 0~10cm" 2 "Object in zone 2, 11~20cm" 3 "Object in zone 3, 21~30cm" 4 "Object in zone 4, 31~40cm" 5 "Object in zone 5, 41~50cm" 6 "Object in zone 6, 51~60cm" 7 "Object in zone 7, 61~70cm" 8 "Object in zone 8, 71~80cm" 9 "Object in zone 9, 81~90cm" 10 "Object in zone 10, 91~100cm" 11 "Object in zone 11, 101~110cm" 12 "Object in zone 12, 111~120cm" 13 "Object in zone 13, 121~130cm" 14 "Object in zone 14, 131~140cm" 15 "Object in zone 15, 141~150cm";
VAL_ 664 RPAS_ObjRLMidlAr1 0 "No object" 1 "Object in zone 1, 0~10cm" 2 "Object in zone 2, 11~20cm" 3 "Object in zone 3, 21~30cm" 4 "Object in zone 4, 31~40cm" 5 "Object in zone 5, 41~50cm" 6 "Object in zone 6, 51~60cm" 7 "Object in zone 7, 61~70cm" 8 "Object in zone 8, 71~80cm" 9 "Object in zone 9, 81~90cm" 10 "Object in zone 10, 91~100cm" 11 "Object in zone 11, 101~110cm" 12 "Object in zone 12, 111~120cm" 13 "Object in zone 13, 121~130cm" 14 "Object in zone 14, 131~140cm" 15 "Object in zone 15, 141~150cm";
VAL_ 664 RPAS_ObjRLMidlAr2 0 "No object" 1 "Object in zone 1, 0~10cm" 2 "Object in zone 2, 11~20cm" 3 "Object in zone 3, 21~30cm" 4 "Object in zone 4, 31~40cm" 5 "Object in zone 5, 41~50cm" 6 "Object in zone 6, 51~60cm" 7 "Object in zone 7, 61~70cm" 8 "Object in zone 8, 71~80cm" 9 "Object in zone 9, 81~90cm" 10 "Object in zone 10, 91~100cm" 11 "Object in zone 11, 101~110cm" 12 "Object in zone 12, 111~120cm" 13 "Object in zone 13, 121~130cm" 14 "Object in zone 14, 131~140cm" 15 "Object in zone 15, 141~150cm";
VAL_ 664 RPAS_ObjRLCornrAr1 0 "No object" 1 "Object in zone 1, 0~10cm" 2 "Object in zone 2, 11~20cm" 3 "Object in zone 3, 21~30cm" 4 "Object in zone 4, 31~40cm" 5 "Object in zone 5, 41~50cm" 6 "Object in zone 6, 51~60cm" 7 "Reserved" 15 "Reserved";
VAL_ 664 RPAS_ObjRLCornrAr2 0 "No object" 1 "Object in zone 1, 0~10cm" 2 "Object in zone 2, 11~20cm" 3 "Object in zone 3, 21~30cm" 4 "Object in zone 4, 31~40cm" 5 "Object in zone 5, 41~50cm" 6 "Object in zone 6, 51~60cm" 7 "Reserved" 15 "Reserved";
VAL_ 664 RPAS_RLCornrSnsrFailSts 0 "no failure" 1 "failure";
VAL_ 664 RPAS_RLMiddlSnsrFailSts 0 "no failure" 1 "failure";
VAL_ 664 RPAS_RRMiddlSnsrFailSts 0 "no failure" 1 "failure";
VAL_ 664 RPAS_RRCornrSnsrFailSts 0 "no failure" 1 "failure";
VAL_ 664 RPAS_WorkSts 0 "Disable" 1 "Enable" 2 "Active" 3 "Failed";
VAL_ 664 RPAS_SoundIndcn 0 "Tone zero No warning" 1 "Tone one  Long beep" 2 "Tone two 1.5 Hz" 3 "Tone three  3Hz";
VAL_ 664 MEBWorkSts 0 "Off" 1 "Enable" 2 "Active" 3 "Failed";
VAL_ 664 MEB_EnableSts 0 "Disable" 1 "Enable";
VAL_ 664 FPAS_ObjFLCornrAr1 0 "No object" 1 "Object in zone 1, 0~10cm" 2 "Object in zone 2, 11~20cm" 3 "Object in zone 3, 21~30cm" 4 "Object in zone 4, 31~40cm" 5 "Object in zone 5, 41~50cm" 6 "Object in zone 6, 51~60cm" 7 "Reserved" 15 "Reserved";
VAL_ 664 FPAS_ObjFLCornrAr2 0 "No object" 1 "Object in zone 1, 0~10cm" 2 "Object in zone 2, 11~20cm" 3 "Object in zone 3, 21~30cm" 4 "Object in zone 4, 31~40cm" 5 "Object in zone 5, 41~50cm" 6 "Object in zone 6, 51~60cm" 7 "Reserved" 15 "Reserved";
VAL_ 664 FPAS_ObjFLMidlAr1 0 "No object" 1 "Object in zone 1, 0~10cm" 2 "Object in zone 2, 11~20cm" 3 "Object in zone 3, 21~30cm" 4 "Object in zone 4, 31~40cm" 5 "Object in zone 5, 41~50cm" 6 "Object in zone 6, 51~60cm" 7 "Object in zone 7, 61~70cm" 8 "Object in zone 8, 71~80cm" 9 "Object in zone 9, 81~90cm" 10 "Object in zone 10, 91~100cm" 11 "Reserved" 15 "Reserved";
VAL_ 664 FPAS_ObjFLMidlAr2 0 "No object" 1 "Object in zone 1, 0~10cm" 2 "Object in zone 2, 11~20cm" 3 "Object in zone 3, 21~30cm" 4 "Object in zone 4, 31~40cm" 5 "Object in zone 5, 41~50cm" 6 "Object in zone 6, 51~60cm" 7 "Object in zone 7, 61~70cm" 8 "Object in zone 8, 71~80cm" 9 "Object in zone 9, 81~90cm" 10 "Object in zone 10, 91~100cm" 11 "Reserved" 15 "Reserved";
VAL_ 664 FPAS_ObjFRMidlAr1 0 "No object" 1 "Object in zone 1, 0~10cm" 2 "Object in zone 2, 11~20cm" 3 "Object in zone 3, 21~30cm" 4 "Object in zone 4, 31~40cm" 5 "Object in zone 5, 41~50cm" 6 "Object in zone 6, 51~60cm" 7 "Object in zone 7, 61~70cm" 8 "Object in zone 8, 71~80cm" 9 "Object in zone 9, 81~90cm" 10 "Object in zone 10, 91~100cm" 11 "Reserved" 15 "Reserved";
VAL_ 664 FPAS_ObjFRMidlAr2 0 "No object" 1 "Object in zone 1, 0~10cm" 2 "Object in zone 2, 11~20cm" 3 "Object in zone 3, 21~30cm" 4 "Object in zone 4, 31~40cm" 5 "Object in zone 5, 41~50cm" 6 "Object in zone 6, 51~60cm" 7 "Object in zone 7, 61~70cm" 8 "Object in zone 8, 71~80cm" 9 "Object in zone 9, 81~90cm" 10 "Object in zone 10, 91~100cm" 11 "Reserved" 15 "Reserved";
VAL_ 664 FPAS_ObjFRCornrAr1 0 "No object" 1 "Object in zone 1, 0~10cm" 2 "Object in zone 2, 11~20cm" 3 "Object in zone 3, 21~30cm" 4 "Object in zone 4, 31~40cm" 5 "Object in zone 5, 41~50cm" 6 "Object in zone 6, 51~60cm" 7 "Reserved" 15 "Reserved";
VAL_ 664 FPAS_ObjFRCornrAr2 0 "No object" 1 "Object in zone 1, 0~10cm" 2 "Object in zone 2, 11~20cm" 3 "Object in zone 3, 21~30cm" 4 "Object in zone 4, 31~40cm" 5 "Object in zone 5, 41~50cm" 6 "Object in zone 6, 51~60cm" 7 "Reserved" 15 "Reserved";
VAL_ 664 FPAS_FLCornrSnsrFailSts 0 "no failure" 1 "failure";
VAL_ 664 FPAS_FLMiddlSnsrFailSts 0 "no failure" 1 "failure";
VAL_ 664 FPAS_FRMiddlSnsrFailSts 0 "no failure" 1 "failure";
VAL_ 664 FPAS_FRCornrSnsrFailSts 0 "no failure" 1 "failure";
VAL_ 664 FPAS_WorkSts 0 "Disable" 1 "Enable" 2 "Active" 3 "Failed";
VAL_ 664 FPAS_AutoModSts 0 "Not available" 1 "available";
VAL_ 664 FPAS_SoundIndcn 0 "Tone zero  No warning" 1 "Tone one  Long beep" 2 "Tone two 1.5 Hz" 3 "Tone three 3Hz";
VAL_ 664 FPAS_NearBrrdstn 0 "Valid value" 100 "Valid value" 101 "Reserved" 126 "Reserved" 127 "No Display";
VAL_ 664 APA_MenuDispCtrlCmd 0 "No_Disp_avm_menu" 1 "park_in_indicate_menu" 2 "park_in_select_slot_menu" 3 "park_in_mode_select_menu" 4 "park_in_process" 5 "remote_park_in_process" 6 "park_out_confirm_menu" 7 "park_out_process" 8 "park_in_indicate_menu_NoRPA" 9 "park_in_select_slot_menu_NoRPA" 10 "park_in_mode_select_menu_NoRPA" 11 "park_out _indicate_menu" 12 "Reversed" 15 "Reversed";
VAL_ 664 APA_FuncSts 0 "APA Function standby" 1 "APA Function active" 2 "APA Function disable" 3 "Reserved";
VAL_ 664 RADS_FuncSts 0 "Reverse Asist Function standby" 1 "Reverse Asist Function active" 2 "Reverse Asist Function disable" 3 "Reserved";
VAL_ 664 FADS_FuncSts 0 "FADS Function standby" 1 "FADS Function active" 2 "FADS Function disable" 3 "Reserved";
VAL_ 664 HAP_TextIconDispCtrl 0 "No display" 1 "Display According to text info" 2 "Display parking mode" 3 "Reserved";
VAL_ 649 HAP_RtCam_WorkSts 0 "Disable" 1 "Enable" 2 "Active" 3 "Failed";
VAL_ 649 HAP_RtSide_Obj1_ID 0 "Valid values" 3 "Valid values" 4 "Invalid values" 15 "Invalid values";
VAL_ 649 HAP_RtSide_Obj1_type 0 "No target" 1 "Pedestrian" 2 "Biker" 3 "Vehicle" 4 "Ground Locker" 5 "Barrier" 6 "Reserved" 7 "Unknown type";
VAL_ 649 HAP_RtSide_Obj1_Confidence 0 "Valid value" 10 "Invalid" 15 "Invalid";
VAL_ 649 HAP_RtSide_Obj1_Ground_Pos_X 0 "Valid values" 4000 "Valid values" 4001 "Reserved" 4094 "Reserved" 4095 "Invalid values";
VAL_ 649 HAP_RtSide_Obj1_Ground_Pos_Y 0 "Valid values" 4000 "Valid values" 4001 "Reserved" 4094 "Reserved" 4095 "Invalid values";
VAL_ 649 HAP_RtSide_Obj2_ID 0 "Valid values" 3 "Valid values" 4 "Invalid values" 15 "Invalid values";
VAL_ 649 HAP_RtSide_Obj2_type 0 "No target" 1 "Pedestrian" 2 "Biker" 3 "Vehicle" 4 "Ground Locker" 5 "Barrier" 6 "Reserved" 7 "Unknown type";
VAL_ 649 HAP_RtSide_Obj2_Confidence 0 "Valid value" 10 "Invalid" 15 "Invalid";
VAL_ 649 HAP_RtSide_Obj2_Ground_Pos_X 0 "Valid values" 4000 "Valid values" 4001 "Reserved" 4094 "Reserved" 4095 "Invalid values";
VAL_ 649 HAP_RtSide_Obj2_Ground_Pos_Y 0 "Valid values" 4000 "Valid values" 4001 "Reserved" 4094 "Reserved" 4095 "Invalid values";
VAL_ 649 HAP_RtSide_Obj3_ID 0 "Valid values" 3 "Valid values" 4 "Invalid values" 15 "Invalid values";
VAL_ 649 HAP_RtSide_Obj3_type 0 "No target" 1 "Pedestrian" 2 "Biker" 3 "Vehicle" 4 "Ground Locker" 5 "Barrier" 6 "Reserved" 7 "Unknown type";
VAL_ 649 HAP_RtSide_Obj3_Confidence 0 "Valid value" 10 "Invalid" 15 "Invalid";
VAL_ 649 HAP_RtSide_Obj3_Ground_Pos_X 0 "Valid values" 4000 "Valid values" 4001 "Reserved" 4094 "Reserved" 4095 "Invalid values";
VAL_ 649 HAP_RtSide_Obj3_Ground_Pos_Y 0 "Valid values" 4000 "Valid values" 4001 "Reserved" 4094 "Reserved" 4095 "Invalid values";
VAL_ 649 HAP_RtSide_Obj4_ID 0 "Valid values" 3 "Valid values" 4 "Invalid values" 15 "Invalid values";
VAL_ 649 HAP_RtSide_Obj4_type 0 "No target" 1 "Pedestrian" 2 "Biker" 3 "Vehicle" 4 "Ground Locker" 5 "Barrier" 6 "Reserved" 7 "Unknown type";
VAL_ 649 HAP_RtSide_Obj4_Confidence 0 "Valid value" 10 "Invalid" 15 "Invalid";
VAL_ 649 HAP_RtSide_Obj4_Ground_Pos_X 0 "Valid values" 4000 "Valid values" 4001 "Reserved" 4094 "Reserved" 4095 "Invalid values";
VAL_ 649 HAP_RtSide_Obj4_Ground_Pos_Y 0 "Valid values" 4000 "Valid values" 4001 "Reserved" 4094 "Reserved" 4095 "Invalid values";
VAL_ 649 USS_FLSide1_Status 0 "Disable" 1 "Enable" 2 "Active" 3 "Failed";
VAL_ 649 USS_FLSide1_Dist 0 "Valid values" 126 "Valid values" 127 "Invalid";
VAL_ 649 USS_RLSide2_Status 0 "Disable" 1 "Enable" 2 "Active" 3 "Failed";
VAL_ 649 USS_RLSide2_Dist 0 "Valid values" 126 "Valid values" 127 "Invalid";
VAL_ 649 USS_FRSide1_Status 0 "Disable" 1 "Enable" 2 "Active" 3 "Failed";
VAL_ 649 USS_FRSide1_Dist 0 "Valid values" 126 "Valid values" 127 "Invalid";
VAL_ 649 USS_RRSide2_Status 0 "Disable" 1 "Enable" 2 "Active" 3 "Failed";
VAL_ 649 USS_RRSide2_Dist 0 "Valid values" 126 "Valid values" 127 "Invalid";
VAL_ 667 HAVP_LrngDst 0 "Valid values" 200 "Valid values" 201 "Invalid" 254 "Invalid" 255 "No Display";
VAL_ 667 HAVP_HUT_TextDisp 0 "Idle" 1 "Path list screen" 2 "Reserved" 3 "Path learning inprocess,set starting point after stop" 4 "Insufficient brightness,reset starting point" 5 "Too empty environment,reset start-ing point" 6 "Front car is too close,reset starting point" 7 "Camera is blocked,reset starting point" 8 "Environment is abnormal,reset starting point" 9 "Path learning inprocess,continue driving to ending point" 10 "Path learning inprocess,set ending point or choose ending lot after stop" 11 "Too high speed,lower speed below 15kmh" 12 "Too high speed,path learning quit" 13 "Distance limited, set ending point after stop" 14 "Distance exceed,path learning quit" 15 "Too long time,path learning quit" 16 "Insufficient brightness,reset end-ing point" 17 "Too empty environment,reset ending point" 18 "Front car is too close,reset ending point" 19 "Camera is blocked,reset ending point" 20 "Environment is abnormal,reset ending point" 21 "Please select new path parking lot" 22 "Please set path name" 23 "Please wait, path generating" 24 "Whether auto parking in" 25 "System error,function quit" 26 "Path learning succeed" 27 "Insufficient brightness,path learning failed" 28 "Too empty environment,path learning failed" 29 "Front car is too close,path learn-ing failed" 30 "Camera is blocked,path learning failed" 31 "Environment is abnormal,path learning failed" 32 "Path matching, driving to learned path scope" 33 "Path matching timeout, parking quit" 34 "Path matched succeed, stop and apply P+EPB" 35 "Please activite HAVP on APP" 36 "Show HAVP inprocess picture" 37 "Please select suitable parking slot icon" 38 "Please drag the parking slot to suitable place and adjust the angle" 39 "Reserved" 63 "Reserved";
VAL_ 962 HCU_RecupPwr 0 "Valid value" 1023 "Valid value";
VAL_ 962 HCU_EVContnsDistance 0 "Vaild value" 254 "Vaild value" 255 "Invalid";
VAL_ 962 HCU_EVContnsDistanceVld 0 "Invalid" 1 "Valid";
VAL_ 962 HCU_EgyUsed 0 "Valid value" 1023 "Valid value";
SIG_GROUP_ 241 BMS4 1 : CheckSum_BMS4 BMS_PackCurr BMS_PackVolt BMS_PowerDownCmplt BMS_BattPoweErr BMS_ErrCategory RollingCounter_BMS4;
SIG_GROUP_ 566 DCT_FD4 1 : CheckSum_DCT7 DCT_RaceModeSts TRANS_OIL_TEMP DCT_PrsBrk_Warn DCT_ShftNotAlwd_Warn DCT_ShftRecom_M DrvWarnMsg DrvFaiMsg DrvModDisp DrvModDispSts TrsmStNID DrvGearDispSts DrvAutoGearDisp RollingCounter_DCT7;
SIG_GROUP_ 589 DMS2_DMS_FD1 1 : Checksum_DMS2 DistrctnLvlQlty_ACC DrowsnsLvlQlty_ACC DistrctnLvl_ACC DrowsnsLvl_ACC RollingCounter_DMS2;
SIG_GROUP_ 589 DMS3_DMS_FD1 1 : Checksum_DMS3 HeadPosnX HeadPosnY HeadPosnZ HeadPosQlty RollingCounter_DMS3;
SIG_GROUP_ 589 DMS5_DMS_FD1 1 : Checksum_DMS5 HeadYawAng HeadPitchAng HeadRollAng HeadRotAngQlty HeadDetn DMSSts RollingCounter_DMS5;
SIG_GROUP_ 589 DMS6_DMS_FD1 1 : Checksum_DMS6 RobustGazeYawAng RobustGazePitchAng LEyeOpenStsQlty REyeOpenStsQlty RobustGazeAngQlty LEyeOpenSts REyeOpenSts DrvBehvSts RollingCounter_DMS6;
SIG_GROUP_ 363 EPB1 1 : CheckSum_EPB1 PressBrakePedalPointOut EPBSts EPBErrSts EPBRedLmpSts EPBTextDisp RollingCounter_EPB1;
SIG_GROUP_ 327 EPS_FD1 1 : CheckSum_EPS1 EPS_FailSts EPS_SteerMod SteerCorrnRmn SteerCorrnResp RollingCounter_EPS1;
SIG_GROUP_ 311 ESP2_ESP_FD2 1 : CheckSum_ESP2 HDCCtrl HDCFault CDPActv AVHSts AVHErrSts DrivingModReq_ESP Over_Spd_Warn FourL_Warn DrivingModDis Shift_N_Warn TAB_Sts RollingCounter_ESP2;
SIG_GROUP_ 311 ESP1_ESP_FD2 1 : CheckSum_ESP1 ESPFailSts ESPActvInfoLmp ESPFuncOffSts IMC_Actv RollingCounter_ESP1;
SIG_GROUP_ 311 ABS3_ESP_FD2 1 : CheckSum_ABS3 ABSFailSts EBDFailSts VehSpdVld VehSpd ABSActv VehOdoInfoSts VehOdoInfo RollingCounter_ABS3;
SIG_GROUP_ 699 GW_FD1 1 : CheckSum_GWM1 OTA_UpgrdModSts RollingCounter_GWM1;
